VERSION "HNNBNNNYNNNNNNNNNNNNNNNNNNNNNNNNNNNNNNNNNN/4/%%%/4/'%**4NNN///"

NS_ :

BS_:

BU_: AFS AFS_LMod_L AFS_LMod_R BCM1 BVS FCM GLW_LMod_L GLW_LMod_R LCM_L LCM_R LED_DK3_LM_L LED_DK3_LM_R LED_LM_L LED_LM_R LLP_L LLP_R LWR_MXB_L LWR_MXB_R MXB MXB_LM_L MXB_LM_R ZFAS

BO_ 2600468649 NMH_FCM: 8 FCM
 SG_ NM_FCM_Car_Wakeup : 0|1@1+ (1,0) [0|1] "" Vector__XXX

BO_ 924 AFS_Feh_LM_L: 5 AFS_LMod_L
 SG_ FAL_SchMot : 0|1@1+ (1,0) [0|1] ""  AFS,BCM1,FCM
 SG_ FAL_RSchMot : 1|1@1+ (1,0) [0|1] ""  AFS,BCM1,FCM
 SG_ FAL_SM_KS_Gnd : 2|1@1+ (1,0) [0|1] ""  AFS,BCM1,FCM
 SG_ FAL_RSM_KS_Gnd : 3|1@1+ (1,0) [0|1] ""  AFS,BCM1,FCM
 SG_ FAL_SM_UeSpg : 4|1@1+ (1,0) [0|1] ""  AFS,BCM1,FCM
 SG_ FAL_RSM_UeSpg : 5|1@1+ (1,0) [0|1] ""  AFS,BCM1,FCM
 SG_ FAL_SM_USpg : 6|1@1+ (1,0) [0|1] ""  AFS,BCM1,FCM
 SG_ FAL_RSM_USpg : 7|1@1+ (1,0) [0|1] ""  AFS,BCM1,FCM
 SG_ FAL_SM_UeTemp : 8|1@1+ (1,0) [0|1] ""  AFS,BCM1,FCM
 SG_ FAL_RSM_UeTemp : 9|1@1+ (1,0) [0|1] ""  AFS,BCM1,FCM
 SG_ FAL_SM_TempPre : 10|1@1+ (1,0) [0|1] ""  AFS,BCM1,FCM
 SG_ FAL_RSM_TempPre : 11|1@1+ (1,0) [0|1] ""  AFS,BCM1,FCM
 SG_ FAL_EM_UeSpg : 12|1@1+ (1,0) [0|1] ""  AFS,BCM1,FCM
 SG_ FAL_REM_UeSpg : 13|1@1+ (1,0) [0|1] ""  AFS,BCM1,FCM
 SG_ FAL_EM_USpg : 14|1@1+ (1,0) [0|1] ""  AFS,BCM1,FCM
 SG_ FAL_REM_USpg : 15|1@1+ (1,0) [0|1] ""  AFS,BCM1,FCM
 SG_ FAL_EM_defekt : 16|1@1+ (1,0) [0|1] ""  AFS,BCM1,FCM
 SG_ FAL_REM_defekt : 17|1@1+ (1,0) [0|1] ""  AFS,BCM1,FCM
 SG_ FAL_sKL_Lampe : 18|1@1+ (1,0) [0|1] ""  AFS,BCM1,FCM
 SG_ FAL_RsKL_Lampe : 19|1@1+ (1,0) [0|1] ""  AFS,BCM1,FCM
 SG_ FAL_sKL_KS_Gnd : 20|1@1+ (1,0) [0|1] ""  AFS,BCM1,FCM
 SG_ FAL_RsKL_KS_Gnd : 21|1@1+ (1,0) [0|1] ""  AFS,BCM1,FCM
 SG_ FAL_GDL_Modul : 22|1@1+ (1,0) [0|1] ""  AFS,BCM1,FCM
 SG_ FAL_RGDL_Modul : 23|1@1+ (1,0) [0|1] ""  AFS,BCM1,FCM
 SG_ FAL_dKL_KS_Plus : 24|1@1+ (1,0) [0|1] ""  AFS,BCM1,FCM
 SG_ FAL_RdKL_KS_Plus : 25|1@1+ (1,0) [0|1] ""  AFS,BCM1,FCM
 SG_ FAL_dKL_KS_Gnd : 26|1@1+ (1,0) [0|1] ""  AFS,BCM1,FCM
 SG_ FAL_RdKL_KS_Gnd : 27|1@1+ (1,0) [0|1] ""  AFS,BCM1,FCM
 SG_ FAL_dKL_unplSign : 28|1@1+ (1,0) [0|1] ""  AFS,BCM1,FCM
 SG_ FAL_RdKL_unplSign : 29|1@1+ (1,0) [0|1] ""  AFS,BCM1,FCM
 SG_ FAL_5VdKL_KS_Gnd : 30|1@1+ (1,0) [0|1] ""  AFS,BCM1,FCM
 SG_ FAL_R5VdKL_KS_Gnd : 31|1@1+ (1,0) [0|1] ""  AFS,BCM1,FCM
 SG_ FAL_5VdKL_KS_UB : 32|1@1+ (1,0) [0|1] ""  AFS,BCM1,FCM
 SG_ FAL_R5VdKL_KS_UB : 33|1@1+ (1,0) [0|1] ""  AFS,BCM1,FCM

BO_ 926 AFS_Feh_LM_R: 5 AFS_LMod_R
 SG_ FAR_SchMot : 0|1@1+ (1,0) [0|1] ""  AFS,BCM1,FCM
 SG_ FAR_RSchMot : 1|1@1+ (1,0) [0|1] ""  AFS,BCM1,FCM
 SG_ FAR_SM_KS_Gnd : 2|1@1+ (1,0) [0|1] ""  AFS,BCM1,FCM
 SG_ FAR_RSM_KS_Gnd : 3|1@1+ (1,0) [0|1] ""  AFS,BCM1,FCM
 SG_ FAR_SM_UeSpg : 4|1@1+ (1,0) [0|1] ""  AFS,BCM1,FCM
 SG_ FAR_RSM_UeSpg : 5|1@1+ (1,0) [0|1] ""  AFS,BCM1,FCM
 SG_ FAR_SM_USpg : 6|1@1+ (1,0) [0|1] ""  AFS,BCM1,FCM
 SG_ FAR_RSM_USpg : 7|1@1+ (1,0) [0|1] ""  AFS,BCM1,FCM
 SG_ FAR_SM_UeTemp : 8|1@1+ (1,0) [0|1] ""  AFS,BCM1,FCM
 SG_ FAR_RSM_UeTemp : 9|1@1+ (1,0) [0|1] ""  AFS,BCM1,FCM
 SG_ FAR_SM_TempPre : 10|1@1+ (1,0) [0|1] ""  AFS,BCM1,FCM
 SG_ FAR_RSM_TempPre : 11|1@1+ (1,0) [0|1] ""  AFS,BCM1,FCM
 SG_ FAR_EM_UeSpg : 12|1@1+ (1,0) [0|1] ""  AFS,BCM1,FCM
 SG_ FAR_REM_UeSpg : 13|1@1+ (1,0) [0|1] ""  AFS,BCM1,FCM
 SG_ FAR_EM_USpg : 14|1@1+ (1,0) [0|1] ""  AFS,BCM1,FCM
 SG_ FAR_REM_USpg : 15|1@1+ (1,0) [0|1] ""  AFS,BCM1,FCM
 SG_ FAR_EM_defekt : 16|1@1+ (1,0) [0|1] ""  AFS,BCM1,FCM
 SG_ FAR_REM_defekt : 17|1@1+ (1,0) [0|1] ""  AFS,BCM1,FCM
 SG_ FAR_sKL_Lampe : 18|1@1+ (1,0) [0|1] ""  AFS,BCM1,FCM
 SG_ FAR_RsKL_Lampe : 19|1@1+ (1,0) [0|1] ""  AFS,BCM1,FCM
 SG_ FAR_sKL_KS_Gnd : 20|1@1+ (1,0) [0|1] ""  AFS,BCM1,FCM
 SG_ FAR_RsKL_KS_Gnd : 21|1@1+ (1,0) [0|1] ""  AFS,BCM1,FCM
 SG_ FAR_GDL_Modul : 22|1@1+ (1,0) [0|1] ""  AFS,BCM1,FCM
 SG_ FAR_RGDL_Modul : 23|1@1+ (1,0) [0|1] ""  AFS,BCM1,FCM
 SG_ FAR_dKL_KS_Plus : 24|1@1+ (1,0) [0|1] ""  AFS,BCM1,FCM
 SG_ FAR_RdKL_KS_Plus : 25|1@1+ (1,0) [0|1] ""  AFS,BCM1,FCM
 SG_ FAR_dKL_KS_Gnd : 26|1@1+ (1,0) [0|1] ""  AFS,BCM1,FCM
 SG_ FAR_RdKL_KS_Gnd : 27|1@1+ (1,0) [0|1] ""  AFS,BCM1,FCM
 SG_ FAR_dKL_unplSign : 28|1@1+ (1,0) [0|1] ""  AFS,BCM1,FCM
 SG_ FAR_RdKL_unplSign : 29|1@1+ (1,0) [0|1] ""  AFS,BCM1,FCM
 SG_ FAR_5VdKL_KS_Gnd : 30|1@1+ (1,0) [0|1] ""  AFS,BCM1,FCM
 SG_ FAR_R5VdKL_KS_Gnd : 31|1@1+ (1,0) [0|1] ""  AFS,BCM1,FCM
 SG_ FAR_5VdKL_KS_UB : 32|1@1+ (1,0) [0|1] ""  AFS,BCM1,FCM
 SG_ FAR_R5VdKL_KS_UB : 33|1@1+ (1,0) [0|1] ""  AFS,BCM1,FCM

BO_ 1172 AFS_Idt_LM_L: 8 AFS_LMod_L
 SG_ IAL_Mux M : 0|8@1+ (1,0) [0|4] ""  AFS,BCM1,FCM,MXB
 SG_ IAL_SW_Idt_Z01 m0 : 8|8@1+ (1,0) [0|255] ""  AFS,BCM1,FCM,MXB
 SG_ IAL_SW_Idt_Z08 m1 : 8|8@1+ (1,0) [0|255] ""  AFS,BCM1,FCM,MXB
 SG_ IAL_SW_Idx_Z04 m2 : 8|8@1+ (1,0) [0|255] ""  AFS,BCM1,FCM,MXB
 SG_ IAL_HW_Idt_Z07 m3 : 8|8@1+ (1,0) [0|255] ""  AFS,BCM1,FCM,MXB
 SG_ IAL_HW_Idx_Z03 m4 : 8|8@1+ (1,0) [0|255] ""  AFS,BCM1,FCM,MXB
 SG_ IAL_SW_Idt_Z02 m0 : 16|8@1+ (1,0) [0|255] ""  AFS,BCM1,FCM,MXB
 SG_ IAL_SW_Idt_Z09 m1 : 16|8@1+ (1,0) [0|255] ""  AFS,BCM1,FCM,MXB
 SG_ IAL_HW_Idt_Z01 m2 : 16|8@1+ (1,0) [0|255] ""  AFS,BCM1,FCM,MXB
 SG_ IAL_HW_Idt_Z08 m3 : 16|8@1+ (1,0) [0|255] ""  AFS,BCM1,FCM,MXB
 SG_ IAL_SW_Idt_Z03 m0 : 24|8@1+ (1,0) [0|255] ""  AFS,BCM1,FCM,MXB
 SG_ IAL_SW_Idt_Z10 m1 : 24|8@1+ (1,0) [0|255] ""  AFS,BCM1,FCM,MXB
 SG_ IAL_HW_Idt_Z02 m2 : 24|8@1+ (1,0) [0|255] ""  AFS,BCM1,FCM,MXB
 SG_ IAL_HW_Idt_Z09 m3 : 24|8@1+ (1,0) [0|255] ""  AFS,BCM1,FCM,MXB
 SG_ IAL_SW_Idt_Z04 m0 : 32|8@1+ (1,0) [0|255] ""  AFS,BCM1,FCM,MXB
 SG_ IAL_SW_Idt_Z11 m1 : 32|8@1+ (1,0) [0|255] ""  AFS,BCM1,FCM,MXB
 SG_ IAL_HW_Idt_Z03 m2 : 32|8@1+ (1,0) [0|255] ""  AFS,BCM1,FCM,MXB
 SG_ IAL_HW_Idt_Z10 m3 : 32|8@1+ (1,0) [0|255] ""  AFS,BCM1,FCM,MXB
 SG_ IAL_SW_Idt_Z05 m0 : 40|8@1+ (1,0) [0|255] ""  AFS,BCM1,FCM,MXB
 SG_ IAL_SW_Idx_Z01 m1 : 40|8@1+ (1,0) [0|255] ""  AFS,BCM1,FCM,MXB
 SG_ IAL_HW_Idt_Z04 m2 : 40|8@1+ (1,0) [0|255] ""  AFS,BCM1,FCM,MXB
 SG_ IAL_HW_Idt_Z11 m3 : 40|8@1+ (1,0) [0|255] ""  AFS,BCM1,FCM,MXB
 SG_ IAL_SW_Idt_Z06 m0 : 48|8@1+ (1,0) [0|255] ""  AFS,BCM1,FCM,MXB
 SG_ IAL_SW_Idx_Z02 m1 : 48|8@1+ (1,0) [0|255] ""  AFS,BCM1,FCM,MXB
 SG_ IAL_HW_Idt_Z05 m2 : 48|8@1+ (1,0) [0|255] ""  AFS,BCM1,FCM,MXB
 SG_ IAL_HW_Idx_Z01 m3 : 48|8@1+ (1,0) [0|255] ""  AFS,BCM1,FCM,MXB
 SG_ IAL_SW_Idt_Z07 m0 : 56|8@1+ (1,0) [0|255] ""  AFS,BCM1,FCM,MXB
 SG_ IAL_SW_Idx_Z03 m1 : 56|8@1+ (1,0) [0|255] ""  AFS,BCM1,FCM,MXB
 SG_ IAL_HW_Idt_Z06 m2 : 56|8@1+ (1,0) [0|255] ""  AFS,BCM1,FCM,MXB
 SG_ IAL_HW_Idx_Z02 m3 : 56|8@1+ (1,0) [0|255] ""  AFS,BCM1,FCM,MXB

BO_ 1174 AFS_Idt_LM_R: 8 AFS_LMod_R
 SG_ IAR_Mux M : 0|8@1+ (1,0) [0|4] ""  AFS,BCM1,FCM,MXB
 SG_ IAR_SW_Idt_Z01 m0 : 8|8@1+ (1,0) [0|255] ""  AFS,BCM1,FCM,MXB
 SG_ IAR_SW_Idt_Z08 m1 : 8|8@1+ (1,0) [0|255] ""  AFS,BCM1,FCM,MXB
 SG_ IAR_SW_Idx_Z04 m2 : 8|8@1+ (1,0) [0|255] ""  AFS,BCM1,FCM,MXB
 SG_ IAR_HW_Idt_Z07 m3 : 8|8@1+ (1,0) [0|255] ""  AFS,BCM1,FCM,MXB
 SG_ IAR_HW_Idx_Z03 m4 : 8|8@1+ (1,0) [0|255] ""  AFS,BCM1,FCM,MXB
 SG_ IAR_SW_Idt_Z02 m0 : 16|8@1+ (1,0) [0|255] ""  AFS,BCM1,FCM,MXB
 SG_ IAR_SW_Idt_Z09 m1 : 16|8@1+ (1,0) [0|255] ""  AFS,BCM1,FCM,MXB
 SG_ IAR_HW_Idt_Z01 m2 : 16|8@1+ (1,0) [0|255] ""  AFS,BCM1,FCM,MXB
 SG_ IAR_HW_Idt_Z08 m3 : 16|8@1+ (1,0) [0|255] ""  AFS,BCM1,FCM,MXB
 SG_ IAR_SW_Idt_Z03 m0 : 24|8@1+ (1,0) [0|255] ""  AFS,BCM1,FCM,MXB
 SG_ IAR_SW_Idt_Z10 m1 : 24|8@1+ (1,0) [0|255] ""  AFS,BCM1,FCM,MXB
 SG_ IAR_HW_Idt_Z02 m2 : 24|8@1+ (1,0) [0|255] ""  AFS,BCM1,FCM,MXB
 SG_ IAR_HW_Idt_Z09 m3 : 24|8@1+ (1,0) [0|255] ""  AFS,BCM1,FCM,MXB
 SG_ IAR_SW_Idt_Z04 m0 : 32|8@1+ (1,0) [0|255] ""  AFS,BCM1,FCM,MXB
 SG_ IAR_SW_Idt_Z11 m1 : 32|8@1+ (1,0) [0|255] ""  AFS,BCM1,FCM,MXB
 SG_ IAR_HW_Idt_Z03 m2 : 32|8@1+ (1,0) [0|255] ""  AFS,BCM1,FCM,MXB
 SG_ IAR_HW_Idt_Z10 m3 : 32|8@1+ (1,0) [0|255] ""  AFS,BCM1,FCM,MXB
 SG_ IAR_SW_Idt_Z05 m0 : 40|8@1+ (1,0) [0|255] ""  AFS,BCM1,FCM,MXB
 SG_ IAR_SW_Idx_Z01 m1 : 40|8@1+ (1,0) [0|255] ""  AFS,BCM1,FCM,MXB
 SG_ IAR_HW_Idt_Z04 m2 : 40|8@1+ (1,0) [0|255] ""  AFS,BCM1,FCM,MXB
 SG_ IAR_HW_Idt_Z11 m3 : 40|8@1+ (1,0) [0|255] ""  AFS,BCM1,FCM,MXB
 SG_ IAR_SW_Idt_Z06 m0 : 48|8@1+ (1,0) [0|255] ""  AFS,BCM1,FCM,MXB
 SG_ IAR_SW_Idx_Z02 m1 : 48|8@1+ (1,0) [0|255] ""  AFS,BCM1,FCM,MXB
 SG_ IAR_HW_Idt_Z05 m2 : 48|8@1+ (1,0) [0|255] ""  AFS,BCM1,FCM,MXB
 SG_ IAR_HW_Idx_Z01 m3 : 48|8@1+ (1,0) [0|255] ""  AFS,BCM1,FCM,MXB
 SG_ IAR_SW_Idt_Z07 m0 : 56|8@1+ (1,0) [0|255] ""  AFS,BCM1,FCM,MXB
 SG_ IAR_SW_Idx_Z03 m1 : 56|8@1+ (1,0) [0|255] ""  AFS,BCM1,FCM,MXB
 SG_ IAR_HW_Idt_Z06 m2 : 56|8@1+ (1,0) [0|255] ""  AFS,BCM1,FCM,MXB
 SG_ IAR_HW_Idx_Z02 m3 : 56|8@1+ (1,0) [0|255] ""  AFS,BCM1,FCM,MXB

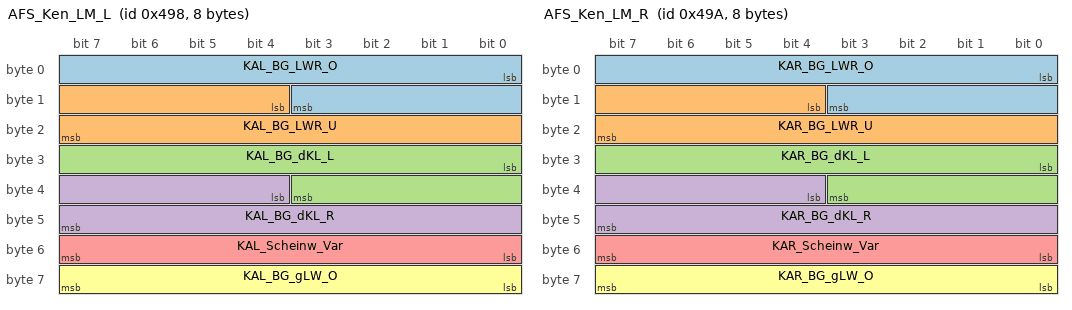
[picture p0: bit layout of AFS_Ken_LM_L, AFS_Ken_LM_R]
BO_ 1176 AFS_Ken_LM_L: 8 AFS_LMod_L
 SG_ KAL_BG_LWR_O : 0|12@1+ (0.5,-1023) [-1023|1022.5] "Unit_MilliMeter"  AFS,BCM1,FCM,MXB
 SG_ KAL_BG_LWR_U : 12|12@1+ (0.5,-1023) [-1023|1022.5] "Unit_MilliMeter"  AFS,BCM1,FCM,MXB
 SG_ KAL_BG_dKL_L : 24|12@1+ (0.015625,-31.96875) [-31.96875|31.953125] "Unit_DegreOfArc"  AFS,BCM1,FCM
 SG_ KAL_BG_dKL_R : 36|12@1+ (0.015625,-31.96875) [-31.96875|31.953125] "Unit_DegreOfArc"  AFS,BCM1,FCM
 SG_ KAL_Scheinw_Var : 48|8@1+ (1,0) [0|255] ""  AFS,BCM1,FCM
 SG_ KAL_BG_gLW_O : 56|8@1+ (0.1,75) [75|100] "Unit_PerCent"  AFS,BCM1,FCM

BO_ 1184 AFS_Ken_LM_L_02: 8 AFS_LMod_L
 SG_ AFS_L_Scheinw_Var_1 : 12|8@1+ (1,0) [0|255] ""  AFS,BCM1,FCM
 SG_ AFS_L_Scheinw_Var_2 : 20|8@1+ (1,0) [0|255] ""  AFS,BCM1,FCM

BO_ 1178 AFS_Ken_LM_R: 8 AFS_LMod_R
 SG_ KAR_BG_LWR_O : 0|12@1+ (0.5,-1023) [-1023|1022.5] "Unit_MilliMeter"  AFS,BCM1,FCM,MXB
 SG_ KAR_BG_LWR_U : 12|12@1+ (0.5,-1023) [-1023|1022.5] "Unit_MilliMeter"  AFS,BCM1,FCM,MXB
 SG_ KAR_BG_dKL_L : 24|12@1+ (0.015625,-31.96875) [-31.96875|31.953125] "Unit_DegreOfArc"  AFS,BCM1,FCM
 SG_ KAR_BG_dKL_R : 36|12@1+ (0.015625,-31.96875) [-31.96875|31.953125] "Unit_DegreOfArc"  AFS,BCM1,FCM
 SG_ KAR_Scheinw_Var : 48|8@1+ (1,0) [0|255] ""  AFS,BCM1,FCM
 SG_ KAR_BG_gLW_O : 56|8@1+ (0.1,75) [75|100] "Unit_PerCent"  AFS,BCM1,FCM

BO_ 1185 AFS_Ken_LM_R_02: 8 AFS_LMod_R
 SG_ AFS_R_Scheinw_Var_1 : 12|8@1+ (1,0) [0|255] ""  AFS,BCM1,FCM
 SG_ AFS_R_Scheinw_Var_2 : 20|8@1+ (1,0) [0|255] ""  AFS,BCM1,FCM

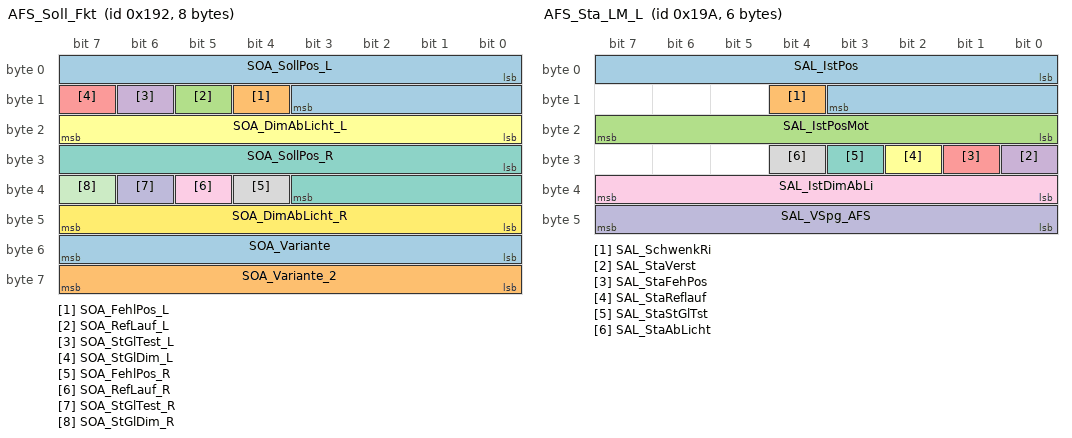
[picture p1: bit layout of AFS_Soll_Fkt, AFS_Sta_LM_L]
BO_ 402 AFS_Soll_Fkt: 8 AFS
 SG_ SOA_SollPos_L : 0|12@1+ (0.015625,-31.96875) [-31.96875|31.953125] "Unit_DegreOfArc"  AFS_LMod_L,BVS,GLW_LMod_L,LCM_L,LLP_L,ZFAS
 SG_ SOA_FehlPos_L : 12|1@1+ (1,0) [0|1] ""  AFS_LMod_L,BVS,GLW_LMod_L,LCM_L,LLP_L,ZFAS
 SG_ SOA_RefLauf_L : 13|1@1+ (1,0) [0|1] ""  AFS_LMod_L,BVS,GLW_LMod_L,LCM_L,LLP_L,ZFAS
 SG_ SOA_StGlTest_L : 14|1@1+ (1,0) [0|1] ""  AFS_LMod_L,BVS,GLW_LMod_L,LCM_L,LLP_L,ZFAS
 SG_ SOA_StGlDim_L : 15|1@1+ (1,0) [0|1] ""  AFS_LMod_L,BVS,GLW_LMod_L,LCM_L,LLP_L,ZFAS
 SG_ SOA_DimAbLicht_L : 16|8@1+ (0.4,0) [0|100] "Unit_PerCent"  AFS_LMod_L,BVS,GLW_LMod_L,LCM_L,LLP_L,ZFAS
 SG_ SOA_SollPos_R : 24|12@1+ (0.015625,-31.96875) [-31.96875|31.953125] "Unit_DegreOfArc"  AFS_LMod_R,BVS,GLW_LMod_R,LCM_R,LLP_R,ZFAS
 SG_ SOA_FehlPos_R : 36|1@1+ (1,0) [0|1] ""  AFS_LMod_R,BVS,GLW_LMod_R,LCM_R,LLP_R,ZFAS
 SG_ SOA_RefLauf_R : 37|1@1+ (1,0) [0|1] ""  AFS_LMod_R,BVS,GLW_LMod_R,LCM_R,LLP_R,ZFAS
 SG_ SOA_StGlTest_R : 38|1@1+ (1,0) [0|1] ""  AFS_LMod_R,BVS,GLW_LMod_R,LCM_R,LLP_R,ZFAS
 SG_ SOA_StGlDim_R : 39|1@1+ (1,0) [0|1] ""  AFS_LMod_R,BVS,GLW_LMod_R,LCM_R,LLP_R,ZFAS
 SG_ SOA_DimAbLicht_R : 40|8@1+ (0.4,0) [0|100] "Unit_PerCent"  AFS_LMod_R,BVS,GLW_LMod_R,LCM_R,LLP_R,ZFAS
 SG_ SOA_Variante : 48|8@1+ (1,0) [0|255] ""  AFS_LMod_L,AFS_LMod_R,BVS,GLW_LMod_L,GLW_LMod_R,LCM_L,LCM_R,LED_DK3_LM_L,LED_DK3_LM_R,LED_LM_L,LED_LM_R,LLP_L,LLP_R,LWR_MXB_L,LWR_MXB_R,MXB_LM_L,MXB_LM_R,ZFAS
 SG_ SOA_Variante_2 : 56|8@1+ (1,0) [0|255] ""  AFS_LMod_L,AFS_LMod_R,BVS,GLW_LMod_L,GLW_LMod_R,LCM_L,LCM_R,LED_DK3_LM_L,LED_DK3_LM_R,LED_LM_L,LED_LM_R,LLP_L,LLP_R,LWR_MXB_L,LWR_MXB_R,MXB_LM_L,MXB_LM_R,ZFAS

BO_ 410 AFS_Sta_LM_L: 6 AFS_LMod_L
 SG_ SAL_IstPos : 0|12@1+ (0.015625,-31.96875) [-31.96875|31.953125] "Unit_DegreOfArc"  AFS,BCM1,FCM
 SG_ SAL_SchwenkRi : 12|1@1+ (1,0) [0|1] ""  AFS,BCM1,FCM
 SG_ SAL_IstPosMot : 16|8@1+ (0.4,0) [0|100] "Unit_PerCent"  AFS,BCM1,FCM
 SG_ SAL_StaVerst : 24|1@1+ (1,0) [0|1] ""  AFS,BCM1,FCM
 SG_ SAL_StaFehPos : 25|1@1+ (1,0) [0|1] ""  AFS,BCM1,FCM
 SG_ SAL_StaReflauf : 26|1@1+ (1,0) [0|1] ""  AFS,BCM1,FCM
 SG_ SAL_StaStGlTst : 27|1@1+ (1,0) [0|1] ""  AFS,BCM1,FCM
 SG_ SAL_StaAbLicht : 28|1@1+ (1,0) [0|1] ""  AFS,BCM1,FCM
 SG_ SAL_IstDimAbLi : 32|8@1+ (0.4,0) [0|100] "Unit_PerCent"  AFS,BCM1,FCM
 SG_ SAL_VSpg_AFS : 40|8@1+ (0.08,0) [0|20.24] "Unit_Volt"  AFS,BCM1,FCM

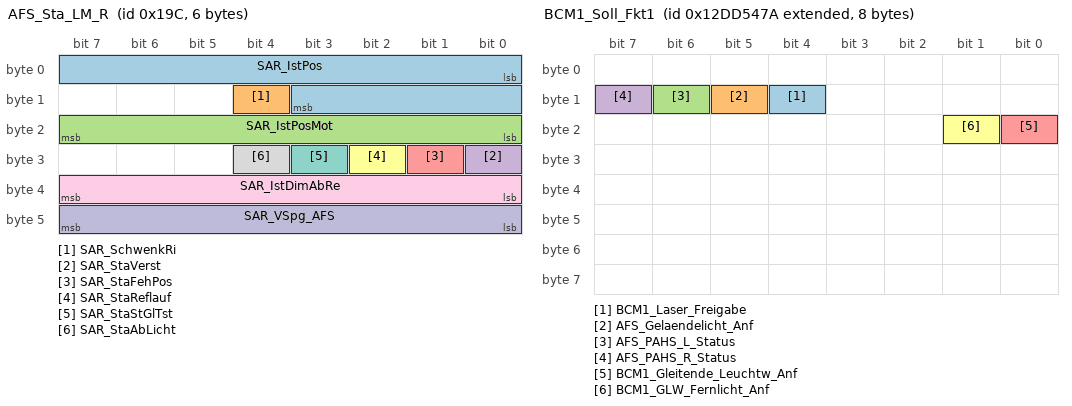
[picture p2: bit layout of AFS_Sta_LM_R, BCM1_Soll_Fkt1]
BO_ 412 AFS_Sta_LM_R: 6 AFS_LMod_R
 SG_ SAR_IstPos : 0|12@1+ (0.015625,-31.96875) [-31.96875|31.953125] "Unit_DegreOfArc"  AFS,BCM1,FCM
 SG_ SAR_SchwenkRi : 12|1@1+ (1,0) [0|1] ""  AFS,BCM1,FCM
 SG_ SAR_IstPosMot : 16|8@1+ (0.4,0) [0|100] "Unit_PerCent"  AFS,BCM1,FCM
 SG_ SAR_StaVerst : 24|1@1+ (1,0) [0|1] ""  AFS,BCM1,FCM
 SG_ SAR_StaFehPos : 25|1@1+ (1,0) [0|1] ""  AFS,BCM1,FCM
 SG_ SAR_StaReflauf : 26|1@1+ (1,0) [0|1] ""  AFS,BCM1,FCM
 SG_ SAR_StaStGlTst : 27|1@1+ (1,0) [0|1] ""  AFS,BCM1,FCM
 SG_ SAR_StaAbLicht : 28|1@1+ (1,0) [0|1] ""  AFS,BCM1,FCM
 SG_ SAR_IstDimAbRe : 32|8@1+ (0.4,0) [0|100] "Unit_PerCent"  AFS,BCM1,FCM
 SG_ SAR_VSpg_AFS : 40|8@1+ (0.08,0) [0|20.24] "Unit_Volt"  AFS,BCM1,FCM

BO_ 64 Airbag_01: 8 BCM1
 SG_ Airbag_01_CRC : 0|8@1+ (1,0) [0|255] ""  LED_DK3_LM_L,LED_DK3_LM_R,LLP_L,LLP_R
 SG_ Airbag_01_BZ : 8|4@1+ (1,0) [0|15] ""  LED_DK3_LM_L,LED_DK3_LM_R,LLP_L,LLP_R
 SG_ AB_RGS_Anst : 12|4@1+ (1,0) [0|15] "" Vector__XXX
 SG_ AB_Front_Crash : 16|1@1+ (1,0) [0|1] ""  LED_DK3_LM_L,LED_DK3_LM_R,LLP_L,LLP_R
 SG_ AB_Heck_Crash : 17|1@1+ (1,0) [0|1] "" Vector__XXX
 SG_ AB_SF_Crash : 18|1@1+ (1,0) [0|1] "" Vector__XXX
 SG_ AB_SB_Crash : 19|1@1+ (1,0) [0|1] "" Vector__XXX
 SG_ AB_Rollover_Crash : 20|1@1+ (1,0) [0|1] "" Vector__XXX
 SG_ AB_Crash_Int : 21|3@1+ (1,0) [0|7] ""  LED_DK3_LM_L,LED_DK3_LM_R,LLP_L,LLP_R
 SG_ AB_Lampe : 24|1@1+ (1,0) [0|1] "" Vector__XXX
 SG_ AB_Deaktiviert : 25|1@1+ (1,0) [0|1] "" Vector__XXX
 SG_ AB_VB_deaktiviert : 26|1@1+ (1,0) [0|1] "" Vector__XXX
 SG_ AB_Systemfehler : 27|1@1+ (1,0) [0|1] "" Vector__XXX
 SG_ AB_Diagnose : 28|1@1+ (1,0) [0|1] ""  LED_DK3_LM_L,LED_DK3_LM_R,LLP_L,LLP_R
 SG_ AB_Stellgliedtest : 29|1@1+ (1,0) [0|1] ""  LED_DK3_LM_L,LED_DK3_LM_R,LLP_L,LLP_R
 SG_ AB_Erh_Auf_VB : 30|2@1+ (1,0) [0|3] ""  LED_DK3_LM_L,LED_DK3_LM_R,LLP_L,LLP_R
 SG_ AB_Gurtwarn_VF : 32|1@1+ (1,0) [0|1] "" Vector__XXX
 SG_ AB_Gurtwarn_VB : 33|1@1+ (1,0) [0|1] "" Vector__XXX
 SG_ AB_Anzeige_Fussg : 34|2@1+ (1,0) [0|3] "" Vector__XXX
 SG_ AB_Texte_AKS : 36|2@1+ (1,0) [0|3] "" Vector__XXX
 SG_ AB_MKB_gueltig : 39|1@1+ (1,0) [0|1] "" Vector__XXX
 SG_ AB_MKB_Anforderung : 40|1@1+ (1,0) [0|1] "" Vector__XXX
 SG_ AB_Versorgungsspannung : 41|1@1+ (1,0) [0|1] "" Vector__XXX
 SG_ AB_Deaktivierung_HV : 42|3@1+ (1,0) [0|7] "" Vector__XXX
 SG_ AB_EDR_Trigger : 45|2@1+ (1,0) [0|3] "" Vector__XXX
 SG_ SC_Masterzeit_Offset : 53|2@1+ (5.08,0) [0|15.24] "Unit_Secon" Vector__XXX
 SG_ SC_LowSpeedCrashErkannt : 55|2@1+ (1,0) [0|3] "" Vector__XXX
 SG_ SC_Masterzeit : 57|7@1+ (0.04,0) [0|5.04] "Unit_Secon" Vector__XXX

BO_ 2463978618 BCM1_Soll_Fkt1: 8 BCM1
 SG_ BCM1_Laser_Freigabe : 12|1@1+ (1,0) [0|1] ""  ZFAS
 SG_ AFS_Gelaendelicht_Anf : 13|1@1+ (1,0) [0|1] ""  ZFAS
 SG_ AFS_PAHS_L_Status : 14|1@1+ (1,0) [0|1] ""  ZFAS
 SG_ AFS_PAHS_R_Status : 15|1@1+ (1,0) [0|1] ""  ZFAS
 SG_ BCM1_Gleitende_Leuchtw_Anf : 16|1@1+ (1,0) [0|1] ""  ZFAS
 SG_ BCM1_GLW_Fernlicht_Anf : 17|1@1+ (1,0) [0|1] ""  ZFAS

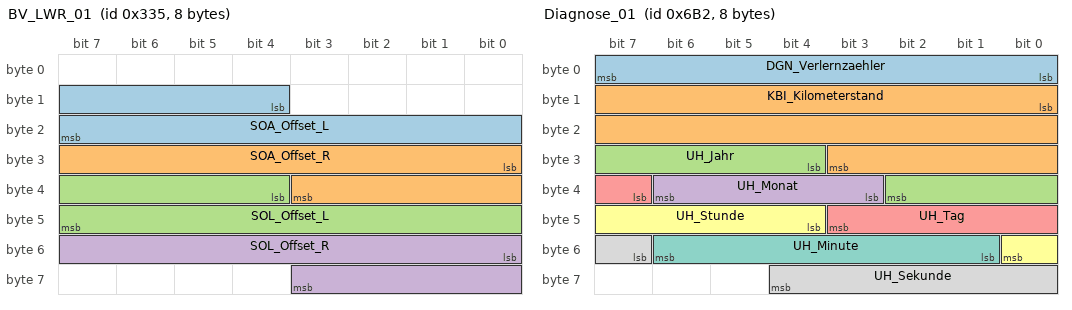
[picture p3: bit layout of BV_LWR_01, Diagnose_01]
BO_ 821 BV_LWR_01: 8 BVS
 SG_ SOA_Offset_L : 12|12@1+ (0.015626,-2046) [-2046|-1982.074034] "Unit_DegreOfArc"  BCM1
 SG_ SOA_Offset_R : 24|12@1+ (0.015626,-2046) [-2046|-1982.074034] "Unit_DegreOfArc"  BCM1
 SG_ SOL_Offset_L : 36|12@1+ (0.5,-1023) [-1023|1022.5] "Unit_MilliMeter"  BCM1
 SG_ SOL_Offset_R : 48|12@1+ (0.5,-1023) [-1023|1022.5] "Unit_MilliMeter"  BCM1

BO_ 2616988416 DEV_LCM_L_00: 8 LCM_L
 SG_ DEV_LCM_L_00_Data : 0|64@1+ (1,0) [0|1.84467440737096E+019] "" Vector__XXX

BO_ 2616988671 DEV_LCM_L_FF: 8 LCM_L
 SG_ DEV_LCM_L_FF_Data : 0|64@1+ (1,0) [0|1.84467440737096E+019] "" Vector__XXX

BO_ 2616990464 DEV_LCM_R_00: 8 LCM_R
 SG_ DEV_LCM_R_00_Data : 0|64@1+ (1,0) [0|1.84467440737096E+019] "" Vector__XXX

BO_ 2616990719 DEV_LCM_R_FF: 8 LCM_R
 SG_ DEV_LCM_R_FF_Data : 0|64@1+ (1,0) [0|1.84467440737096E+019] "" Vector__XXX

BO_ 2617029376 DEV_LED_DK3_L_00: 8 LED_DK3_LM_L
 SG_ DEV_LED_DK3_L_00_Data : 0|64@1+ (1,0) [0|1.84467440737096E+019] "" Vector__XXX

BO_ 2617029631 DEV_LED_DK3_L_FF: 8 LED_DK3_LM_L
 SG_ DEV_LED_DK3_L_FF_Data : 0|64@1+ (1,0) [0|1.84467440737096E+019] "" Vector__XXX

BO_ 2617031424 DEV_LED_DK3_R_00: 8 LED_DK3_LM_R
 SG_ DEV_LED_DK3_R_00_Data : 0|64@1+ (1,0) [0|1.84467440737096E+019] "" Vector__XXX

BO_ 2617031679 DEV_LED_DK3_R_FF: 8 LED_DK3_LM_R
 SG_ DEV_LED_DK3_R_FF_Data : 0|64@1+ (1,0) [0|1.84467440737096E+019] "" Vector__XXX

BO_ 2549880340 DIA_gLW_LM_L_Req: 8 AFS
 SG_ DIA_gLW_LM_L_Req_Data : 0|64@1+ (1,0) [0|1.84467440737096E+019] ""  GLW_LMod_L

BO_ 2550011412 DIA_gLW_LM_L_Resp: 8 GLW_LMod_L
 SG_ DIA_gLW_LM_L_Resp_Data : 0|64@1+ (1,0) [0|1.84467440737096E+019] ""  AFS,BCM1

BO_ 2549880341 DIA_gLW_LM_R_Req: 8 AFS
 SG_ DIA_gLW_LM_R_Req_Data : 0|64@1+ (1,0) [0|1.84467440737096E+019] ""  GLW_LMod_R

BO_ 2550011413 DIA_gLW_LM_R_Resp: 8 GLW_LMod_R
 SG_ DIA_gLW_LM_R_Resp_Data : 0|64@1+ (1,0) [0|1.84467440737096E+019] ""  AFS,BCM1

BO_ 2549880330 DIA_LED_LM_L_Req: 8 AFS
 SG_ DIA_LED_LM_L_Req_Data : 0|64@1+ (1,0) [0|1.84467440737096E+019] ""  LED_DK3_LM_L,LED_LM_L

BO_ 2550011402 DIA_LED_LM_L_Resp: 8 LED_DK3_LM_L
 SG_ DIA_LED_LM_L_Resp_Data : 0|64@1+ (1,0) [0|1.84467440737096E+019] ""  AFS,BCM1,FCM,MXB

BO_ 2549880331 DIA_LED_LM_R_Req: 8 AFS
 SG_ DIA_LED_LM_R_Req_Data : 0|64@1+ (1,0) [0|1.84467440737096E+019] ""  LED_DK3_LM_R,LED_LM_R

BO_ 2550011403 DIA_LED_LM_R_Resp: 8 LED_DK3_LM_R
 SG_ DIA_LED_LM_R_Resp_Data : 0|64@1+ (1,0) [0|1.84467440737096E+019] ""  AFS,BCM1,FCM,MXB

BO_ 2549880427 DIA_MXB_LM_L_Req: 8 AFS
 SG_ DIA_MXB_LM_L_Req_Data : 0|64@1+ (1,0) [0|1.84467440737096E+019] ""  MXB_LM_L

BO_ 2550011499 DIA_MXB_LM_L_Resp: 8 MXB_LM_L
 SG_ DIA_MXB_LM_L_Resp_Data : 0|64@1+ (1,0) [0|1.84467440737096E+019] ""  AFS,BCM1,FCM,MXB

BO_ 2549880428 DIA_MXB_LM_R_Req: 8 AFS
 SG_ DIA_MXB_LM_R_Req_Data : 0|64@1+ (1,0) [0|1.84467440737096E+019] ""  MXB_LM_R

BO_ 2550011500 DIA_MXB_LM_R_Resp: 8 MXB_LM_R
 SG_ DIA_MXB_LM_R_Resp_Data : 0|64@1+ (1,0) [0|1.84467440737096E+019] ""  AFS,BCM1,FCM,MXB

BO_ 1714 Diagnose_01: 8 AFS
 SG_ DGN_Verlernzaehler : 0|8@1+ (1,0) [0|254] ""  LCM_L,LCM_R,LED_DK3_LM_L,LED_DK3_LM_R,LLP_L,LLP_R
 SG_ KBI_Kilometerstand : 8|20@1+ (1,0) [0|1048573] "Unit_KiloMeter"  LCM_L,LCM_R,LED_DK3_LM_L,LED_DK3_LM_R,LLP_L,LLP_R
 SG_ UH_Jahr : 28|7@1+ (1,2000) [2000|2127] "Unit_Year"  LCM_L,LCM_R,LED_DK3_LM_L,LED_DK3_LM_R,LLP_L,LLP_R
 SG_ UH_Monat : 35|4@1+ (1,0) [1|12] "Unit_Month"  LCM_L,LCM_R,LED_DK3_LM_L,LED_DK3_LM_R,LLP_L,LLP_R
 SG_ UH_Tag : 39|5@1+ (1,0) [1|31] "Unit_Day"  LCM_L,LCM_R,LED_DK3_LM_L,LED_DK3_LM_R,LLP_L,LLP_R
 SG_ UH_Stunde : 44|5@1+ (1,0) [0|23] "Unit_Hours"  LCM_L,LCM_R,LED_DK3_LM_L,LED_DK3_LM_R,LLP_L,LLP_R
 SG_ UH_Minute : 49|6@1+ (1,0) [0|59] "Unit_Minut"  LCM_L,LCM_R,LED_DK3_LM_L,LED_DK3_LM_R,LLP_L,LLP_R
 SG_ UH_Sekunde : 55|6@1+ (1,0) [0|59] "Unit_Secon"  LCM_L,LCM_R,LED_DK3_LM_L,LED_DK3_LM_R,LLP_L,LLP_R

BO_ 253 ESP_21: 8 AFS
 SG_ ESP_21_CRC : 0|8@1+ (1,0) [0|255] ""  LED_DK3_LM_L,LED_DK3_LM_R,LLP_L,LLP_R
 SG_ ESP_21_BZ : 8|4@1+ (1,0) [0|15] ""  LED_DK3_LM_L,LED_DK3_LM_R,LLP_L,LLP_R
 SG_ BR_Eingriffsmoment : 12|10@1+ (1,-509) [-509|509] "" Vector__XXX
 SG_ ESP_PLA_Bremseingriff : 22|1@1+ (1,0) [0|1] "" Vector__XXX
 SG_ ESP_Diagnose : 23|1@1+ (1,0) [0|1] "" Vector__XXX
 SG_ ESC_v_Signal_Qualifier_High_Low : 24|3@1+ (1,0) [0|7] ""  LED_DK3_LM_L,LED_DK3_LM_R,LLP_L,LLP_R
 SG_ ESP_Vorsteuerung : 28|1@1+ (1,0) [0|1] "" Vector__XXX
 SG_ OBD_Schlechtweg : 30|1@1+ (1,0) [0|1] "" Vector__XXX
 SG_ OBD_QBit_Schlechtweg : 31|1@1+ (1,0) [0|1] "" Vector__XXX
 SG_ ESP_v_Signal : 32|16@1+ (0.01,0) [0|655.32] "Unit_KiloMeterPerHour"  LCM_L,LCM_R,LED_DK3_LM_L,LED_DK3_LM_R,LLP_L,LLP_R
 SG_ ASR_Tastung_passiv : 48|1@1+ (1,0) [0|1] "" Vector__XXX
 SG_ ESP_Tastung_passiv : 49|1@1+ (1,0) [0|1] "" Vector__XXX
 SG_ ESP_Systemstatus : 50|1@1+ (1,0) [0|1] "" Vector__XXX
 SG_ ASR_Schalteingriff : 51|2@1+ (1,0) [0|3] "" Vector__XXX
 SG_ ESP_Haltebestaetigung : 53|1@1+ (1,0) [0|1] "" Vector__XXX
 SG_ ESP_MKB_Abbruch_Geschw : 54|1@1+ (1,0) [0|1] "" Vector__XXX
 SG_ ESP_QBit_v_Signal : 55|1@1+ (1,0) [0|1] "" Vector__XXX
 SG_ ABS_Bremsung : 56|1@1+ (1,0) [0|1] "" Vector__XXX
 SG_ ASR_Anf : 57|1@1+ (1,0) [0|1] "" Vector__XXX
 SG_ MSR_Anf : 58|1@1+ (1,0) [0|1] "" Vector__XXX
 SG_ EBV_Eingriff : 59|1@1+ (1,0) [0|1] "" Vector__XXX
 SG_ EDS_Eingriff : 60|1@1+ (1,0) [0|1] "" Vector__XXX
 SG_ ESP_Eingriff : 61|1@1+ (1,0) [0|1] "" Vector__XXX
 SG_ ESP_ASP : 62|1@1+ (1,0) [0|1] "" Vector__XXX

BO_ 918 GLW_Feh_LM_L: 5 GLW_LMod_L
 SG_ FGL_Akt_KS_Plus : 0|1@1+ (1,0) [0|1] ""  AFS,BCM1,FCM
 SG_ FGL_RAkt_KS_Plus : 1|1@1+ (1,0) [0|1] ""  AFS,BCM1,FCM
 SG_ FGL_Akt_KS_Gnd : 2|1@1+ (1,0) [0|1] ""  AFS,BCM1,FCM
 SG_ FGL_RAkt_KS_Gnd : 3|1@1+ (1,0) [0|1] ""  AFS,BCM1,FCM
 SG_ FGL_Akt_OL : 4|1@1+ (1,0) [0|1] ""  AFS,BCM1,FCM
 SG_ FGL_RAkt_OL : 5|1@1+ (1,0) [0|1] ""  AFS,BCM1,FCM
 SG_ FGL_Akt_UeSpg : 6|1@1+ (1,0) [0|1] ""  AFS,BCM1,FCM
 SG_ FGL_RAkt_UeSpg : 7|1@1+ (1,0) [0|1] ""  AFS,BCM1,FCM
 SG_ FGL_Akt_USpg : 8|1@1+ (1,0) [0|1] ""  AFS,BCM1,FCM
 SG_ FGL_RAkt_USpg : 9|1@1+ (1,0) [0|1] ""  AFS,BCM1,FCM
 SG_ FGL_Akt_UeTemp : 10|1@1+ (1,0) [0|1] ""  AFS,BCM1,FCM
 SG_ FGL_RAkt_UeTemp : 11|1@1+ (1,0) [0|1] ""  AFS,BCM1,FCM
 SG_ FGL_Akt_TempPre : 12|1@1+ (1,0) [0|1] ""  AFS,BCM1,FCM
 SG_ FGL_RAkt_TempPre : 13|1@1+ (1,0) [0|1] ""  AFS,BCM1,FCM
 SG_ FGL_HS_KS_Plus : 18|1@1+ (1,0) [0|1] ""  AFS,BCM1,FCM
 SG_ FGL_RHS_KS_Plus : 19|1@1+ (1,0) [0|1] ""  AFS,BCM1,FCM
 SG_ FGL_HS_KS_Gnd : 20|1@1+ (1,0) [0|1] ""  AFS,BCM1,FCM
 SG_ FGL_RHS_KS_Gnd : 21|1@1+ (1,0) [0|1] ""  AFS,BCM1,FCM
 SG_ FGL_HS_unplSign : 22|1@1+ (1,0) [0|1] ""  AFS,BCM1,FCM
 SG_ FGL_RHS_unplSign : 23|1@1+ (1,0) [0|1] ""  AFS,BCM1,FCM
 SG_ FGL_LIN_Def : 24|1@1+ (1,0) [0|1] ""  AFS,BCM1,FCM
 SG_ FGL_LIN_Timeout : 25|1@1+ (1,0) [0|1] ""  AFS,BCM1,FCM
 SG_ FGL_RLIN_Def : 26|1@1+ (1,0) [0|1] ""  AFS,BCM1,FCM
 SG_ FGL_RLIN_Timeout : 27|1@1+ (1,0) [0|1] ""  AFS,BCM1,FCM

BO_TX_BU_ 924 : AFS_LMod_L,GLW_LMod_L,LWR_MXB_L;
BO_TX_BU_ 926 : AFS_LMod_R,GLW_LMod_R;
BO_TX_BU_ 1172 : AFS_LMod_L,GLW_LMod_L,LWR_MXB_L;
BO_TX_BU_ 1174 : AFS_LMod_R,GLW_LMod_R,LWR_MXB_R;
BO_TX_BU_ 1176 : AFS_LMod_L,GLW_LMod_L,LWR_MXB_L;
BO_TX_BU_ 1184 : AFS_LMod_L,GLW_LMod_L,LWR_MXB_L;
BO_TX_BU_ 1178 : AFS_LMod_R,GLW_LMod_R,LWR_MXB_R;
BO_TX_BU_ 1185 : AFS_LMod_R,GLW_LMod_R,LWR_MXB_R;
BO_TX_BU_ 402 : AFS,BCM1,FCM,MXB;
BO_TX_BU_ 410 : AFS_LMod_L,GLW_LMod_L,LCM_L,LLP_L,LWR_MXB_L;
BO_TX_BU_ 412 : AFS_LMod_R,GLW_LMod_R,LCM_R,LLP_R,LWR_MXB_R;
BO_TX_BU_ 821 : BVS,ZFAS;
BO_TX_BU_ 2617029376 : LED_DK3_LM_L,LLP_L;
BO_TX_BU_ 2617029631 : LED_DK3_LM_L,LLP_L;
BO_TX_BU_ 2617031424 : LED_DK3_LM_R,LLP_R;
BO_TX_BU_ 2617031679 : LED_DK3_LM_R,LLP_R;
BO_TX_BU_ 2549880340 : AFS,BCM1;
BO_TX_BU_ 2549880341 : AFS,BCM1;
BO_TX_BU_ 2549880330 : AFS,BCM1,FCM,MXB;
BO_TX_BU_ 2549880331 : AFS,BCM1,FCM,MXB;
BO_TX_BU_ 2549880427 : AFS,BCM1,FCM,MXB;
BO_TX_BU_ 2549880428 : AFS,BCM1,FCM,MXB;
BO_TX_BU_ 1714 : AFS,BCM1,FCM,MXB;
BO_TX_BU_ 253 : AFS,BCM1,FCM,MXB;

CM_ "AFSCAN_V1.11F Generated by BUSNET NG Produktiv 9.4.2";
CM_ BU_ AFS_LMod_L "Bei Änderungen immer Rücksprache mit Fachabteilung (bestehende Module in Serie)";
CM_ BU_ AFS_LMod_R "Bei Änderungen immer Rücksprache mit Fachabteilung (bestehende Module in Serie)";
CM_ BU_ BVS "Bildverarbeitungssteuergerät";
CM_ BU_ FCM "Function Control Module";
CM_ BU_ GLW_LMod_L "Bei Änderungen immer Rücksprache mit Fachabteilung (bestehende Module in Serie)";
CM_ BU_ GLW_LMod_R "Bei Änderungen immer Rücksprache mit Fachabteilung (bestehende Module in Serie)";
CM_ BU_ LED_DK3_LM_L "Abblendlicht";
CM_ BU_ LED_DK3_LM_R "Abblendlicht";
CM_ BU_ LED_LM_L "Abblendlicht";
CM_ BU_ LED_LM_R "Abblendlicht";
CM_ BU_ LLP_L "Abblendlicht";
CM_ BU_ LLP_R "Abblendlicht";
CM_ BU_ MXB "Matrix-Beam AB3 & TT3";
CM_ BU_ MXB_LM_L "Matrix-Beam-Fernlicht";
CM_ BU_ MXB_LM_R "Matrix-Beam-Fernlicht";
CM_ BU_ ZFAS "Zentrales Fahrerassistenz Steuergeraet";
CM_ SG_ 924 FAL_SchMot "Kurzschluss nach Plus
Offene Leitung
Kurzschluß gegeneinander";
CM_ SG_ 924 FAL_RSchMot "Das Readyness-Bit dient als Indikator dafür, das der Fehlerbaum sauber durchlaufen wurde. Erst beim Setzen des Readyness-Bits auf '0' wird das dazugehörige Fehlerbit gesetzt";
CM_ SG_ 924 FAL_SM_KS_Gnd "Kurzschluss nach Masse";
CM_ SG_ 924 FAL_RSM_KS_Gnd "Das Readyness-Bit dient als Indikator dafür, das der Fehlerbaum sauber durchlaufen wurde. Erst beim Setzen des Readyness-Bits auf '0' wird das dazugehörige Fehlerbit gesetzt";
CM_ SG_ 924 FAL_SM_UeSpg "Abschaltung Schrittmotor Überspannung";
CM_ SG_ 924 FAL_RSM_UeSpg "Das Readyness-Bit dient als Indikator dafür, das der Fehlerbaum sauber durchlaufen wurde. Erst beim Setzen des Readyness-Bits auf '0' wird das dazugehörige Fehlerbit gesetzt";
CM_ SG_ 924 FAL_SM_USpg "Abschaltung Schrittmotor Unterspannung";
CM_ SG_ 924 FAL_RSM_USpg "Das Readyness-Bit dient als Indikator dafür, das der Fehlerbaum sauber durchlaufen wurde. Erst beim Setzen des Readyness-Bits auf '0' wird das dazugehörige Fehlerbit gesetzt";
CM_ SG_ 924 FAL_SM_UeTemp "Abschaltung Schrittmotor Übertemperatur";
CM_ SG_ 924 FAL_RSM_UeTemp "Das Readyness-Bit dient als Indikator dafür, das der Fehlerbaum sauber durchlaufen wurde. Erst beim Setzen des Readyness-Bits auf '0' wird das dazugehörige Fehlerbit gesetzt";
CM_ SG_ 924 FAL_SM_TempPre "Schittmotoransteuergeschwindigkeit muss reduziert werden wegen erhöhter Schrittmotor Temperatur (dies ist kein Fehler-BIT!)";
CM_ SG_ 924 FAL_RSM_TempPre "Das Readyness-Bit dient als Indikator dafür, das der Fehlerbaum sauber durchlaufen wurde. Erst beim Setzen des Readyness-Bits auf '0' wird das dazugehörige Fehlerbit gesetzt";
CM_ SG_ 924 FAL_EM_UeSpg "KL. 15 Überspannung
(eingeschränkte Funktion, aber AFS-CAN läuft!)
siehe VW 801/01";
CM_ SG_ 924 FAL_REM_UeSpg "Das Readyness-Bit dient als Indikator dafür, das der Fehlerbaum sauber durchlaufen wurde. Erst beim Setzen des Readyness-Bits auf '0' wird das dazugehörige Fehlerbit gesetzt";
CM_ SG_ 924 FAL_EM_USpg "KL. 15 Unterspannung
(eingeschränkte Funktion, aber AFS-CAN läuft!)
siehe VW 801/01";
CM_ SG_ 924 FAL_REM_USpg "Das Readyness-Bit dient als Indikator dafür, das der Fehlerbaum sauber durchlaufen wurde. Erst beim Setzen des Readyness-Bits auf '0' wird das dazugehörige Fehlerbit gesetzt";
CM_ SG_ 924 FAL_EM_defekt "Steuergerät defekt
(keine Reparaturmöglichkeit)!";
CM_ SG_ 924 FAL_REM_defekt "Das Readyness-Bit dient als Indikator dafür, das der Fehlerbaum sauber durchlaufen wurde. Erst beim Setzen des Readyness-Bits auf '0' wird das dazugehörige Fehlerbit gesetzt";
CM_ SG_ 924 FAL_sKL_Lampe "Statusmeldung des Lampenausfalls für das statische Kurvenlicht
(offene Leitung)";
CM_ SG_ 924 FAL_RsKL_Lampe "Das Readyness-Bit dient als Indikator dafür, das der Fehlerbaum sauber durchlaufen wurde. Erst beim Setzen des Readyness-Bits auf '0' wird das dazugehörige Fehlerbit gesetzt";
CM_ SG_ 924 FAL_sKL_KS_Gnd "Statusmeldung für das statische Kurvenlicht
Kurzschluß nach Masse";
CM_ SG_ 924 FAL_RsKL_KS_Gnd "Das Readyness-Bit dient als Indikator dafür, das der Fehlerbaum sauber durchlaufen wurde. Erst beim Setzen des Readyness-Bits auf '0' wird das dazugehörige Fehlerbit gesetzt";
CM_ SG_ 924 FAL_GDL_Modul "Bei einem Fehler kann die Mittenposition des dyn. Kurvenlichtes nicht bestimmt werden!
Rückmeldung dyn. KL
Sensorwerte außerhalb des gültigen Bereichs
(Sensor/ Treiber/ Zuleitung/ Schrittmotoransteuerung prüfen!)";
CM_ SG_ 924 FAL_RGDL_Modul "Das Readyness-Bit dient als Indikator dafür, das der Fehlerbaum sauber durchlaufen wurde. Erst beim Setzen des Readyness-Bits auf '0' wird das dazugehörige Fehlerbit gesetzt";
CM_ SG_ 924 FAL_dKL_KS_Plus "Offene Leitung
Kurzschluß nach Plus
Scheinwerferspezifisch wird nur bei verbauter 360° Rückmeldung gesendet!";
CM_ SG_ 924 FAL_RdKL_KS_Plus "Das Readyness-Bit dient als Indikator dafür, das der Fehlerbaum sauber durchlaufen wurde. Erst beim Setzen des Readyness-Bits auf '0' wird das dazugehörige Fehlerbit gesetzt";
CM_ SG_ 924 FAL_dKL_KS_Gnd "Kurzschluß nach Masse
Scheinwerferspezifisch wird nur bei verbauter 360° Rückmeldung gesendet!";
CM_ SG_ 924 FAL_RdKL_KS_Gnd "Das Readyness-Bit dient als Indikator dafür, das der Fehlerbaum sauber durchlaufen wurde. Erst beim Setzen des Readyness-Bits auf '0' wird das dazugehörige Fehlerbit gesetzt";
CM_ SG_ 924 FAL_dKL_unplSign "Unplausibles Signal
Scheinwerferspezifisch wird nur bei verbauter 360° Rückmeldung gesendet!";
CM_ SG_ 924 FAL_RdKL_unplSign "Das Readyness-Bit dient als Indikator dafür, das der Fehlerbaum sauber durchlaufen wurde. Erst beim Setzen des Readyness-Bits auf '0' wird das dazugehörige Fehlerbit gesetzt";
CM_ SG_ 924 FAL_5VdKL_KS_Gnd "Kurzschluß nach Masse der Sensorüberwachung
Scheinwerferspezifisch wird nur bei verbauter 360° Rückmeldung gesendet!";
CM_ SG_ 924 FAL_R5VdKL_KS_Gnd "Das Readyness-Bit dient als Indikator dafür, das der Fehlerbaum sauber durchlaufen wurde. Erst beim Setzen des Readyness-Bits auf '0' wird das dazugehörige Fehlerbit gesetzt";
CM_ SG_ 924 FAL_5VdKL_KS_UB "Kurzschluß nach UB der Sensorüberwachung
Scheinwerferspezifisch wird nur bei verbauter 360° Rückmeldung gesendet!";
CM_ SG_ 924 FAL_R5VdKL_KS_UB "Das Readyness-Bit dient als Indikator dafür, das der Fehlerbaum sauber durchlaufen wurde. Erst beim Setzen des Readyness-Bits auf '0' wird das dazugehörige Fehlerbit gesetzt";
CM_ SG_ 926 FAR_SchMot "Kurzschluss nach Plus
Offene Leitung
Kurzschluß gegeneinander";
CM_ SG_ 926 FAR_RSchMot "Das Readyness-Bit dient als Indikator dafür, das der Fehlerbaum sauber durchlaufen wurde. Erst beim Setzen des Readyness-Bits auf '0' wird das dazugehörige Fehlerbit gesetzt";
CM_ SG_ 926 FAR_SM_KS_Gnd "Kurzschluss nach Masse";
CM_ SG_ 926 FAR_RSM_KS_Gnd "Das Readyness-Bit dient als Indikator dafür, das der Fehlerbaum sauber durchlaufen wurde. Erst beim Setzen des Readyness-Bits auf '0' wird das dazugehörige Fehlerbit gesetzt";
CM_ SG_ 926 FAR_SM_UeSpg "Abschaltung Schrittmotor Überspannung";
CM_ SG_ 926 FAR_RSM_UeSpg "Das Readyness-Bit dient als Indikator dafür, das der Fehlerbaum sauber durchlaufen wurde. Erst beim Setzen des Readyness-Bits auf '0' wird das dazugehörige Fehlerbit gesetzt";
CM_ SG_ 926 FAR_SM_USpg "Abschaltung Schrittmotor Unterspannung";
CM_ SG_ 926 FAR_RSM_USpg "Das Readyness-Bit dient als Indikator dafür, das der Fehlerbaum sauber durchlaufen wurde. Erst beim Setzen des Readyness-Bits auf '0' wird das dazugehörige Fehlerbit gesetzt";
CM_ SG_ 926 FAR_SM_UeTemp "Abschaltung Schrittmotor Übertemperatur";
CM_ SG_ 926 FAR_RSM_UeTemp "Das Readyness-Bit dient als Indikator dafür, das der Fehlerbaum sauber durchlaufen wurde. Erst beim Setzen des Readyness-Bits auf '0' wird das dazugehörige Fehlerbit gesetzt";
CM_ SG_ 926 FAR_SM_TempPre "Schittmotoransteuergeschwindigkeit muss reduziert werden wegen erhöhter Schrittmotor Temperatur (dies ist kein Fehler-BIT!)";
CM_ SG_ 926 FAR_RSM_TempPre "Das Readyness-Bit dient als Indikator dafür, das der Fehlerbaum sauber durchlaufen wurde. Erst beim Setzen des Readyness-Bits auf '0' wird das dazugehörige Fehlerbit gesetzt";
CM_ SG_ 926 FAR_EM_UeSpg "KL. 15 Überspannung
(eingeschränkte Funktion, aber AFS-CAN läuft!)
siehe VW 801/01";
CM_ SG_ 926 FAR_REM_UeSpg "Das Readyness-Bit dient als Indikator dafür, das der Fehlerbaum sauber durchlaufen wurde. Erst beim Setzen des Readyness-Bits auf '0' wird das dazugehörige Fehlerbit gesetzt";
CM_ SG_ 926 FAR_EM_USpg "KL. 15 Unterspannung
(eingeschränkte Funktion, aber AFS-CAN läuft!)
siehe VW 801/01";
CM_ SG_ 926 FAR_REM_USpg "Das Readyness-Bit dient als Indikator dafür, das der Fehlerbaum sauber durchlaufen wurde. Erst beim Setzen des Readyness-Bits auf '0' wird das dazugehörige Fehlerbit gesetzt";
CM_ SG_ 926 FAR_EM_defekt "Steuergerät defekt
(keine Reparaturmöglichkeit)!";
CM_ SG_ 926 FAR_REM_defekt "Das Readyness-Bit dient als Indikator dafür, das der Fehlerbaum sauber durchlaufen wurde. Erst beim Setzen des Readyness-Bits auf '0' wird das dazugehörige Fehlerbit gesetzt";
CM_ SG_ 926 FAR_sKL_Lampe "Statusmeldung des Lampenausfalls für das statische Kurvenlicht
(offene Leitung)";
CM_ SG_ 926 FAR_RsKL_Lampe "Das Readyness-Bit dient als Indikator dafür, das der Fehlerbaum sauber durchlaufen wurde. Erst beim Setzen des Readyness-Bits auf '0' wird das dazugehörige Fehlerbit gesetzt";
CM_ SG_ 926 FAR_sKL_KS_Gnd "Statusmeldung für das statische Kurvenlicht
Kurzschluß nach Masse";
CM_ SG_ 926 FAR_RsKL_KS_Gnd "Das Readyness-Bit dient als Indikator dafür, das der Fehlerbaum sauber durchlaufen wurde. Erst beim Setzen des Readyness-Bits auf '0' wird das dazugehörige Fehlerbit gesetzt";
CM_ SG_ 926 FAR_GDL_Modul "Bei einem Fehler kann die Mittenposition des dyn. Kurvenlichtes nicht bestimmt werden!
Rückmeldung dyn. KL
Sensorwerte außerhalb des gültigen Bereichs
(Sensor/ Treiber/ Zuleitung/ Schrittmotoransteuerung prüfen!)";
CM_ SG_ 926 FAR_RGDL_Modul "Das Readyness-Bit dient als Indikator dafür, das der Fehlerbaum sauber durchlaufen wurde. Erst beim Setzen des Readyness-Bits auf '0' wird das dazugehörige Fehlerbit gesetzt";
CM_ SG_ 926 FAR_dKL_KS_Plus "Offene Leitung
Kurzschluß nach Plus
Scheinwerferspezifisch wird nur bei verbauter 360° Rückmeldung gesendet!";
CM_ SG_ 926 FAR_RdKL_KS_Plus "Das Readyness-Bit dient als Indikator dafür, das der Fehlerbaum sauber durchlaufen wurde. Erst beim Setzen des Readyness-Bits auf '0' wird das dazugehörige Fehlerbit gesetzt";
CM_ SG_ 926 FAR_dKL_KS_Gnd "Kurzschluß nach Masse
Scheinwerferspezifisch wird nur bei verbauter 360° Rückmeldung gesendet!";
CM_ SG_ 926 FAR_RdKL_KS_Gnd "Das Readyness-Bit dient als Indikator dafür, das der Fehlerbaum sauber durchlaufen wurde. Erst beim Setzen des Readyness-Bits auf '0' wird das dazugehörige Fehlerbit gesetzt";
CM_ SG_ 926 FAR_dKL_unplSign "Unplausibles Signal
Scheinwerferspezifisch wird nur bei verbauter 360° Rückmeldung gesendet!";
CM_ SG_ 926 FAR_RdKL_unplSign "Das Readyness-Bit dient als Indikator dafür, das der Fehlerbaum sauber durchlaufen wurde. Erst beim Setzen des Readyness-Bits auf '0' wird das dazugehörige Fehlerbit gesetzt";
CM_ SG_ 926 FAR_5VdKL_KS_Gnd "Kurzschluß nach Masse der Sensorüberwachung
Scheinwerferspezifisch wird nur bei verbauter 360° Rückmeldung gesendet!";
CM_ SG_ 926 FAR_R5VdKL_KS_Gnd "Das Readyness-Bit dient als Indikator dafür, das der Fehlerbaum sauber durchlaufen wurde. Erst beim Setzen des Readyness-Bits auf '0' wird das dazugehörige Fehlerbit gesetzt";
CM_ SG_ 926 FAR_5VdKL_KS_UB "Kurzschluß nach UB der Sensorüberwachung
Scheinwerferspezifisch wird nur bei verbauter 360° Rückmeldung gesendet!";
CM_ SG_ 926 FAR_R5VdKL_KS_UB "Das Readyness-Bit dient als Indikator dafür, das der Fehlerbaum sauber durchlaufen wurde. Erst beim Setzen des Readyness-Bits auf '0' wird das dazugehörige Fehlerbit gesetzt";
CM_ SG_ 1172 IAL_Mux "Durch Setzen der Multiplexer-IDENT Bits werden die einzelnen Bytes der Botschaft abgefragt";
CM_ SG_ 1172 IAL_SW_Idt_Z01 "Software Ident Zeichen 1";
CM_ SG_ 1172 IAL_SW_Idt_Z08 "Software Ident Zeichen 8";
CM_ SG_ 1172 IAL_SW_Idx_Z04 "Software Idex Zeichen 4";
CM_ SG_ 1172 IAL_HW_Idt_Z07 "Hardware Ident Zeichen 7";
CM_ SG_ 1172 IAL_HW_Idx_Z03 "Hardware Index Zeichen 3";
CM_ SG_ 1172 IAL_SW_Idt_Z02 "Software Ident Zeichen 2";
CM_ SG_ 1172 IAL_SW_Idt_Z09 "Software Ident Zeichen 9";
CM_ SG_ 1172 IAL_HW_Idt_Z01 "Hardware Ident Zeichen 1";
CM_ SG_ 1172 IAL_HW_Idt_Z08 "Hardware Ident Zeichen 8";
CM_ SG_ 1172 IAL_SW_Idt_Z03 "Software Ident Zeichen 3";
CM_ SG_ 1172 IAL_SW_Idt_Z10 "Software Ident Zeichen 10";
CM_ SG_ 1172 IAL_HW_Idt_Z02 "Hardware Ident Zeichen 2";
CM_ SG_ 1172 IAL_HW_Idt_Z09 "Hardware Ident Zeichen 9";
CM_ SG_ 1172 IAL_SW_Idt_Z04 "Software Ident Zeichen 4";
CM_ SG_ 1172 IAL_SW_Idt_Z11 "Software Ident Zeichen 11";
CM_ SG_ 1172 IAL_HW_Idt_Z03 "Hardware Ident Zeichen 3";
CM_ SG_ 1172 IAL_HW_Idt_Z10 "Hardware Ident Zeichen 10";
CM_ SG_ 1172 IAL_SW_Idt_Z05 "Software Ident Zeichen 5";
CM_ SG_ 1172 IAL_SW_Idx_Z01 "Software Idex Zeichen 1";
CM_ SG_ 1172 IAL_HW_Idt_Z04 "Hardware Ident Zeichen 4";
CM_ SG_ 1172 IAL_HW_Idt_Z11 "Hardware Ident Zeichen 11";
CM_ SG_ 1172 IAL_SW_Idt_Z06 "Software Ident Zeichen 6";
CM_ SG_ 1172 IAL_SW_Idx_Z02 "Software Idex Zeichen 2";
CM_ SG_ 1172 IAL_HW_Idt_Z05 "Hardware Ident Zeichen 5";
CM_ SG_ 1172 IAL_HW_Idx_Z01 "Hardware Index Zeichen 1";
CM_ SG_ 1172 IAL_SW_Idt_Z07 "Software Ident Zeichen 7";
CM_ SG_ 1172 IAL_SW_Idx_Z03 "Software Idex Zeichen 3";
CM_ SG_ 1172 IAL_HW_Idt_Z06 "Hardware Ident Zeichen 6";
CM_ SG_ 1172 IAL_HW_Idx_Z02 "Hardware Index Zeichen 2";
CM_ SG_ 1174 IAR_Mux "Durch Setzen der Multiplexer-IDENT Bits werden die einzelnen Bytes der Botschaft abgefragt";
CM_ SG_ 1174 IAR_SW_Idt_Z01 "Software Ident Zeichen 1";
CM_ SG_ 1174 IAR_SW_Idt_Z08 "Software Ident Zeichen 8";
CM_ SG_ 1174 IAR_SW_Idx_Z04 "Software Idex Zeichen 4";
CM_ SG_ 1174 IAR_HW_Idt_Z07 "Hardware Ident Zeichen 7";
CM_ SG_ 1174 IAR_HW_Idx_Z03 "Hardware Index Zeichen 3";
CM_ SG_ 1174 IAR_SW_Idt_Z02 "Software Ident Zeichen 2";
CM_ SG_ 1174 IAR_SW_Idt_Z09 "Software Ident Zeichen 9";
CM_ SG_ 1174 IAR_HW_Idt_Z01 "Hardware Ident Zeichen 1";
CM_ SG_ 1174 IAR_HW_Idt_Z08 "Hardware Ident Zeichen 8";
CM_ SG_ 1174 IAR_SW_Idt_Z03 "Software Ident Zeichen 3";
CM_ SG_ 1174 IAR_SW_Idt_Z10 "Software Ident Zeichen 10";
CM_ SG_ 1174 IAR_HW_Idt_Z02 "Hardware Ident Zeichen 2";
CM_ SG_ 1174 IAR_HW_Idt_Z09 "Hardware Ident Zeichen 9";
CM_ SG_ 1174 IAR_SW_Idt_Z04 "Software Ident Zeichen 4";
CM_ SG_ 1174 IAR_SW_Idt_Z11 "Software Ident Zeichen 11";
CM_ SG_ 1174 IAR_HW_Idt_Z03 "Hardware Ident Zeichen 3";
CM_ SG_ 1174 IAR_HW_Idt_Z10 "Hardware Ident Zeichen 10";
CM_ SG_ 1174 IAR_SW_Idt_Z05 "Software Ident Zeichen 5";
CM_ SG_ 1174 IAR_SW_Idx_Z01 "Software Idex Zeichen 1";
CM_ SG_ 1174 IAR_HW_Idt_Z04 "Hardware Ident Zeichen 4";
CM_ SG_ 1174 IAR_HW_Idt_Z11 "Hardware Ident Zeichen 11";
CM_ SG_ 1174 IAR_SW_Idt_Z06 "Software Ident Zeichen 6";
CM_ SG_ 1174 IAR_SW_Idx_Z02 "Software Idex Zeichen 2";
CM_ SG_ 1174 IAR_HW_Idt_Z05 "Hardware Ident Zeichen 5";
CM_ SG_ 1174 IAR_HW_Idx_Z01 "Hardware Index Zeichen 1";
CM_ SG_ 1174 IAR_SW_Idt_Z07 "Software Ident Zeichen 7";
CM_ SG_ 1174 IAR_SW_Idx_Z03 "Software Idex Zeichen 3";
CM_ SG_ 1174 IAR_HW_Idt_Z06 "Hardware Ident Zeichen 6";
CM_ SG_ 1174 IAR_HW_Idx_Z02 "Hardware Index Zeichen 2";
CM_ SG_ 1176 KAL_BG_LWR_O "Wertebereich wie Sollposition!
Diese Grenze ist die maximal im Scheinwerfer erlaubte Grenzposition für Funktion, Stellgliedtest und Referenzlauf";
CM_ SG_ 1176 KAL_BG_LWR_U "Wertebereich wie Sollposition!
Diese Grenze ist die maximal im Scheinwerfer erlaubte Grenzposition für Funktion, Stellgliedtest und Referenzlauf";
CM_ SG_ 1176 KAL_BG_dKL_L "Wertebereich wie Sollposition!
Diese Grenze ist die maximal im Scheinwerfer erlaubte Grenzposition für Funktion, Stellgliedtest und Referenzlauf";
CM_ SG_ 1176 KAL_BG_dKL_R "Wertebereich wie Sollposition!
Diese Grenze ist die maximal im Scheinwerfer erlaubte Grenzposition für Funktion, Stellgliedtest und Referenzlauf";
CM_ SG_ 1176 KAL_Scheinw_Var "Byte 7 MSB: Scheinwerferlieferant (entspricht der Teilenummer des jeweiligen AFS-Elektronik-Moduls)
1111: uncodiert ->(Diese Bitreihenfolge ist für die Slaves zum Senden verboten!)
0001: Lieferant A
0010: Lieferant B
usw.

Byte 7 LSB: Fahrzeugspezif";
CM_ SG_ 1176 KAL_BG_gLW_O "Diese Grenze ist die maximal im Scheinwerfer erlaubte Grenzposition für Funktion.

'Blockgrenze nicht bedient' wird gesetzt, wenn der Aktuator den Wertebereich nicht bedienen kann.";
CM_ SG_ 1184 AFS_L_Scheinw_Var_1 "AFS_L_Scheinw_Var_1 und AFS_L_Scheinw_Var_2 bilden zusammen eine laufende Nummer zur Spezifierung der scheinwerfervarianten- abhängigen Codierung.

Die Scheinwerfervariante beinhaltet die firmenspezifische Funktionalität im Master!
Der Codierforgang wi";
CM_ SG_ 1184 AFS_L_Scheinw_Var_2 "AFS_L_Scheinw_Var_1 und AFS_L_Scheinw_Var_2 bilden zusammen eine laufende Nummer zur Spezifierung der scheinwerfervarianten- abhängigen Codierung.

Die Scheinwerfervariante beinhaltet die firmenspezifische Funktionalität im Master!
Der Codierforgang wi";
CM_ SG_ 1178 KAR_BG_LWR_O "Wertebereich wie Sollposition!
Diese Grenze ist die maximal im Scheinwerfer erlaubte Grenzposition für Funktion, Stellgliedtest und Referenzlauf";
CM_ SG_ 1178 KAR_BG_LWR_U "Wertebereich wie Sollposition!
Diese Grenze ist die maximal im Scheinwerfer erlaubte Grenzposition für Funktion, Stellgliedtest und Referenzlauf";
CM_ SG_ 1178 KAR_BG_dKL_L "Wertebereich wie Sollposition!
Diese Grenze ist die maximal im Scheinwerfer erlaubte Grenzposition für Funktion, Stellgliedtest und Referenzlauf";
CM_ SG_ 1178 KAR_BG_dKL_R "Wertebereich wie Sollposition!
Diese Grenze ist die maximal im Scheinwerfer erlaubte Grenzposition für Funktion, Stellgliedtest und Referenzlauf";
CM_ SG_ 1178 KAR_Scheinw_Var "Byte 7 MSB: Scheinwerferlieferant (entspricht der Teilenummer des jeweiligen AFS-Elektronik-Moduls)
1111: uncodiert ->(Diese Bitreihenfolge ist für die Slaves zum Senden verboten!)
0001: Lieferant A
0010: Lieferant B
usw.

Byte 7 LSB: Fahrzeugspezif";
CM_ SG_ 1178 KAR_BG_gLW_O "Diese Grenze ist die maximal im Scheinwerfer erlaubte Grenzposition für Funktion.

'Blockgrenze nicht bedient' wird gesetzt, wenn der Aktuator den Wertebereich nicht bedienen kann.";
CM_ SG_ 1185 AFS_R_Scheinw_Var_1 "AFS_R_Scheinw_Var_1 und AFS_R_Scheinw_Var_2 bilden zusammen eine laufende Nummer zur Spezifierung der scheinwerfervarianten- abhängigen Codierung.

Die Scheinwerfervariante beinhaltet die firmenspezifische Funktionalität im Master!
Der Codierforgang wi";
CM_ SG_ 1185 AFS_R_Scheinw_Var_2 "AFS_R_Scheinw_Var_1 und AFS_R_Scheinw_Var_2 bilden zusammen eine laufende Nummer zur Spezifierung der scheinwerfervarianten- abhängigen Codierung.

Die Scheinwerfervariante beinhaltet die firmenspezifische Funktionalität im Master!
Der Codierforgang wi";
CM_ SG_ 402 SOA_SollPos_L "Sollwert (Schwenkwinkel) des Schrittmotors des dynamischen Kurvenlichtes im linken Scheinwerfer
(Offset zur Nulllage im linken Scheinwerfer)
Nulllage ist gleich dem Initwert und Fehlerfallposition!
Positives Vorzeichen entspricht Linksschwenken (mathem";
CM_ SG_ 402 SOA_FehlPos_L "dynamisches Kurvenlicht Fehlerfallposition des linken Scheinwerfers";
CM_ SG_ 402 SOA_RefLauf_L "Referenzlauf des linken Schrittmotors
[erfolgt defaultmäßig beim Motorstart]
(Exakte Position siehe: 'Sollposition Kurvenlicht Schrittmotor Position')";
CM_ SG_ 402 SOA_StGlTest_L "(Exakte Position siehe: 'Sollposition Kurvenlicht Schrittmotor Position')";
CM_ SG_ 402 SOA_StGlDim_L "Wert siehe 'Dimmung Abbiegelicht links'";
CM_ SG_ 402 SOA_DimAbLicht_L "0 - 100 % bezogen auf die Versorgungsspannung des linken Moduls";
CM_ SG_ 402 SOA_SollPos_R "Sollwert (Schwenkwinkel) des Schrittmotors des dynamischen Kurvenlichtes im rechten Scheinwerfer
(Offset zur Nulllage im linken Scheinwerfer)
Nulllage ist gleich dem Initwert und Fehlerfallposition!
Positives Vorzeichen entspricht Linksschwenken (mathe";
CM_ SG_ 402 SOA_FehlPos_R "dynamisches Kurvenlicht Fehlerfallposition des rechten Scheinwerfers";
CM_ SG_ 402 SOA_RefLauf_R "Referenzlauf des rechten Schrittmotors
[erfolgt defaultmäßig beim Motorstart]
(Exakte Position siehe: 'Sollposition Kurvenlicht Schrittmotor Position')";
CM_ SG_ 402 SOA_StGlTest_R "(Exakte Position siehe: 'Sollposition Kurvenlicht Schrittmotor Position')";
CM_ SG_ 402 SOA_StGlDim_R "Wert siehe 'Dimmung Abbiegelicht rechts'";
CM_ SG_ 402 SOA_DimAbLicht_R "0 - 100 % bezogen auf die Versorgungsspannung des rechten Moduls";
CM_ SG_ 402 SOA_Variante "Dieses Byte erscheint auch im Tester unter der ESG-Ident der Slaves.

Byte 7 MSB: Scheinwerferlieferant (entspricht der Teilenummer des jeweiligen AFS-Leistungsmoduls)

1111: uncodiert ->(Diese Bitreihenfolge ist für die Slaves zum Senden verboten!)
";
CM_ SG_ 402 SOA_Variante_2 "Dieses Byte erscheint auch im Tester unter der ESG-Ident der Slaves.

Für Fahrzeuge ab S3 (SOP KW48/12) in gemeinsamer Verwendung mit SOA_Variante.

SOA_Variante_2 und SOA_Variante bilden zusammen eine laufende Nummer zur Spezifierung der scheinwerfer";
CM_ SG_ 410 SAL_IstPos "Istwert des Schrittmotors des dynamischen Kurvenlichtes im linken Scheinwerfer
(Offset zur Nulllage im linken Scheinwerfer)
Init = konkreter Wert unbekannt!
positives Vorzeichen entspricht Linksschwenken (mathematisch positive Zählrichtung)";
CM_ SG_ 410 SAL_SchwenkRi "Vor dem Referenzlauf (der beim Klemme 15 Start stattfindet) gibt dieses Bit an in welche Richtung 'Refrenziert' werden muss!
*Solange 'Istposition Kurvenlicht links' auf Init oder '0' oder Fehler steht ist auch Schwenkrichtung unbekannt!";
CM_ SG_ 410 SAL_IstPosMot "Position des Aktuators in Prozent des maximalen Stellweges
vor dem Initialisierungslauf (z.Zt. Motorstart) wird der Initwert ausgegeben
0% ist die Position (auf Block) des Schrittmotors
100% maximaler Verstellweg des Schrittmotors (nicht die Grenze des";
CM_ SG_ 410 SAL_StaReflauf "(Nach erfolgtem Referenzlauf wird Zustand '1' eingenommen.)";
CM_ SG_ 410 SAL_StaAbLicht "Wert siehe 'Istwert Dimmung Abbiegelicht links'";
CM_ SG_ 410 SAL_IstDimAbLi "0 - 100 % bezogen auf die Versorgungsspannung des linken Moduls";
CM_ SG_ 410 SAL_VSpg_AFS "Versorgungspannung des linken Moduls";
CM_ SG_ 412 SAR_IstPos "Istwert des Schrittmotors des dynamischen Kurvenlichtes im rechten Scheinwerfer
(Offset zur Nulllage im rechten Scheinwerfer)
Init = konkreter Wert Wert unbekannt!
positives Vorzeichen entspricht Linksschwenken (mathematisch positive Zählrichtung)";
CM_ SG_ 412 SAR_SchwenkRi "Vor dem Referenzlauf (der beim Klemme 15 Start stattfindet) gibt dieses Bit an in welche Richtung 'Refrenziert' werden muss!
*Solange 'Istposition Kurvenlicht rechts' auf Init oder '0' oder Fehler steht ist auch Schwenkrichtung unbekannt!";
CM_ SG_ 412 SAR_IstPosMot "Position des Aktuators in Prozent des maximalen Stellweges;
vor dem Initialisierungslauf (z.Zt. Motorstart) wird der Initwert ausgegeben
0% ist die Position (auf Block) des Schrittmotors
100% maximaler Verstellweg des Schrittmotors (nicht die Grenze de";
CM_ SG_ 412 SAR_StaReflauf "(Nach erfolgtem Referenzlauf wird Zustand '1' eingenommen.)";
CM_ SG_ 412 SAR_StaAbLicht "Wert siehe 'Istwert Dimmung Abbiegelicht rechts'";
CM_ SG_ 412 SAR_IstDimAbRe "0 - 100 % bezogen auf die Versorgungsspannung des rechten Moduls";
CM_ SG_ 412 SAR_VSpg_AFS "Versorgungspannung des rechten Moduls";
CM_ SG_ 64 Airbag_01_CRC "Für MLB:
'Berechnung siehe Lastenheft 'Kommunikationsabsicherung für FlexRay und CAN''

Ab MQB und MLBevo:
'Berechnung siehe Lastenheft 'End-to-End Kommunikationsabsicherung''

Endwerte siehe Begleitdokument 'S-PDU Kennungsfolgen'";
CM_ SG_ 64 AB_RGS_Anst "PreCrash-Ansteuerung reversibler Gurtstraffer (Aktivierung und Kraftniveau)

10xx = deaktiviert";
CM_ SG_ 64 AB_Front_Crash "Bit wird bei Überschreitung der Gurtstraffer-, US- und RdW-Schwelle gesetzt";
CM_ SG_ 64 AB_Heck_Crash "Wird für alle neu anlaufenden Projekte umgesetzt: AB8.4, Audi8/VW8";
CM_ SG_ 64 AB_SF_Crash "Z.Zt. nur in Verbindung mit Crash-Intensität >= 100b (Kraftstoffpumpenabschaltung) verwendet.";
CM_ SG_ 64 AB_SB_Crash "Z.Zt. nur in Verbindung mit Crash-Intensität >= 100b (Kraftstoffpumpenabschaltung) verwendet.
";
CM_ SG_ 64 AB_Rollover_Crash "Wird im B6/B7 Cabrio und New Beetle Cabrio bedient. ";
CM_ SG_ 64 AB_Crash_Int "Crash_Intensität_1 = fahrzeugabhängige Reaktionen im Crash
Crash_Intensität_2 = fahrzeugabhängige Reaktionen im Crash
Crash_Intensität_3 = fahrzeugabhängige Reaktionen im Crash

Die jeweiligen fahrzeugabhängigen Reaktionen im Crash sind in einem separ";
CM_ SG_ 64 AB_Lampe "Sicherheitswarnlampe im Kombi wird vom Airbag-SG angesteuert; Zustand der Lampe wird auf dem CAN-Bus ausgegeben (auch Blinkinformation).";
CM_ SG_ 64 AB_Deaktiviert "Airbag oder Gurtstraffer wurden per Anpassung deaktiviert: Aktualisierung erst nach Selbsttest";
CM_ SG_ 64 AB_VB_deaktiviert "Als Option vorgehalten, Beifahrerairbag wurden per Schlüsselschalter oder Insassenerkennung deaktiviert";
CM_ SG_ 64 AB_Systemfehler "Systemfehler Ggf. wird Warnlampe dauernd eingeschaltet.";
CM_ SG_ 64 AB_Diagnose "Airbag in Diagnose";
CM_ SG_ 64 AB_Stellgliedtest "Information, ob Airbag im Stellgliedtest ist, um eine Notrufauflösung beim Stellgliedtest zu verhindern";
CM_ SG_ 64 AB_Erh_Auf_VB "Der Fahrer soll bei einem Statuswechsel des Beifahrerairbags (ausgelöst durch die Beifahrerinsassenerkennung oder den Schlüsselschloßschalter) aufmerksam gemacht werden durch eine Anzeige im Kombi. Nur Audi: gültig für: AB2 (4-Türer AU352), B7, C6, D3";
CM_ SG_ 64 AB_Gurtwarn_VF "Fahrer hat Gurt nicht gesteckt, Anzeige im Kombi";
CM_ SG_ 64 AB_Gurtwarn_VB "Beifahrer hat Gurt nicht gesteckt, Anzeige im Kombi";
CM_ SG_ 64 AB_Anzeige_Fussg "Anzeige für ausgelöste Fussgängerschutz-Aktuatorik";
CM_ SG_ 64 AB_Texte_AKS "Textanzeige für pyrotechnische Auslösung der aktiven Kopfstütze (AKS)";
CM_ SG_ 64 AB_MKB_gueltig "Multi-Kollisions-Bremsung im Airbag freigeschaltet";
CM_ SG_ 64 AB_MKB_Anforderung "Anforderung Multi-Kollisions-Bremsung";
CM_ SG_ 64 AB_Versorgungsspannung "Übertragung der Plausibilitätsinformation Kl.15-Last vs. Kl.15-CAN.
Bedienung im Fall Kl.15-Last 'EIN' und Kl.15-CAN 'AUS' mit Ausgabe Warnung/Akustik im Kombi.";
CM_ SG_ 64 AB_Deaktivierung_HV "Deaktivierung des HV-Systems und der HV-Teilnehmer im Crash (u.a. Hybrid- und Elektrofahrzeuge)";
CM_ SG_ 64 AB_EDR_Trigger "Triggerbedingung zur dezentralen Aufzeichnung unfallrelevanter Daten im Event Data Recorder";
CM_ SG_ 64 SC_Masterzeit_Offset "Erweiterung des Signals SC_Masterzeit um zwei höherwertige Bits, so dass ein Zeitbereich von ~20s (statt 5s) abgedeckt werden kann. Der aus SC_Masterzeit_Offset und SC_Masterzeit zu bildende Zeitstempel wird für die Synchronisation von Ereignissen der Fun";
CM_ SG_ 64 SC_LowSpeedCrashErkannt "Crash erkannt bei niedriger Geschwindigkeit";
CM_ SG_ 64 SC_Masterzeit "Masterzeit für alle Objektlisten";
CM_ SG_ 2463978618 BCM1_Laser_Freigabe "Freigabe der Laser-Funktion";
CM_ SG_ 2463978618 AFS_Gelaendelicht_Anf "Anforderung des Gelaendelichts";
CM_ SG_ 2463978618 AFS_PAHS_L_Status "PAHS Rückmeldung zum Status der Verstellung";
CM_ SG_ 2463978618 AFS_PAHS_R_Status "PAHS Rückmeldung zum Status der Verstellung";
CM_ SG_ 2463978618 BCM1_Gleitende_Leuchtw_Anf "Funktion 'Gleitende Leuchtweite' im AFS-SG  freischalten";
CM_ SG_ 2463978618 BCM1_GLW_Fernlicht_Anf "Harte Fernlichtanforderung von BCM1 an die Funktion 'gleitende Leuchtweite' im AFS-SG";
CM_ BO_ 821 "Botschaft zwischen Bildverarbeitungsystem und BCM zur Regulierung der Leuchtweiten";
CM_ SG_ 821 SOA_Offset_L "Solloffset in [°] für den Schwenkwinkel des Abblendlichtbündels (vorzeichenbehaftet)
Bsp.: 2° bedeuten, der Sollschwenkwinkel wird um 2° vergrößert.
";
CM_ SG_ 821 SOA_Offset_R "Solloffset in [°] für den Schwenkwinkel des Abblendlichtbündels (vorzeichenbehaftet)
Bsp.: 2° bedeuten, der Sollschwenkwinkel wird um 2° vergrößert.
";
CM_ SG_ 821 SOL_Offset_L "Solloffset in [mm] des linken Abblendlichtbündels in 10 m Entfernung bezogen auf die Grundeinstellung des Abblendlichtes (-1,0% Neigung am leeren Fahrzeug)
z.B. 0 mm heißt -1,0% Neigung des Abblendlichtbündels (Änderung des Wertebereichs)
negatives Vorz";
CM_ SG_ 821 SOL_Offset_R "Solloffset in [mm] des rechten Abblendlichtbündels in 10 m Entfernung bezogen auf die Grundeinstellung des Abblendlichtes (-1,0% Neigung am leeren Fahrzeug)
z.B. 0 mm heißt -1,0% Neigung des Abblendlichtbündels (Änderung des Wertebereichs)
negatives Vor";
CM_ BO_ 2549880340 "Diagnosezugriff & Flashen Leistungsmodul gleitende Leuchtweite";
CM_ SG_ 2549880340 DIA_gLW_LM_L_Req_Data "Diagnosezugriff & Flashen Leistungsmodule für gleitende Leuchtweite ";
CM_ SG_ 2550011412 DIA_gLW_LM_L_Resp_Data "Diagnosezugriff & Flashen Leistungsmodule für gleitende Leuchtweite ";
CM_ BO_ 2549880341 "Diagnosezugriff Leistungsmodul gleitende Leuchtweite";
CM_ SG_ 2549880341 DIA_gLW_LM_R_Req_Data "Diagnosezugriff & Flashen Leistungsmodule für gleitende Leuchtweite ";
CM_ SG_ 2550011413 DIA_gLW_LM_R_Resp_Data "Diagnosezugriff & Flashen Leistungsmodule für gleitende Leuchtweite ";
CM_ BO_ 2549880330 "Diagnosezugriff Leistungsmodul LED";
CM_ SG_ 2549880330 DIA_LED_LM_L_Req_Data "Diagnosezugriff & Flashen LED Leistungsmodule";
CM_ SG_ 2550011402 DIA_LED_LM_L_Resp_Data "Diagnosezugriff & Flashen LED Leistungsmodule";
CM_ BO_ 2549880331 "Diagnosezugriff Leistungsmodul LED";
CM_ SG_ 2549880331 DIA_LED_LM_R_Req_Data "Diagnosezugriff & Flashen LED Leistungsmodule";
CM_ SG_ 2550011403 DIA_LED_LM_R_Resp_Data "Diagnosezugriff & Flashen LED Leistungsmodule";
CM_ BO_ 2549880427 "Diagnosezugriff Leistungsmodul Matrix Beam";
CM_ SG_ 2549880427 DIA_MXB_LM_L_Req_Data "Diagnosezugriff & Flashen Matrixbeam Leistungsmodule";
CM_ SG_ 2550011499 DIA_MXB_LM_L_Resp_Data "Diagnosezugriff & Flashen Matrixbeam Leistungsmodule";
CM_ BO_ 2549880428 "Diagnosezugriff Leistungsmodul Matrix Beam";
CM_ SG_ 2549880428 DIA_MXB_LM_R_Req_Data "Diagnosezugriff & Flashen Matrixbeam Leistungsmodule";
CM_ SG_ 2550011500 DIA_MXB_LM_R_Resp_Data "Diagnosezugriff & Flashen Matrixbeam Leistungsmodule";
CM_ SG_ 1714 DGN_Verlernzaehler "wrap around 254 --> 0";
CM_ SG_ 1714 KBI_Kilometerstand "Fehler wird ausgegeben, falls Kilometerstand nicht restaurierbar
";
CM_ SG_ 1714 UH_Monat "0x0D, 0xF =  Werte ungültig
0x0E = reserviert (nur VW)";
CM_ SG_ 1714 UH_Tag "0x0: reserviert bei VW";
CM_ SG_ 1714 UH_Stunde "0x18 - 0x1F = Werte ungültig";
CM_ SG_ 1714 UH_Minute "0x3C- 0x3f = Werte ungültig";
CM_ SG_ 1714 UH_Sekunde "0x3C- 0x3f = Werte ungültig";
CM_ BO_ 253 "Neue Momente im MQB
Struktur ab MQB mit CRC8 entstanden aus ESP_01";
CM_ SG_ 253 ESP_21_CRC "Für MLB:
'Berechnung siehe Lastenheft 'Kommunikationsabsicherung für FlexRay und CAN''

Ab MQB und MLBevo:
'Berechnung siehe Lastenheft 'End-to-End Kommunikationsabsicherung''

Endwerte siehe Begleitdokument 'S-PDU Kennungsfolgen'";
CM_ SG_ 253 BR_Eingriffsmoment "Einheitenloser Wert! Faktor in MO_Faktor_Momente_02 in Motor_Code_01 beachten!
Schnelle reduzierende (ASR) oder erhöhende (MSR) Momentanforderung an den Motor.";
CM_ SG_ 253 ESP_PLA_Bremseingriff "Signalisierung des aktiven Bremseingriffes des ESP aufgrund einer Bremsanforderung vom PLA.";
CM_ SG_ 253 ESP_Diagnose "MLB: Nach Diagnoseende wird ein SW-Reset ausgelöst welcher einen Kommunikatiosausfall für max. 150ms verursacht. Dies ist bei SG mit verschärfter Timeoutüberwachung (nicht nach Konzern-LH) zu beachten.

MQB: Weiterführende Informationen im Lastenheft sp";
CM_ SG_ 253 ESC_v_Signal_Qualifier_High_Low "Das Qualifizerungssignal ESC_v_Signal_Qualifier_High_Low gibt eine Information über die Güte der vom Bremsregelsystem ausgegebenen Geschwindigkeitsinformation 'mittlere Geschwindigkeit', wobei Vertrauensbereiche für das ausgegebene Geschwindigkeitssignal ";
CM_ SG_ 253 ESP_Vorsteuerung "zur Unterscheidung zwischen ESP-Vorsteuermaßnahmen und ESP-Regeleingriffen";
CM_ SG_ 253 OBD_Schlechtweg "Für Ausblendung der Zündaussetzererkennung im Motorsteuergerät (Otto). Bit wird gesetzt, wenn Rad-Drehbeschleunigung im ESP > Grenzwert ist. Vorteil gegenüber Radgeschwindigkeiten, dass ESP alle 2 ms dynamisch die Rad-Drehbeschleunigung errechnet und dem ";
CM_ SG_ 253 ESP_v_Signal "Geschwindigkeitssignal vom ABS/ASR oder ESP. Mittelwert der angetriebenen Räder.
Bei MSR oder ABS Eingriffen wird die ABS-Referenzgeschwindigkeit für >= 200ms eingespiegelt (Zeit wird mit Aktiv-Flanke der Funktionsbits getriggert)

MQB: Bei Frontantrie";
CM_ SG_ 253 ASR_Tastung_passiv "ASR deaktiviert oder Schwellen geändert (projektabhängig)
Weiterführende Informationen im Lastenheft spezifiziert und in der entsprechenden Fachabteilung zu erfragen.
";
CM_ SG_ 253 ESP_Tastung_passiv "ESP deaktiviert oder Schwellen geändert (projektabhängig)
Weiterführende Informationen im Lastenheft spezifiziert und in der entsprechenden Fachabteilung zu erfragen.";
CM_ SG_ 253 ESP_Systemstatus "Fehler steht für Stillegung ESP mit Fehlereintrag.

MLB: Flag wird bei Unterspannung im Stand bis einmalig 6km/h (AU48x) oder 10 km/h (AU641, AU57x) überschritten nicht gesetzt (Ausblendung Startvorgang)
Im AU64x, AU57x gilt ESP D4 Funktionsanforderung";
CM_ SG_ 253 ASR_Schalteingriff "Wunsch an das Getriebe während einer ASR Regelung

MLB: Es wird nur 0x0 und 0x1 genutzt

";
CM_ SG_ 253 ESP_Haltebestaetigung "Rückmeldung vom ESP-SG, dass das Fahrzeug aufgrund einer externen Bremsanforderung (z. B. ACC, PLA, ANB, o. ä.) abgebremst wurde und im Stillstand gehalten wird.";
CM_ SG_ 253 ESP_MKB_Abbruch_Geschw "Im Falle einer Multikollisionsbremsung teilt das ESP den Abbruch der MKB aufgrund der unteren Geschwindigkeitsschwelle mit.";
CM_ SG_ 253 ESP_QBit_v_Signal "Geschwindigkeit wird vom ABS/ASR oder ESP aus Ersatzwerten errechnet, wenn Bit gesetzt ist. Güte des Signals ist verändert.";
CM_ SG_ 253 ABS_Bremsung "Antiblockiersystem, Bit zeigt auch Druckabbau an (z.B. ESP hat zuviel Druck aufgebaut oder ungebremste Regelung auf Bahnübergang)
Weiterführende Informationen im Lastenheft spezifiziert und in der entsprechenden Fachabteilung zu erfragen.";
CM_ SG_ 253 ASR_Anf "MLB: Die Momentenanforderung 'ASR_MSR_Moment_schnell' und 'ASR_Moment_langsam' sind auszuführen
MQB: Die Momentenanforderung 'BR_Eingriffsmoment' ist auszuführen";
CM_ SG_ 253 MSR_Anf "MLB: Die Momentenanforderung 'ASR_MSR_Moment_schnell' ist auszuführen.
MQB: Die Momentenanforderung 'BR_Eingriffsmoment' ist auszuführen";
CM_ SG_ 253 EBV_Eingriff "Elektronische Bremskraftverteilung, aktueller Eingriff (Druckhalten, Druckabbau)

Im MLB: kein ABS / ESP-Eingriff ???";
CM_ SG_ 253 EDS_Eingriff "Elektronische Differentialsperre";
CM_ SG_ 253 ESP_Eingriff "Eingriff des Fahrdynamikreglers";
CM_ SG_ 253 ESP_ASP "MLB: Anhaenger-Stabilisierungs-Programm
MQB: Gespannstabilisierung";
CM_ SG_ 918 FGL_Akt_KS_Plus "Kurzschluss nach Plus gLW-Aktuator linker Scheinwerfer";
CM_ SG_ 918 FGL_RAkt_KS_Plus "Das Readyness-Bit dient als Indikator dafür, das der Fehlerbaum sauber durchlaufen wurde. Erst beim Setzen des Readyness-Bits auf '0' wird das dazugehörige Fehlerbit gesetzt";
CM_ SG_ 918 FGL_Akt_KS_Gnd "Kurzschluss nach Masse gLW-Aktuator linker Scheinwerfer";
CM_ SG_ 918 FGL_RAkt_KS_Gnd "Das Readyness-Bit dient als Indikator dafür, das der Fehlerbaum sauber durchlaufen wurde. Erst beim Setzen des Readyness-Bits auf '0' wird das dazugehörige Fehlerbit gesetzt";
CM_ SG_ 918 FGL_Akt_OL "Offene Leitung (Unterbrechung) gLW-Aktuator linker Scheinwerfer";
CM_ SG_ 918 FGL_RAkt_OL "Das Readyness-Bit dient als Indikator dafür, das der Fehlerbaum sauber durchlaufen wurde. Erst beim Setzen des Readyness-Bits auf '0' wird das dazugehörige Fehlerbit gesetzt";
CM_ SG_ 918 FGL_Akt_UeSpg "Abschaltung gLW-Aktuator linker Scheinwerfer aufgrund Überspannung";
CM_ SG_ 918 FGL_RAkt_UeSpg "Das Readyness-Bit dient als Indikator dafür, das der Fehlerbaum sauber durchlaufen wurde. Erst beim Setzen des Readyness-Bits auf '0' wird das dazugehörige Fehlerbit gesetzt";
CM_ SG_ 918 FGL_Akt_USpg "Abschaltung gLW-Aktuator linker Scheinwerfer aufgrund Unterspannung";
CM_ SG_ 918 FGL_RAkt_USpg "Das Readyness-Bit dient als Indikator dafür, das der Fehlerbaum sauber durchlaufen wurde. Erst beim Setzen des Readyness-Bits auf '0' wird das dazugehörige Fehlerbit gesetzt";
CM_ SG_ 918 FGL_Akt_UeTemp "Abschaltung gLW-Aktuator linker Scheinwerfer aufgrund Übertemperatur";
CM_ SG_ 918 FGL_RAkt_UeTemp "Das Readyness-Bit dient als Indikator dafür, das der Fehlerbaum sauber durchlaufen wurde. Erst beim Setzen des Readyness-Bits auf '0' wird das dazugehörige Fehlerbit gesetzt";
CM_ SG_ 918 FGL_Akt_TempPre "Ansteuergeschwindigkeit muss reduziert werden wegen erhöhter gLW-Aktuator Temperatur  
(dies ist kein Fehler-BIT!)";
CM_ SG_ 918 FGL_RAkt_TempPre "Das Readyness-Bit dient als Indikator dafür, das der Fehlerbaum sauber durchlaufen wurde. Erst beim Setzen des Readyness-Bits auf '0' wird das dazugehörige Fehlerbit gesetzt";
CM_ SG_ 918 FGL_HS_KS_Plus "Kurzschluss nach Plus gLW Sensor linker Scheinwerfer

Scheinwerferspezifisch wird nur bei verbauter 360° Rückmeldung gesendet!";
CM_ SG_ 918 FGL_RHS_KS_Plus "Das Readyness-Bit dient als Indikator dafür, das der Fehlerbaum sauber durchlaufen wurde. Erst beim Setzen des Readyness-Bits auf '0' wird das dazugehörige Fehlerbit gesetzt";
CM_ SG_ 918 FGL_HS_KS_Gnd "Kurzschluss nach Masse gLW Sensor linker Scheinwerfer";
CM_ SG_ 918 FGL_RHS_KS_Gnd "Das Readyness-Bit dient als Indikator dafür, das der Fehlerbaum sauber durchlaufen wurde. Erst beim Setzen des Readyness-Bits auf '0' wird das dazugehörige Fehlerbit gesetzt";
CM_ SG_ 918 FGL_HS_unplSign "Bei einem Fehler kann die 0%-Position des 
GLW-Aktuators nicht bestimmt werden!
Rückmeldung GLW Sensorwerte außerhalb des gültigen Bereichs
(Sensor/ Treiber/ Zuleitung/ Schrittmotoransteuerung prüfen!)";
CM_ SG_ 918 FGL_RHS_unplSign "Das Readyness-Bit dient als Indikator dafür, das der Fehlerbaum sauber durchlaufen wurde. Erst beim Setzen des Readyness-Bits auf '0' wird das dazugehörige Fehlerbit gesetzt";
CM_ SG_ 918 FGL_LIN_Def "Physikalischer Defekt der LIN-Leitung";
CM_ SG_ 918 FGL_LIN_Timeout "Keine Kommunikation zum Teilnehmer";
CM_ SG_ 918 FGL_RLIN_Def "Das Readyness-Bit dient als Indikator dafür, das der Fehlerbaum sauber durchlaufen wurde. Erst beim Setzen des Readyness-Bits auf '0' wird das dazugehörige Fehlerbit gesetzt";
CM_ SG_ 918 FGL_RLIN_Timeout "Das Readyness-Bit dient als Indikator dafür, das der Fehlerbaum sauber durchlaufen wurde. Erst beim Setzen des Readyness-Bits auf '0' wird das dazugehörige Fehlerbit gesetzt";
BA_DEF_  "DBName" STRING ;
BA_DEF_  "GenNWMApBusSleep" STRING ;
BA_DEF_  "GenNWMApCanNormal" STRING ;
BA_DEF_  "GenNWMApCanOff" STRING ;
BA_DEF_  "GenNWMApCanOn" STRING ;
BA_DEF_  "GenNWMApCanSleep" STRING ;
BA_DEF_  "GenNWMApCanWakeUp" STRING ;
BA_DEF_  "GenNWMGotoMode_Awake" STRING ;
BA_DEF_  "GenNWMGotoMode_BusSleep" STRING ;
BA_DEF_  "GenNWMSleepTime" INT 0 1000000;
BA_DEF_  "GenNWMTalkNM" STRING ;
BA_DEF_  "Manufacturer" STRING ;
BA_DEF_  "NmType" STRING ;
BA_DEF_  "VAGTP20_SetupMessageCount" INT 0 255;
BA_DEF_  "VAGTP20_SetupStartAddress" HEX 0 2047;
BA_DEF_  "VersionDay" INT 1 31;
BA_DEF_  "VersionMonth" INT 1 12;
BA_DEF_  "VersionWeek" INT 1 52;
BA_DEF_  "VersionYear" INT 0 99;
BA_DEF_  "VersionNumber" INT 0 65535;
BA_DEF_  "Baudrate" INT 0 1000000;
BA_DEF_  "SamplePointMin" INT 1 100;
BA_DEF_  "SamplePointMax" INT 1 100;
BA_DEF_  "SyncJumpWidthMin" INT 1 4;
BA_DEF_  "SyncJumpWidthMax" INT 1 4;
BA_DEF_ BU_  "GenNodAutoGenDsp" ENUM  "No","Yes";
BA_DEF_ BU_  "GenNodAutoGenSnd" ENUM  "No","Yes";
BA_DEF_ BU_  "GenNodSleepTime" INT 0 1000000;
BA_DEF_ BU_  "ILUsed" ENUM  "No","Yes";
BA_DEF_ BU_  "ECUVariantDefault" ENUM  "No","Yes";
BA_DEF_ BU_  "ECUVariantGroup" STRING ;
BA_DEF_ BU_  "NodeLayerModules" STRING ;
BA_DEF_ BU_  "NmhNode" ENUM  "No","Yes";
BA_DEF_ BU_  "NmNode" ENUM  "No","Yes";
BA_DEF_ BO_  "DiagRequest" ENUM  "No","Yes";
BA_DEF_ BO_  "DiagResponse" ENUM  "No","Yes";
BA_DEF_ BO_  "DiagState" ENUM  "No","Yes";
BA_DEF_ BO_  "GenMsgChkConstant" HEX 0 4095;
BA_DEF_ BO_  "GenMsgCycleTime" INT 0 65535;
BA_DEF_ BO_  "GenMsgCycleTimeFast" INT 0 65535;
BA_DEF_ BO_  "GenMsgDelayTime" INT 0 100000;
BA_DEF_ BO_  "GenMsgILSupport" ENUM  "No","Yes";
BA_DEF_ BO_  "GenMsgNrOfRepetition" INT 0 100;
BA_DEF_ BO_  "GenMsgPDUConstants" STRING ;
BA_DEF_ BO_  "GenMsgSendType" ENUM  "Cyclic","not_used","not_used","not_used","not_used","not_used","not_used","IfActive","NoMsgSendType";
BA_DEF_ BO_  "GenMsgStartDelayTime" INT 0 100000;
BA_DEF_ BO_  "NmMessage" ENUM  "No","Yes";
BA_DEF_ BO_  "NmhMessage" ENUM  "No","Yes";
BA_DEF_ BO_  "MsgType" ENUM  "Application","NM ","NMH","TP2.0","ISO-TP ","BAP","EID","KS";
BA_DEF_ BO_  "VAGTP20_API" HEX 0 255;
BA_DEF_ BO_  "VAGTP20_DynConnection" ENUM  "No","Yes";
BA_DEF_ BO_  "VAGTP20_DynSetup" ENUM  "No","Yes";
BA_DEF_ BO_  "VAGTP20_StatConnection" ENUM  "No","Yes";
BA_DEF_ SG_  "GenSigActiveRepetitions" INT -2147483648 2147483647;
BA_DEF_ SG_  "GenSigSendType" ENUM  "Cyclic","OnWrite","OnWriteWithRepetition","OnChange","OnChangeWithRepetition","IfActive","IfActiveWithRepetition","NoSigSendType","OnChangeAndIfActive","OnChangeAndIfActiveWithRepetition";
BA_DEF_ SG_  "GenSigStartValue" INT -2147483648 2147483647;
BA_DEF_ SG_  "NWM-WakeupAllowed" ENUM  "No","Yes";
BA_DEF_ SG_  "GenSigFuncType" ENUM  "NoFunction","MsgCounter","CRC-8","XOR","XOR-2","DatedBit","SW-Kl15","CHK","Constant","Protocol","CRC-8-SAE_J1850";
BA_DEF_ SG_  "GenSigSwitchedByIgnition" ENUM  "No","Yes";
BA_DEF_ SG_  "Fehlerwert" HEX 0 2147483647;
BA_DEF_ SG_  "GenSigMissingSourceValue" HEX 0 2147483647;
BA_DEF_REL_ BU_SG_REL_  "GenSigTimeoutTime" INT 0 65535;
BA_DEF_DEF_  "DBName" "";
BA_DEF_DEF_  "GenNWMApBusSleep" "";
BA_DEF_DEF_  "GenNWMApCanNormal" "";
BA_DEF_DEF_  "GenNWMApCanOff" "";
BA_DEF_DEF_  "GenNWMApCanOn" "";
BA_DEF_DEF_  "GenNWMApCanSleep" "";
BA_DEF_DEF_  "GenNWMApCanWakeUp" "";
BA_DEF_DEF_  "GenNWMGotoMode_Awake" "";
BA_DEF_DEF_  "GenNWMGotoMode_BusSleep" "";
BA_DEF_DEF_  "GenNWMSleepTime" 0;
BA_DEF_DEF_  "GenNWMTalkNM" "";
BA_DEF_DEF_  "Manufacturer" "";
BA_DEF_DEF_  "NmType" "None";
BA_DEF_DEF_  "VAGTP20_SetupMessageCount" 0;
BA_DEF_DEF_  "VAGTP20_SetupStartAddress" 0;
BA_DEF_DEF_  "VersionDay" 28;
BA_DEF_DEF_  "VersionMonth" 5;
BA_DEF_DEF_  "VersionWeek" 22;
BA_DEF_DEF_  "VersionYear" 15;
BA_DEF_DEF_  "VersionNumber" 0;
BA_DEF_DEF_  "Baudrate" 0;
BA_DEF_DEF_  "SamplePointMin" 1;
BA_DEF_DEF_  "SamplePointMax" 1;
BA_DEF_DEF_  "SyncJumpWidthMin" 1;
BA_DEF_DEF_  "SyncJumpWidthMax" 1;
BA_DEF_DEF_  "GenNodAutoGenDsp" "Yes";
BA_DEF_DEF_  "GenNodAutoGenSnd" "Yes";
BA_DEF_DEF_  "GenNodSleepTime" 0;
BA_DEF_DEF_  "ILUsed" "Yes";
BA_DEF_DEF_  "ECUVariantDefault" "Yes";
BA_DEF_DEF_  "ECUVariantGroup" "";
BA_DEF_DEF_  "NodeLayerModules" "";
BA_DEF_DEF_  "NmhNode" "Yes";
BA_DEF_DEF_  "NmNode" "No";
BA_DEF_DEF_  "DiagRequest" "No";
BA_DEF_DEF_  "DiagResponse" "No";
BA_DEF_DEF_  "DiagState" "No";
BA_DEF_DEF_  "GenMsgChkConstant" 0;
BA_DEF_DEF_  "GenMsgCycleTime" 0;
BA_DEF_DEF_  "GenMsgCycleTimeFast" 0;
BA_DEF_DEF_  "GenMsgDelayTime" 0;
BA_DEF_DEF_  "GenMsgILSupport" "No";
BA_DEF_DEF_  "GenMsgNrOfRepetition" 0;
BA_DEF_DEF_  "GenMsgPDUConstants" "";
BA_DEF_DEF_  "GenMsgSendType" "NoMsgSendType";
BA_DEF_DEF_  "GenMsgStartDelayTime" 0;
BA_DEF_DEF_  "NmMessage" "No";
BA_DEF_DEF_  "NmhMessage" "No";
BA_DEF_DEF_  "MsgType" "Application";
BA_DEF_DEF_  "VAGTP20_API" 0;
BA_DEF_DEF_  "VAGTP20_DynConnection" "No";
BA_DEF_DEF_  "VAGTP20_DynSetup" "No";
BA_DEF_DEF_  "VAGTP20_StatConnection" "No";
BA_DEF_DEF_  "GenSigActiveRepetitions" 0;
BA_DEF_DEF_  "GenSigSendType" "NoSigSendType";
BA_DEF_DEF_  "GenSigStartValue" 0;
BA_DEF_DEF_  "NWM-WakeupAllowed" "No";
BA_DEF_DEF_  "GenSigFuncType" "NoFunction";
BA_DEF_DEF_  "GenSigSwitchedByIgnition" "Yes";
BA_DEF_DEF_  "Fehlerwert" 0;
BA_DEF_DEF_  "GenSigMissingSourceValue" 0;
BA_DEF_DEF_REL_ "GenSigTimeoutTime" 0;
BA_ "GenNWMSleepTime" 4000;
BA_ "Manufacturer" "VAG";
BA_ "VAGTP20_SetupMessageCount" 128;
BA_ "VAGTP20_SetupStartAddress" 512;
BA_ "VersionNumber" 11;
BA_ "Baudrate" 500000;
BA_ "SamplePointMin" 80;
BA_ "SamplePointMax" 84;
BA_ "SyncJumpWidthMin" 2;
BA_ "SyncJumpWidthMax" 4;
BA_ "DBName" "AFSCAN";
BA_ "GenNodSleepTime" BU_ AFS 4000;
BA_ "NmhNode" BU_ AFS 0;
BA_ "GenNodSleepTime" BU_ AFS_LMod_L 4000;
BA_ "NmhNode" BU_ AFS_LMod_L 0;
BA_ "GenNodSleepTime" BU_ AFS_LMod_R 4000;
BA_ "NmhNode" BU_ AFS_LMod_R 0;
BA_ "GenNodSleepTime" BU_ BCM1 4000;
BA_ "NmhNode" BU_ BCM1 0;
BA_ "GenNodSleepTime" BU_ BVS 4000;
BA_ "NmhNode" BU_ BVS 0;
BA_ "GenNodSleepTime" BU_ FCM 4000;
BA_ "NmhNode" BU_ FCM 0;
BA_ "GenNodSleepTime" BU_ GLW_LMod_L 4000;
BA_ "NmhNode" BU_ GLW_LMod_L 0;
BA_ "GenNodSleepTime" BU_ GLW_LMod_R 4000;
BA_ "NmhNode" BU_ GLW_LMod_R 0;
BA_ "GenNodSleepTime" BU_ LCM_L 4000;
BA_ "NmhNode" BU_ LCM_L 0;
BA_ "GenNodSleepTime" BU_ LCM_R 4000;
BA_ "NmhNode" BU_ LCM_R 0;
BA_ "GenNodSleepTime" BU_ LED_DK3_LM_L 4000;
BA_ "NmhNode" BU_ LED_DK3_LM_L 0;
BA_ "GenNodSleepTime" BU_ LED_DK3_LM_R 4000;
BA_ "NmhNode" BU_ LED_DK3_LM_R 0;
BA_ "GenNodSleepTime" BU_ LED_LM_L 4000;
BA_ "NmhNode" BU_ LED_LM_L 0;
BA_ "GenNodSleepTime" BU_ LED_LM_R 4000;
BA_ "NmhNode" BU_ LED_LM_R 0;
BA_ "GenNodSleepTime" BU_ LLP_L 4000;
BA_ "NmhNode" BU_ LLP_L 0;
BA_ "GenNodSleepTime" BU_ LLP_R 4000;
BA_ "NmhNode" BU_ LLP_R 0;
BA_ "GenNodSleepTime" BU_ LWR_MXB_L 4000;
BA_ "NmhNode" BU_ LWR_MXB_L 0;
BA_ "GenNodSleepTime" BU_ LWR_MXB_R 4000;
BA_ "NmhNode" BU_ LWR_MXB_R 0;
BA_ "GenNodSleepTime" BU_ MXB 4000;
BA_ "ECUVariantGroup" BU_ MXB "LWRAFS";
BA_ "NmhNode" BU_ MXB 0;
BA_ "GenNodSleepTime" BU_ MXB_LM_L 4000;
BA_ "NmhNode" BU_ MXB_LM_L 0;
BA_ "GenNodSleepTime" BU_ MXB_LM_R 4000;
BA_ "NmhNode" BU_ MXB_LM_R 0;
BA_ "GenNodSleepTime" BU_ ZFAS 4000;
BA_ "NmhNode" BU_ ZFAS 0;
BA_ "GenMsgCycleTime" BO_ 924 100;
BA_ "GenMsgILSupport" BO_ 924 1;
BA_ "GenMsgSendType" BO_ 924 0;
BA_ "GenMsgCycleTime" BO_ 926 100;
BA_ "GenMsgILSupport" BO_ 926 1;
BA_ "GenMsgSendType" BO_ 926 0;
BA_ "GenMsgCycleTime" BO_ 1172 100;
BA_ "GenMsgILSupport" BO_ 1172 1;
BA_ "GenMsgSendType" BO_ 1172 0;
BA_ "GenMsgCycleTime" BO_ 1174 100;
BA_ "GenMsgILSupport" BO_ 1174 1;
BA_ "GenMsgSendType" BO_ 1174 0;
BA_ "GenMsgCycleTime" BO_ 1176 100;
BA_ "GenMsgILSupport" BO_ 1176 1;
BA_ "GenMsgSendType" BO_ 1176 0;
BA_ "GenMsgCycleTime" BO_ 1184 100;
BA_ "GenMsgILSupport" BO_ 1184 1;
BA_ "GenMsgSendType" BO_ 1184 0;
BA_ "GenMsgCycleTime" BO_ 1178 100;
BA_ "GenMsgILSupport" BO_ 1178 1;
BA_ "GenMsgSendType" BO_ 1178 0;
BA_ "GenMsgCycleTime" BO_ 1185 100;
BA_ "GenMsgILSupport" BO_ 1185 1;
BA_ "GenMsgSendType" BO_ 1185 0;
BA_ "GenMsgCycleTime" BO_ 402 10;
BA_ "GenMsgILSupport" BO_ 402 1;
BA_ "GenMsgSendType" BO_ 402 0;
BA_ "GenMsgCycleTime" BO_ 410 10;
BA_ "GenMsgILSupport" BO_ 410 1;
BA_ "GenMsgSendType" BO_ 410 0;
BA_ "GenMsgCycleTime" BO_ 412 10;
BA_ "GenMsgILSupport" BO_ 412 1;
BA_ "GenMsgSendType" BO_ 412 0;
BA_ "GenMsgChkConstant" BO_ 64 64;
BA_ "GenMsgCycleTime" BO_ 64 40;
BA_ "GenMsgCycleTimeFast" BO_ 64 10;
BA_ "GenMsgDelayTime" BO_ 64 10;
BA_ "GenMsgILSupport" BO_ 64 1;
BA_ "GenMsgNrOfRepetition" BO_ 64 5;
BA_ "GenMsgPDUConstants" BO_ 64 "0x40,0x40,0x40,0x40,0x40,0x40,0x40,0x40,0x40,0x40,0x40,0x40,0x40,0x40,0x40,0x40";
BA_ "GenMsgSendType" BO_ 64 0;
BA_ "GenMsgCycleTime" BO_ 2463978618 200;
BA_ "GenMsgDelayTime" BO_ 2463978618 20;
BA_ "GenMsgILSupport" BO_ 2463978618 1;
BA_ "GenMsgSendType" BO_ 2463978618 0;
BA_ "GenMsgCycleTime" BO_ 821 40;
BA_ "GenMsgILSupport" BO_ 821 1;
BA_ "GenMsgSendType" BO_ 821 0;
BA_ "GenMsgStartDelayTime" BO_ 821 15;
BA_ "MsgType" BO_ 2616988416 6;
BA_ "MsgType" BO_ 2616988671 6;
BA_ "MsgType" BO_ 2616990464 6;
BA_ "MsgType" BO_ 2616990719 6;
BA_ "MsgType" BO_ 2617029376 6;
BA_ "MsgType" BO_ 2617029631 6;
BA_ "MsgType" BO_ 2617031424 6;
BA_ "MsgType" BO_ 2617031679 6;
BA_ "MsgType" BO_ 2549880340 4;
BA_ "MsgType" BO_ 2550011412 4;
BA_ "MsgType" BO_ 2549880341 4;
BA_ "MsgType" BO_ 2550011413 4;
BA_ "MsgType" BO_ 2549880330 4;
BA_ "MsgType" BO_ 2550011402 4;
BA_ "MsgType" BO_ 2549880331 4;
BA_ "MsgType" BO_ 2550011403 4;
BA_ "MsgType" BO_ 2549880427 4;
BA_ "MsgType" BO_ 2550011499 4;
BA_ "MsgType" BO_ 2549880428 4;
BA_ "MsgType" BO_ 2550011500 4;
BA_ "GenMsgCycleTime" BO_ 1714 1000;
BA_ "GenMsgILSupport" BO_ 1714 1;
BA_ "GenMsgSendType" BO_ 1714 0;
BA_ "GenMsgCycleTime" BO_ 253 20;
BA_ "GenMsgILSupport" BO_ 253 1;
BA_ "GenMsgSendType" BO_ 253 0;
BA_ "GenMsgCycleTime" BO_ 918 100;
BA_ "GenMsgILSupport" BO_ 918 1;
BA_ "GenMsgSendType" BO_ 918 0;
BA_ "GenSigSendType" SG_ 924 FAL_SchMot 0;
BA_ "Fehlerwert" SG_ 924 FAL_SchMot 1;
BA_ "GenSigSendType" SG_ 924 FAL_RSchMot 0;
BA_ "GenSigStartValue" SG_ 924 FAL_RSchMot 1;
BA_ "GenSigSendType" SG_ 924 FAL_SM_KS_Gnd 0;
BA_ "Fehlerwert" SG_ 924 FAL_SM_KS_Gnd 1;
BA_ "GenSigSendType" SG_ 924 FAL_RSM_KS_Gnd 0;
BA_ "GenSigStartValue" SG_ 924 FAL_RSM_KS_Gnd 1;
BA_ "GenSigSendType" SG_ 924 FAL_SM_UeSpg 0;
BA_ "Fehlerwert" SG_ 924 FAL_SM_UeSpg 1;
BA_ "GenSigSendType" SG_ 924 FAL_RSM_UeSpg 0;
BA_ "GenSigStartValue" SG_ 924 FAL_RSM_UeSpg 1;
BA_ "GenSigSendType" SG_ 924 FAL_SM_USpg 0;
BA_ "Fehlerwert" SG_ 924 FAL_SM_USpg 1;
BA_ "GenSigSendType" SG_ 924 FAL_RSM_USpg 0;
BA_ "GenSigStartValue" SG_ 924 FAL_RSM_USpg 1;
BA_ "GenSigSendType" SG_ 924 FAL_SM_UeTemp 0;
BA_ "Fehlerwert" SG_ 924 FAL_SM_UeTemp 1;
BA_ "GenSigSendType" SG_ 924 FAL_RSM_UeTemp 0;
BA_ "GenSigStartValue" SG_ 924 FAL_RSM_UeTemp 1;
BA_ "GenSigSendType" SG_ 924 FAL_SM_TempPre 0;
BA_ "GenSigSendType" SG_ 924 FAL_RSM_TempPre 0;
BA_ "GenSigStartValue" SG_ 924 FAL_RSM_TempPre 1;
BA_ "GenSigSendType" SG_ 924 FAL_EM_UeSpg 0;
BA_ "Fehlerwert" SG_ 924 FAL_EM_UeSpg 1;
BA_ "GenSigSendType" SG_ 924 FAL_REM_UeSpg 0;
BA_ "GenSigStartValue" SG_ 924 FAL_REM_UeSpg 1;
BA_ "GenSigSendType" SG_ 924 FAL_EM_USpg 0;
BA_ "Fehlerwert" SG_ 924 FAL_EM_USpg 1;
BA_ "GenSigSendType" SG_ 924 FAL_REM_USpg 0;
BA_ "GenSigStartValue" SG_ 924 FAL_REM_USpg 1;
BA_ "GenSigSendType" SG_ 924 FAL_EM_defekt 0;
BA_ "Fehlerwert" SG_ 924 FAL_EM_defekt 1;
BA_ "GenSigSendType" SG_ 924 FAL_REM_defekt 0;
BA_ "GenSigStartValue" SG_ 924 FAL_REM_defekt 1;
BA_ "GenSigSendType" SG_ 924 FAL_sKL_Lampe 0;
BA_ "Fehlerwert" SG_ 924 FAL_sKL_Lampe 1;
BA_ "GenSigSendType" SG_ 924 FAL_RsKL_Lampe 0;
BA_ "GenSigStartValue" SG_ 924 FAL_RsKL_Lampe 1;
BA_ "GenSigSendType" SG_ 924 FAL_sKL_KS_Gnd 0;
BA_ "Fehlerwert" SG_ 924 FAL_sKL_KS_Gnd 1;
BA_ "GenSigSendType" SG_ 924 FAL_RsKL_KS_Gnd 0;
BA_ "GenSigStartValue" SG_ 924 FAL_RsKL_KS_Gnd 1;
BA_ "GenSigSendType" SG_ 924 FAL_GDL_Modul 0;
BA_ "Fehlerwert" SG_ 924 FAL_GDL_Modul 1;
BA_ "GenSigSendType" SG_ 924 FAL_RGDL_Modul 0;
BA_ "GenSigStartValue" SG_ 924 FAL_RGDL_Modul 1;
BA_ "GenSigSendType" SG_ 924 FAL_dKL_KS_Plus 0;
BA_ "Fehlerwert" SG_ 924 FAL_dKL_KS_Plus 1;
BA_ "GenSigSendType" SG_ 924 FAL_RdKL_KS_Plus 0;
BA_ "GenSigStartValue" SG_ 924 FAL_RdKL_KS_Plus 1;
BA_ "GenSigSendType" SG_ 924 FAL_dKL_KS_Gnd 0;
BA_ "Fehlerwert" SG_ 924 FAL_dKL_KS_Gnd 1;
BA_ "GenSigSendType" SG_ 924 FAL_RdKL_KS_Gnd 0;
BA_ "GenSigStartValue" SG_ 924 FAL_RdKL_KS_Gnd 1;
BA_ "GenSigSendType" SG_ 924 FAL_dKL_unplSign 0;
BA_ "Fehlerwert" SG_ 924 FAL_dKL_unplSign 1;
BA_ "GenSigSendType" SG_ 924 FAL_RdKL_unplSign 0;
BA_ "GenSigStartValue" SG_ 924 FAL_RdKL_unplSign 1;
BA_ "GenSigSendType" SG_ 924 FAL_5VdKL_KS_Gnd 0;
BA_ "Fehlerwert" SG_ 924 FAL_5VdKL_KS_Gnd 1;
BA_ "GenSigSendType" SG_ 924 FAL_R5VdKL_KS_Gnd 0;
BA_ "GenSigStartValue" SG_ 924 FAL_R5VdKL_KS_Gnd 1;
BA_ "GenSigSendType" SG_ 924 FAL_5VdKL_KS_UB 0;
BA_ "Fehlerwert" SG_ 924 FAL_5VdKL_KS_UB 1;
BA_ "GenSigSendType" SG_ 924 FAL_R5VdKL_KS_UB 0;
BA_ "GenSigStartValue" SG_ 924 FAL_R5VdKL_KS_UB 1;
BA_ "GenSigSendType" SG_ 926 FAR_SchMot 0;
BA_ "Fehlerwert" SG_ 926 FAR_SchMot 1;
BA_ "GenSigSendType" SG_ 926 FAR_RSchMot 0;
BA_ "GenSigStartValue" SG_ 926 FAR_RSchMot 1;
BA_ "GenSigSendType" SG_ 926 FAR_SM_KS_Gnd 0;
BA_ "Fehlerwert" SG_ 926 FAR_SM_KS_Gnd 1;
BA_ "GenSigSendType" SG_ 926 FAR_RSM_KS_Gnd 0;
BA_ "GenSigStartValue" SG_ 926 FAR_RSM_KS_Gnd 1;
BA_ "GenSigSendType" SG_ 926 FAR_SM_UeSpg 0;
BA_ "Fehlerwert" SG_ 926 FAR_SM_UeSpg 1;
BA_ "GenSigSendType" SG_ 926 FAR_RSM_UeSpg 0;
BA_ "GenSigStartValue" SG_ 926 FAR_RSM_UeSpg 1;
BA_ "GenSigSendType" SG_ 926 FAR_SM_USpg 0;
BA_ "Fehlerwert" SG_ 926 FAR_SM_USpg 1;
BA_ "GenSigSendType" SG_ 926 FAR_RSM_USpg 0;
BA_ "GenSigStartValue" SG_ 926 FAR_RSM_USpg 1;
BA_ "GenSigSendType" SG_ 926 FAR_SM_UeTemp 0;
BA_ "Fehlerwert" SG_ 926 FAR_SM_UeTemp 1;
BA_ "GenSigSendType" SG_ 926 FAR_RSM_UeTemp 0;
BA_ "GenSigStartValue" SG_ 926 FAR_RSM_UeTemp 1;
BA_ "GenSigSendType" SG_ 926 FAR_SM_TempPre 0;
BA_ "GenSigSendType" SG_ 926 FAR_RSM_TempPre 0;
BA_ "GenSigStartValue" SG_ 926 FAR_RSM_TempPre 1;
BA_ "GenSigSendType" SG_ 926 FAR_EM_UeSpg 0;
BA_ "Fehlerwert" SG_ 926 FAR_EM_UeSpg 1;
BA_ "GenSigSendType" SG_ 926 FAR_REM_UeSpg 0;
BA_ "GenSigStartValue" SG_ 926 FAR_REM_UeSpg 1;
BA_ "GenSigSendType" SG_ 926 FAR_EM_USpg 0;
BA_ "Fehlerwert" SG_ 926 FAR_EM_USpg 1;
BA_ "GenSigSendType" SG_ 926 FAR_REM_USpg 0;
BA_ "GenSigStartValue" SG_ 926 FAR_REM_USpg 1;
BA_ "GenSigSendType" SG_ 926 FAR_EM_defekt 0;
BA_ "Fehlerwert" SG_ 926 FAR_EM_defekt 1;
BA_ "GenSigSendType" SG_ 926 FAR_REM_defekt 0;
BA_ "GenSigStartValue" SG_ 926 FAR_REM_defekt 1;
BA_ "GenSigSendType" SG_ 926 FAR_sKL_Lampe 0;
BA_ "Fehlerwert" SG_ 926 FAR_sKL_Lampe 1;
BA_ "GenSigSendType" SG_ 926 FAR_RsKL_Lampe 0;
BA_ "GenSigStartValue" SG_ 926 FAR_RsKL_Lampe 1;
BA_ "GenSigSendType" SG_ 926 FAR_sKL_KS_Gnd 0;
BA_ "Fehlerwert" SG_ 926 FAR_sKL_KS_Gnd 1;
BA_ "GenSigSendType" SG_ 926 FAR_RsKL_KS_Gnd 0;
BA_ "GenSigStartValue" SG_ 926 FAR_RsKL_KS_Gnd 1;
BA_ "GenSigSendType" SG_ 926 FAR_GDL_Modul 0;
BA_ "Fehlerwert" SG_ 926 FAR_GDL_Modul 1;
BA_ "GenSigSendType" SG_ 926 FAR_RGDL_Modul 0;
BA_ "GenSigStartValue" SG_ 926 FAR_RGDL_Modul 1;
BA_ "GenSigSendType" SG_ 926 FAR_dKL_KS_Plus 0;
BA_ "Fehlerwert" SG_ 926 FAR_dKL_KS_Plus 1;
BA_ "GenSigSendType" SG_ 926 FAR_RdKL_KS_Plus 0;
BA_ "GenSigStartValue" SG_ 926 FAR_RdKL_KS_Plus 1;
BA_ "GenSigSendType" SG_ 926 FAR_dKL_KS_Gnd 0;
BA_ "Fehlerwert" SG_ 926 FAR_dKL_KS_Gnd 1;
BA_ "GenSigSendType" SG_ 926 FAR_RdKL_KS_Gnd 0;
BA_ "GenSigStartValue" SG_ 926 FAR_RdKL_KS_Gnd 1;
BA_ "GenSigSendType" SG_ 926 FAR_dKL_unplSign 0;
BA_ "Fehlerwert" SG_ 926 FAR_dKL_unplSign 1;
BA_ "GenSigSendType" SG_ 926 FAR_RdKL_unplSign 0;
BA_ "GenSigStartValue" SG_ 926 FAR_RdKL_unplSign 1;
BA_ "GenSigSendType" SG_ 926 FAR_5VdKL_KS_Gnd 0;
BA_ "Fehlerwert" SG_ 926 FAR_5VdKL_KS_Gnd 1;
BA_ "GenSigSendType" SG_ 926 FAR_R5VdKL_KS_Gnd 0;
BA_ "GenSigStartValue" SG_ 926 FAR_R5VdKL_KS_Gnd 1;
BA_ "GenSigSendType" SG_ 926 FAR_5VdKL_KS_UB 0;
BA_ "Fehlerwert" SG_ 926 FAR_5VdKL_KS_UB 1;
BA_ "GenSigSendType" SG_ 926 FAR_R5VdKL_KS_UB 0;
BA_ "GenSigStartValue" SG_ 926 FAR_R5VdKL_KS_UB 1;
BA_ "GenSigSendType" SG_ 1172 IAL_Mux 0;
BA_ "GenSigSendType" SG_ 1174 IAR_Mux 0;
BA_ "GenSigSendType" SG_ 1176 KAL_BG_LWR_O 0;
BA_ "GenSigStartValue" SG_ 1176 KAL_BG_LWR_O 4094;
BA_ "Fehlerwert" SG_ 1176 KAL_BG_LWR_O 4095;
BA_ "GenSigSendType" SG_ 1176 KAL_BG_LWR_U 0;
BA_ "GenSigStartValue" SG_ 1176 KAL_BG_LWR_U 4094;
BA_ "Fehlerwert" SG_ 1176 KAL_BG_LWR_U 4095;
BA_ "GenSigSendType" SG_ 1176 KAL_BG_dKL_L 0;
BA_ "GenSigStartValue" SG_ 1176 KAL_BG_dKL_L 4094;
BA_ "Fehlerwert" SG_ 1176 KAL_BG_dKL_L 4095;
BA_ "GenSigSendType" SG_ 1176 KAL_BG_dKL_R 0;
BA_ "GenSigStartValue" SG_ 1176 KAL_BG_dKL_R 4094;
BA_ "Fehlerwert" SG_ 1176 KAL_BG_dKL_R 4095;
BA_ "GenSigSendType" SG_ 1176 KAL_Scheinw_Var 0;
BA_ "GenSigSendType" SG_ 1176 KAL_BG_gLW_O 0;
BA_ "GenSigStartValue" SG_ 1176 KAL_BG_gLW_O 254;
BA_ "Fehlerwert" SG_ 1176 KAL_BG_gLW_O 255;
BA_ "GenSigSendType" SG_ 1184 AFS_L_Scheinw_Var_1 0;
BA_ "GenSigSendType" SG_ 1184 AFS_L_Scheinw_Var_2 0;
BA_ "GenSigSendType" SG_ 1178 KAR_BG_LWR_O 0;
BA_ "GenSigStartValue" SG_ 1178 KAR_BG_LWR_O 4094;
BA_ "Fehlerwert" SG_ 1178 KAR_BG_LWR_O 4095;
BA_ "GenSigSendType" SG_ 1178 KAR_BG_LWR_U 0;
BA_ "GenSigStartValue" SG_ 1178 KAR_BG_LWR_U 4094;
BA_ "Fehlerwert" SG_ 1178 KAR_BG_LWR_U 4095;
BA_ "GenSigSendType" SG_ 1178 KAR_BG_dKL_L 0;
BA_ "GenSigStartValue" SG_ 1178 KAR_BG_dKL_L 4094;
BA_ "Fehlerwert" SG_ 1178 KAR_BG_dKL_L 4095;
BA_ "GenSigSendType" SG_ 1178 KAR_BG_dKL_R 0;
BA_ "GenSigStartValue" SG_ 1178 KAR_BG_dKL_R 4094;
BA_ "Fehlerwert" SG_ 1178 KAR_BG_dKL_R 4095;
BA_ "GenSigSendType" SG_ 1178 KAR_Scheinw_Var 0;
BA_ "GenSigSendType" SG_ 1178 KAR_BG_gLW_O 0;
BA_ "GenSigStartValue" SG_ 1178 KAR_BG_gLW_O 254;
BA_ "Fehlerwert" SG_ 1178 KAR_BG_gLW_O 255;
BA_ "GenSigSendType" SG_ 1185 AFS_R_Scheinw_Var_1 0;
BA_ "GenSigSendType" SG_ 1185 AFS_R_Scheinw_Var_2 0;
BA_ "GenSigSendType" SG_ 402 SOA_SollPos_L 0;
BA_ "GenSigStartValue" SG_ 402 SOA_SollPos_L 4094;
BA_ "Fehlerwert" SG_ 402 SOA_SollPos_L 4095;
BA_ "GenSigSendType" SG_ 402 SOA_FehlPos_L 0;
BA_ "GenSigSendType" SG_ 402 SOA_RefLauf_L 0;
BA_ "GenSigSendType" SG_ 402 SOA_StGlTest_L 0;
BA_ "GenSigSendType" SG_ 402 SOA_StGlDim_L 0;
BA_ "GenSigSendType" SG_ 402 SOA_DimAbLicht_L 0;
BA_ "Fehlerwert" SG_ 402 SOA_DimAbLicht_L 255;
BA_ "GenSigSendType" SG_ 402 SOA_SollPos_R 0;
BA_ "GenSigStartValue" SG_ 402 SOA_SollPos_R 4094;
BA_ "Fehlerwert" SG_ 402 SOA_SollPos_R 4095;
BA_ "GenSigSendType" SG_ 402 SOA_FehlPos_R 0;
BA_ "GenSigSendType" SG_ 402 SOA_RefLauf_R 0;
BA_ "GenSigSendType" SG_ 402 SOA_StGlTest_R 0;
BA_ "GenSigSendType" SG_ 402 SOA_StGlDim_R 0;
BA_ "GenSigSendType" SG_ 402 SOA_DimAbLicht_R 0;
BA_ "Fehlerwert" SG_ 402 SOA_DimAbLicht_R 255;
BA_ "GenSigSendType" SG_ 402 SOA_Variante 0;
BA_ "GenSigSendType" SG_ 402 SOA_Variante_2 0;
BA_ "GenSigSendType" SG_ 410 SAL_IstPos 0;
BA_ "GenSigStartValue" SG_ 410 SAL_IstPos 4094;
BA_ "Fehlerwert" SG_ 410 SAL_IstPos 4095;
BA_ "GenSigSendType" SG_ 410 SAL_SchwenkRi 0;
BA_ "GenSigSendType" SG_ 410 SAL_IstPosMot 0;
BA_ "GenSigStartValue" SG_ 410 SAL_IstPosMot 254;
BA_ "Fehlerwert" SG_ 410 SAL_IstPosMot 255;
BA_ "GenSigSendType" SG_ 410 SAL_StaVerst 0;
BA_ "GenSigSendType" SG_ 410 SAL_StaFehPos 0;
BA_ "GenSigSendType" SG_ 410 SAL_StaReflauf 0;
BA_ "GenSigSendType" SG_ 410 SAL_StaStGlTst 0;
BA_ "GenSigSendType" SG_ 410 SAL_StaAbLicht 0;
BA_ "GenSigSendType" SG_ 410 SAL_IstDimAbLi 0;
BA_ "GenSigStartValue" SG_ 410 SAL_IstDimAbLi 254;
BA_ "Fehlerwert" SG_ 410 SAL_IstDimAbLi 255;
BA_ "GenSigSendType" SG_ 410 SAL_VSpg_AFS 0;
BA_ "GenSigStartValue" SG_ 410 SAL_VSpg_AFS 254;
BA_ "Fehlerwert" SG_ 410 SAL_VSpg_AFS 255;
BA_ "GenSigSendType" SG_ 412 SAR_IstPos 0;
BA_ "GenSigStartValue" SG_ 412 SAR_IstPos 4094;
BA_ "Fehlerwert" SG_ 412 SAR_IstPos 4095;
BA_ "GenSigSendType" SG_ 412 SAR_SchwenkRi 0;
BA_ "GenSigSendType" SG_ 412 SAR_IstPosMot 0;
BA_ "GenSigStartValue" SG_ 412 SAR_IstPosMot 254;
BA_ "Fehlerwert" SG_ 412 SAR_IstPosMot 255;
BA_ "GenSigSendType" SG_ 412 SAR_StaVerst 0;
BA_ "GenSigSendType" SG_ 412 SAR_StaFehPos 0;
BA_ "GenSigSendType" SG_ 412 SAR_StaReflauf 0;
BA_ "GenSigSendType" SG_ 412 SAR_StaStGlTst 0;
BA_ "GenSigSendType" SG_ 412 SAR_StaAbLicht 0;
BA_ "GenSigSendType" SG_ 412 SAR_IstDimAbRe 0;
BA_ "GenSigStartValue" SG_ 412 SAR_IstDimAbRe 254;
BA_ "Fehlerwert" SG_ 412 SAR_IstDimAbRe 255;
BA_ "GenSigSendType" SG_ 412 SAR_VSpg_AFS 0;
BA_ "GenSigStartValue" SG_ 412 SAR_VSpg_AFS 254;
BA_ "Fehlerwert" SG_ 412 SAR_VSpg_AFS 255;
BA_ "GenSigSendType" SG_ 64 Airbag_01_CRC 0;
BA_ "GenSigFuncType" SG_ 64 Airbag_01_CRC 2;
BA_ "GenSigSwitchedByIgnition" SG_ 64 Airbag_01_CRC 0;
BA_ "GenSigSendType" SG_ 64 Airbag_01_BZ 0;
BA_ "GenSigFuncType" SG_ 64 Airbag_01_BZ 1;
BA_ "GenSigSwitchedByIgnition" SG_ 64 Airbag_01_BZ 0;
BA_ "GenSigSendType" SG_ 64 AB_RGS_Anst 0;
BA_ "GenSigStartValue" SG_ 64 AB_RGS_Anst 8;
BA_ "GenSigSwitchedByIgnition" SG_ 64 AB_RGS_Anst 0;
BA_ "GenSigActiveRepetitions" SG_ 64 AB_Front_Crash 5;
BA_ "GenSigSendType" SG_ 64 AB_Front_Crash 4;
BA_ "GenSigSwitchedByIgnition" SG_ 64 AB_Front_Crash 0;
BA_ "GenSigActiveRepetitions" SG_ 64 AB_Heck_Crash 5;
BA_ "GenSigSendType" SG_ 64 AB_Heck_Crash 4;
BA_ "GenSigSwitchedByIgnition" SG_ 64 AB_Heck_Crash 0;
BA_ "GenSigActiveRepetitions" SG_ 64 AB_SF_Crash 5;
BA_ "GenSigSendType" SG_ 64 AB_SF_Crash 4;
BA_ "GenSigSwitchedByIgnition" SG_ 64 AB_SF_Crash 0;
BA_ "GenSigActiveRepetitions" SG_ 64 AB_SB_Crash 5;
BA_ "GenSigSendType" SG_ 64 AB_SB_Crash 4;
BA_ "GenSigSwitchedByIgnition" SG_ 64 AB_SB_Crash 0;
BA_ "GenSigActiveRepetitions" SG_ 64 AB_Rollover_Crash 5;
BA_ "GenSigSendType" SG_ 64 AB_Rollover_Crash 4;
BA_ "GenSigSwitchedByIgnition" SG_ 64 AB_Rollover_Crash 0;
BA_ "GenSigActiveRepetitions" SG_ 64 AB_Crash_Int 5;
BA_ "GenSigSendType" SG_ 64 AB_Crash_Int 4;
BA_ "GenSigSwitchedByIgnition" SG_ 64 AB_Crash_Int 0;
BA_ "GenSigSendType" SG_ 64 AB_Lampe 0;
BA_ "GenSigStartValue" SG_ 64 AB_Lampe 1;
BA_ "GenSigSwitchedByIgnition" SG_ 64 AB_Lampe 0;
BA_ "GenSigSendType" SG_ 64 AB_Deaktiviert 0;
BA_ "GenSigSwitchedByIgnition" SG_ 64 AB_Deaktiviert 0;
BA_ "GenSigSendType" SG_ 64 AB_VB_deaktiviert 0;
BA_ "GenSigStartValue" SG_ 64 AB_VB_deaktiviert 1;
BA_ "GenSigSwitchedByIgnition" SG_ 64 AB_VB_deaktiviert 0;
BA_ "GenSigSendType" SG_ 64 AB_Systemfehler 0;
BA_ "GenSigSwitchedByIgnition" SG_ 64 AB_Systemfehler 0;
BA_ "GenSigSendType" SG_ 64 AB_Diagnose 0;
BA_ "GenSigSwitchedByIgnition" SG_ 64 AB_Diagnose 0;
BA_ "GenSigSendType" SG_ 64 AB_Stellgliedtest 0;
BA_ "GenSigSwitchedByIgnition" SG_ 64 AB_Stellgliedtest 0;
BA_ "GenSigSendType" SG_ 64 AB_Erh_Auf_VB 0;
BA_ "GenSigSwitchedByIgnition" SG_ 64 AB_Erh_Auf_VB 0;
BA_ "GenSigSendType" SG_ 64 AB_Gurtwarn_VF 0;
BA_ "GenSigSwitchedByIgnition" SG_ 64 AB_Gurtwarn_VF 0;
BA_ "GenSigSendType" SG_ 64 AB_Gurtwarn_VB 0;
BA_ "GenSigSwitchedByIgnition" SG_ 64 AB_Gurtwarn_VB 0;
BA_ "GenSigSendType" SG_ 64 AB_Anzeige_Fussg 0;
BA_ "GenSigSwitchedByIgnition" SG_ 64 AB_Anzeige_Fussg 0;
BA_ "GenSigSendType" SG_ 64 AB_Texte_AKS 0;
BA_ "GenSigSwitchedByIgnition" SG_ 64 AB_Texte_AKS 0;
BA_ "GenSigSendType" SG_ 64 AB_MKB_gueltig 0;
BA_ "GenSigFuncType" SG_ 64 AB_MKB_gueltig 8;
BA_ "GenSigSwitchedByIgnition" SG_ 64 AB_MKB_gueltig 0;
BA_ "GenSigActiveRepetitions" SG_ 64 AB_MKB_Anforderung 5;
BA_ "GenSigSendType" SG_ 64 AB_MKB_Anforderung 4;
BA_ "GenSigSwitchedByIgnition" SG_ 64 AB_MKB_Anforderung 0;
BA_ "GenSigSendType" SG_ 64 AB_Versorgungsspannung 0;
BA_ "GenSigSwitchedByIgnition" SG_ 64 AB_Versorgungsspannung 0;
BA_ "GenSigActiveRepetitions" SG_ 64 AB_Deaktivierung_HV 5;
BA_ "GenSigSendType" SG_ 64 AB_Deaktivierung_HV 4;
BA_ "GenSigSwitchedByIgnition" SG_ 64 AB_Deaktivierung_HV 0;
BA_ "Fehlerwert" SG_ 64 AB_Deaktivierung_HV 7;
BA_ "GenSigSendType" SG_ 64 AB_EDR_Trigger 3;
BA_ "GenSigSwitchedByIgnition" SG_ 64 AB_EDR_Trigger 0;
BA_ "GenSigSendType" SG_ 64 SC_Masterzeit_Offset 0;
BA_ "GenSigSendType" SG_ 64 SC_LowSpeedCrashErkannt 0;
BA_ "GenSigSwitchedByIgnition" SG_ 64 SC_LowSpeedCrashErkannt 0;
BA_ "GenSigSendType" SG_ 64 SC_Masterzeit 0;
BA_ "GenSigStartValue" SG_ 64 SC_Masterzeit 127;
BA_ "GenSigSendType" SG_ 2463978618 BCM1_Laser_Freigabe 3;
BA_ "GenSigSwitchedByIgnition" SG_ 2463978618 BCM1_Laser_Freigabe 0;
BA_ "GenSigSendType" SG_ 2463978618 AFS_Gelaendelicht_Anf 3;
BA_ "GenSigSwitchedByIgnition" SG_ 2463978618 AFS_Gelaendelicht_Anf 0;
BA_ "GenSigSendType" SG_ 2463978618 AFS_PAHS_L_Status 3;
BA_ "GenSigSwitchedByIgnition" SG_ 2463978618 AFS_PAHS_L_Status 0;
BA_ "GenSigSendType" SG_ 2463978618 AFS_PAHS_R_Status 3;
BA_ "GenSigSwitchedByIgnition" SG_ 2463978618 AFS_PAHS_R_Status 0;
BA_ "GenSigSendType" SG_ 2463978618 BCM1_Gleitende_Leuchtw_Anf 3;
BA_ "GenSigSwitchedByIgnition" SG_ 2463978618 BCM1_Gleitende_Leuchtw_Anf 0;
BA_ "GenSigSendType" SG_ 2463978618 BCM1_GLW_Fernlicht_Anf 3;
BA_ "GenSigSwitchedByIgnition" SG_ 2463978618 BCM1_GLW_Fernlicht_Anf 0;
BA_ "GenSigSendType" SG_ 821 SOA_Offset_L 0;
BA_ "GenSigStartValue" SG_ 821 SOA_Offset_L 4094;
BA_ "Fehlerwert" SG_ 821 SOA_Offset_L 4095;
BA_ "GenSigSendType" SG_ 821 SOA_Offset_R 0;
BA_ "GenSigStartValue" SG_ 821 SOA_Offset_R 4094;
BA_ "Fehlerwert" SG_ 821 SOA_Offset_R 4095;
BA_ "GenSigSendType" SG_ 821 SOL_Offset_L 0;
BA_ "GenSigStartValue" SG_ 821 SOL_Offset_L 4094;
BA_ "Fehlerwert" SG_ 821 SOL_Offset_L 4095;
BA_ "GenSigSendType" SG_ 821 SOL_Offset_R 0;
BA_ "GenSigStartValue" SG_ 821 SOL_Offset_R 4094;
BA_ "Fehlerwert" SG_ 821 SOL_Offset_R 4095;
BA_ "GenSigSendType" SG_ 2549880340 DIA_gLW_LM_L_Req_Data 3;
BA_ "GenSigFuncType" SG_ 2549880340 DIA_gLW_LM_L_Req_Data 9;
BA_ "GenSigSendType" SG_ 2550011412 DIA_gLW_LM_L_Resp_Data 3;
BA_ "GenSigFuncType" SG_ 2550011412 DIA_gLW_LM_L_Resp_Data 9;
BA_ "GenSigSendType" SG_ 2549880341 DIA_gLW_LM_R_Req_Data 3;
BA_ "GenSigFuncType" SG_ 2549880341 DIA_gLW_LM_R_Req_Data 9;
BA_ "GenSigSendType" SG_ 2550011413 DIA_gLW_LM_R_Resp_Data 3;
BA_ "GenSigFuncType" SG_ 2550011413 DIA_gLW_LM_R_Resp_Data 9;
BA_ "GenSigSendType" SG_ 2549880330 DIA_LED_LM_L_Req_Data 3;
BA_ "GenSigFuncType" SG_ 2549880330 DIA_LED_LM_L_Req_Data 9;
BA_ "GenSigSendType" SG_ 2550011402 DIA_LED_LM_L_Resp_Data 3;
BA_ "GenSigFuncType" SG_ 2550011402 DIA_LED_LM_L_Resp_Data 9;
BA_ "GenSigSendType" SG_ 2549880331 DIA_LED_LM_R_Req_Data 3;
BA_ "GenSigFuncType" SG_ 2549880331 DIA_LED_LM_R_Req_Data 9;
BA_ "GenSigSendType" SG_ 2550011403 DIA_LED_LM_R_Resp_Data 3;
BA_ "GenSigFuncType" SG_ 2550011403 DIA_LED_LM_R_Resp_Data 9;
BA_ "GenSigSendType" SG_ 2549880427 DIA_MXB_LM_L_Req_Data 3;
BA_ "GenSigFuncType" SG_ 2549880427 DIA_MXB_LM_L_Req_Data 9;
BA_ "GenSigSendType" SG_ 2550011499 DIA_MXB_LM_L_Resp_Data 3;
BA_ "GenSigFuncType" SG_ 2550011499 DIA_MXB_LM_L_Resp_Data 9;
BA_ "GenSigSendType" SG_ 2549880428 DIA_MXB_LM_R_Req_Data 3;
BA_ "GenSigFuncType" SG_ 2549880428 DIA_MXB_LM_R_Req_Data 9;
BA_ "GenSigSendType" SG_ 2550011500 DIA_MXB_LM_R_Resp_Data 3;
BA_ "GenSigFuncType" SG_ 2550011500 DIA_MXB_LM_R_Resp_Data 9;
BA_ "GenSigSendType" SG_ 1714 DGN_Verlernzaehler 0;
BA_ "GenSigSendType" SG_ 1714 KBI_Kilometerstand 0;
BA_ "GenSigStartValue" SG_ 1714 KBI_Kilometerstand 1048574;
BA_ "Fehlerwert" SG_ 1714 KBI_Kilometerstand 1048575;
BA_ "GenSigSendType" SG_ 1714 UH_Jahr 0;
BA_ "GenSigSendType" SG_ 1714 UH_Monat 0;
BA_ "Fehlerwert" SG_ 1714 UH_Monat 15;
BA_ "GenSigSendType" SG_ 1714 UH_Tag 0;
BA_ "GenSigSendType" SG_ 1714 UH_Stunde 0;
BA_ "GenSigSendType" SG_ 1714 UH_Minute 0;
BA_ "GenSigSendType" SG_ 1714 UH_Sekunde 0;
BA_ "GenSigSendType" SG_ 253 ESP_21_CRC 0;
BA_ "GenSigFuncType" SG_ 253 ESP_21_CRC 2;
BA_ "GenSigSendType" SG_ 253 ESP_21_BZ 0;
BA_ "GenSigFuncType" SG_ 253 ESP_21_BZ 1;
BA_ "GenSigSendType" SG_ 253 BR_Eingriffsmoment 0;
BA_ "GenSigStartValue" SG_ 253 BR_Eingriffsmoment 1022;
BA_ "Fehlerwert" SG_ 253 BR_Eingriffsmoment 1023;
BA_ "GenSigSendType" SG_ 253 ESP_PLA_Bremseingriff 0;
BA_ "GenSigSendType" SG_ 253 ESP_Diagnose 0;
BA_ "GenSigSendType" SG_ 253 ESC_v_Signal_Qualifier_High_Low 0;
BA_ "GenSigStartValue" SG_ 253 ESC_v_Signal_Qualifier_High_Low 6;
BA_ "Fehlerwert" SG_ 253 ESC_v_Signal_Qualifier_High_Low 7;
BA_ "GenSigSendType" SG_ 253 ESP_Vorsteuerung 0;
BA_ "GenSigSendType" SG_ 253 OBD_Schlechtweg 0;
BA_ "GenSigSendType" SG_ 253 OBD_QBit_Schlechtweg 0;
BA_ "GenSigStartValue" SG_ 253 OBD_QBit_Schlechtweg 1;
BA_ "GenSigSendType" SG_ 253 ESP_v_Signal 0;
BA_ "GenSigStartValue" SG_ 253 ESP_v_Signal 65534;
BA_ "Fehlerwert" SG_ 253 ESP_v_Signal 65535;
BA_ "GenSigMissingSourceValue" SG_ 253 ESP_v_Signal 65534;
BA_ "GenSigSendType" SG_ 253 ASR_Tastung_passiv 0;
BA_ "GenSigSendType" SG_ 253 ESP_Tastung_passiv 0;
BA_ "GenSigSendType" SG_ 253 ESP_Systemstatus 0;
BA_ "GenSigSendType" SG_ 253 ASR_Schalteingriff 0;
BA_ "GenSigSendType" SG_ 253 ESP_Haltebestaetigung 0;
BA_ "GenSigSendType" SG_ 253 ESP_MKB_Abbruch_Geschw 0;
BA_ "GenSigSendType" SG_ 253 ESP_QBit_v_Signal 0;
BA_ "GenSigStartValue" SG_ 253 ESP_QBit_v_Signal 1;
BA_ "GenSigSendType" SG_ 253 ABS_Bremsung 0;
BA_ "GenSigSendType" SG_ 253 ASR_Anf 0;
BA_ "GenSigSendType" SG_ 253 MSR_Anf 0;
BA_ "GenSigSendType" SG_ 253 EBV_Eingriff 0;
BA_ "GenSigSendType" SG_ 253 EDS_Eingriff 0;
BA_ "GenSigSendType" SG_ 253 ESP_Eingriff 0;
BA_ "GenSigSendType" SG_ 253 ESP_ASP 0;
BA_ "GenSigSendType" SG_ 918 FGL_Akt_KS_Plus 0;
BA_ "Fehlerwert" SG_ 918 FGL_Akt_KS_Plus 1;
BA_ "GenSigSendType" SG_ 918 FGL_RAkt_KS_Plus 0;
BA_ "GenSigStartValue" SG_ 918 FGL_RAkt_KS_Plus 1;
BA_ "GenSigSendType" SG_ 918 FGL_Akt_KS_Gnd 0;
BA_ "Fehlerwert" SG_ 918 FGL_Akt_KS_Gnd 1;
BA_ "GenSigSendType" SG_ 918 FGL_RAkt_KS_Gnd 0;
BA_ "GenSigStartValue" SG_ 918 FGL_RAkt_KS_Gnd 1;
BA_ "GenSigSendType" SG_ 918 FGL_Akt_OL 0;
BA_ "Fehlerwert" SG_ 918 FGL_Akt_OL 1;
BA_ "GenSigSendType" SG_ 918 FGL_RAkt_OL 0;
BA_ "GenSigStartValue" SG_ 918 FGL_RAkt_OL 1;
BA_ "GenSigSendType" SG_ 918 FGL_Akt_UeSpg 0;
BA_ "Fehlerwert" SG_ 918 FGL_Akt_UeSpg 1;
BA_ "GenSigSendType" SG_ 918 FGL_RAkt_UeSpg 0;
BA_ "GenSigStartValue" SG_ 918 FGL_RAkt_UeSpg 1;
BA_ "GenSigSendType" SG_ 918 FGL_Akt_USpg 0;
BA_ "Fehlerwert" SG_ 918 FGL_Akt_USpg 1;
BA_ "GenSigSendType" SG_ 918 FGL_RAkt_USpg 0;
BA_ "GenSigStartValue" SG_ 918 FGL_RAkt_USpg 1;
BA_ "GenSigSendType" SG_ 918 FGL_Akt_UeTemp 0;
BA_ "Fehlerwert" SG_ 918 FGL_Akt_UeTemp 1;
BA_ "GenSigSendType" SG_ 918 FGL_RAkt_UeTemp 0;
BA_ "GenSigStartValue" SG_ 918 FGL_RAkt_UeTemp 1;
BA_ "GenSigSendType" SG_ 918 FGL_Akt_TempPre 0;
BA_ "GenSigSendType" SG_ 918 FGL_RAkt_TempPre 0;
BA_ "GenSigStartValue" SG_ 918 FGL_RAkt_TempPre 1;
BA_ "GenSigSendType" SG_ 918 FGL_HS_KS_Plus 0;
BA_ "Fehlerwert" SG_ 918 FGL_HS_KS_Plus 1;
BA_ "GenSigSendType" SG_ 918 FGL_RHS_KS_Plus 0;
BA_ "GenSigStartValue" SG_ 918 FGL_RHS_KS_Plus 1;
BA_ "GenSigSendType" SG_ 918 FGL_HS_KS_Gnd 0;
BA_ "Fehlerwert" SG_ 918 FGL_HS_KS_Gnd 1;
BA_ "GenSigSendType" SG_ 918 FGL_RHS_KS_Gnd 0;
BA_ "GenSigStartValue" SG_ 918 FGL_RHS_KS_Gnd 1;
BA_ "GenSigSendType" SG_ 918 FGL_HS_unplSign 0;
BA_ "Fehlerwert" SG_ 918 FGL_HS_unplSign 1;
BA_ "GenSigSendType" SG_ 918 FGL_RHS_unplSign 0;
BA_ "GenSigStartValue" SG_ 918 FGL_RHS_unplSign 1;
BA_ "GenSigSendType" SG_ 918 FGL_LIN_Def 0;
BA_ "Fehlerwert" SG_ 918 FGL_LIN_Def 1;
BA_ "GenSigSendType" SG_ 918 FGL_LIN_Timeout 0;
BA_ "Fehlerwert" SG_ 918 FGL_LIN_Timeout 1;
BA_ "GenSigSendType" SG_ 918 FGL_RLIN_Def 0;
BA_ "GenSigSendType" SG_ 918 FGL_RLIN_Timeout 0;
BA_REL_ "GenSigTimeoutTime" BU_SG_REL_ AFS SG_ 924 FAL_SchMot 1000;
BA_REL_ "GenSigTimeoutTime" BU_SG_REL_ BCM1 SG_ 924 FAL_SchMot 1000;
BA_REL_ "GenSigTimeoutTime" BU_SG_REL_ FCM SG_ 924 FAL_SchMot 1000;
BA_REL_ "GenSigTimeoutTime" BU_SG_REL_ AFS SG_ 924 FAL_RSchMot 1000;
BA_REL_ "GenSigTimeoutTime" BU_SG_REL_ BCM1 SG_ 924 FAL_RSchMot 1000;
BA_REL_ "GenSigTimeoutTime" BU_SG_REL_ FCM SG_ 924 FAL_RSchMot 1000;
BA_REL_ "GenSigTimeoutTime" BU_SG_REL_ AFS SG_ 924 FAL_SM_KS_Gnd 1000;
BA_REL_ "GenSigTimeoutTime" BU_SG_REL_ BCM1 SG_ 924 FAL_SM_KS_Gnd 1000;
BA_REL_ "GenSigTimeoutTime" BU_SG_REL_ FCM SG_ 924 FAL_SM_KS_Gnd 1000;
BA_REL_ "GenSigTimeoutTime" BU_SG_REL_ AFS SG_ 924 FAL_RSM_KS_Gnd 1000;
BA_REL_ "GenSigTimeoutTime" BU_SG_REL_ BCM1 SG_ 924 FAL_RSM_KS_Gnd 1000;
BA_REL_ "GenSigTimeoutTime" BU_SG_REL_ FCM SG_ 924 FAL_RSM_KS_Gnd 1000;
BA_REL_ "GenSigTimeoutTime" BU_SG_REL_ AFS SG_ 924 FAL_SM_UeSpg 1000;
BA_REL_ "GenSigTimeoutTime" BU_SG_REL_ BCM1 SG_ 924 FAL_SM_UeSpg 1000;
BA_REL_ "GenSigTimeoutTime" BU_SG_REL_ FCM SG_ 924 FAL_SM_UeSpg 1000;
BA_REL_ "GenSigTimeoutTime" BU_SG_REL_ AFS SG_ 924 FAL_RSM_UeSpg 1000;
BA_REL_ "GenSigTimeoutTime" BU_SG_REL_ BCM1 SG_ 924 FAL_RSM_UeSpg 1000;
BA_REL_ "GenSigTimeoutTime" BU_SG_REL_ FCM SG_ 924 FAL_RSM_UeSpg 1000;
BA_REL_ "GenSigTimeoutTime" BU_SG_REL_ AFS SG_ 924 FAL_SM_USpg 1000;
BA_REL_ "GenSigTimeoutTime" BU_SG_REL_ BCM1 SG_ 924 FAL_SM_USpg 1000;
BA_REL_ "GenSigTimeoutTime" BU_SG_REL_ FCM SG_ 924 FAL_SM_USpg 1000;
BA_REL_ "GenSigTimeoutTime" BU_SG_REL_ AFS SG_ 924 FAL_RSM_USpg 1000;
BA_REL_ "GenSigTimeoutTime" BU_SG_REL_ BCM1 SG_ 924 FAL_RSM_USpg 1000;
BA_REL_ "GenSigTimeoutTime" BU_SG_REL_ FCM SG_ 924 FAL_RSM_USpg 1000;
BA_REL_ "GenSigTimeoutTime" BU_SG_REL_ AFS SG_ 924 FAL_SM_UeTemp 1000;
BA_REL_ "GenSigTimeoutTime" BU_SG_REL_ BCM1 SG_ 924 FAL_SM_UeTemp 1000;
BA_REL_ "GenSigTimeoutTime" BU_SG_REL_ FCM SG_ 924 FAL_SM_UeTemp 1000;
BA_REL_ "GenSigTimeoutTime" BU_SG_REL_ AFS SG_ 924 FAL_RSM_UeTemp 1000;
BA_REL_ "GenSigTimeoutTime" BU_SG_REL_ BCM1 SG_ 924 FAL_RSM_UeTemp 1000;
BA_REL_ "GenSigTimeoutTime" BU_SG_REL_ FCM SG_ 924 FAL_RSM_UeTemp 1000;
BA_REL_ "GenSigTimeoutTime" BU_SG_REL_ AFS SG_ 924 FAL_SM_TempPre 1000;
BA_REL_ "GenSigTimeoutTime" BU_SG_REL_ BCM1 SG_ 924 FAL_SM_TempPre 1000;
BA_REL_ "GenSigTimeoutTime" BU_SG_REL_ FCM SG_ 924 FAL_SM_TempPre 1000;
BA_REL_ "GenSigTimeoutTime" BU_SG_REL_ AFS SG_ 924 FAL_RSM_TempPre 1000;
BA_REL_ "GenSigTimeoutTime" BU_SG_REL_ BCM1 SG_ 924 FAL_RSM_TempPre 1000;
BA_REL_ "GenSigTimeoutTime" BU_SG_REL_ FCM SG_ 924 FAL_RSM_TempPre 1000;
BA_REL_ "GenSigTimeoutTime" BU_SG_REL_ AFS SG_ 924 FAL_EM_UeSpg 1000;
BA_REL_ "GenSigTimeoutTime" BU_SG_REL_ BCM1 SG_ 924 FAL_EM_UeSpg 1000;
BA_REL_ "GenSigTimeoutTime" BU_SG_REL_ FCM SG_ 924 FAL_EM_UeSpg 1000;
BA_REL_ "GenSigTimeoutTime" BU_SG_REL_ AFS SG_ 924 FAL_REM_UeSpg 1000;
BA_REL_ "GenSigTimeoutTime" BU_SG_REL_ BCM1 SG_ 924 FAL_REM_UeSpg 1000;
BA_REL_ "GenSigTimeoutTime" BU_SG_REL_ FCM SG_ 924 FAL_REM_UeSpg 1000;
BA_REL_ "GenSigTimeoutTime" BU_SG_REL_ AFS SG_ 924 FAL_EM_USpg 1000;
BA_REL_ "GenSigTimeoutTime" BU_SG_REL_ BCM1 SG_ 924 FAL_EM_USpg 1000;
BA_REL_ "GenSigTimeoutTime" BU_SG_REL_ FCM SG_ 924 FAL_EM_USpg 1000;
BA_REL_ "GenSigTimeoutTime" BU_SG_REL_ AFS SG_ 924 FAL_REM_USpg 1000;
BA_REL_ "GenSigTimeoutTime" BU_SG_REL_ BCM1 SG_ 924 FAL_REM_USpg 1000;
BA_REL_ "GenSigTimeoutTime" BU_SG_REL_ FCM SG_ 924 FAL_REM_USpg 1000;
BA_REL_ "GenSigTimeoutTime" BU_SG_REL_ AFS SG_ 924 FAL_EM_defekt 1000;
BA_REL_ "GenSigTimeoutTime" BU_SG_REL_ BCM1 SG_ 924 FAL_EM_defekt 1000;
BA_REL_ "GenSigTimeoutTime" BU_SG_REL_ FCM SG_ 924 FAL_EM_defekt 1000;
BA_REL_ "GenSigTimeoutTime" BU_SG_REL_ AFS SG_ 924 FAL_REM_defekt 1000;
BA_REL_ "GenSigTimeoutTime" BU_SG_REL_ BCM1 SG_ 924 FAL_REM_defekt 1000;
BA_REL_ "GenSigTimeoutTime" BU_SG_REL_ FCM SG_ 924 FAL_REM_defekt 1000;
BA_REL_ "GenSigTimeoutTime" BU_SG_REL_ AFS SG_ 924 FAL_sKL_Lampe 1000;
BA_REL_ "GenSigTimeoutTime" BU_SG_REL_ BCM1 SG_ 924 FAL_sKL_Lampe 1000;
BA_REL_ "GenSigTimeoutTime" BU_SG_REL_ FCM SG_ 924 FAL_sKL_Lampe 1000;
BA_REL_ "GenSigTimeoutTime" BU_SG_REL_ AFS SG_ 924 FAL_RsKL_Lampe 1000;
BA_REL_ "GenSigTimeoutTime" BU_SG_REL_ BCM1 SG_ 924 FAL_RsKL_Lampe 1000;
BA_REL_ "GenSigTimeoutTime" BU_SG_REL_ FCM SG_ 924 FAL_RsKL_Lampe 1000;
BA_REL_ "GenSigTimeoutTime" BU_SG_REL_ AFS SG_ 924 FAL_sKL_KS_Gnd 1000;
BA_REL_ "GenSigTimeoutTime" BU_SG_REL_ BCM1 SG_ 924 FAL_sKL_KS_Gnd 1000;
BA_REL_ "GenSigTimeoutTime" BU_SG_REL_ FCM SG_ 924 FAL_sKL_KS_Gnd 1000;
BA_REL_ "GenSigTimeoutTime" BU_SG_REL_ AFS SG_ 924 FAL_RsKL_KS_Gnd 1000;
BA_REL_ "GenSigTimeoutTime" BU_SG_REL_ BCM1 SG_ 924 FAL_RsKL_KS_Gnd 1000;
BA_REL_ "GenSigTimeoutTime" BU_SG_REL_ FCM SG_ 924 FAL_RsKL_KS_Gnd 1000;
BA_REL_ "GenSigTimeoutTime" BU_SG_REL_ AFS SG_ 924 FAL_GDL_Modul 1000;
BA_REL_ "GenSigTimeoutTime" BU_SG_REL_ BCM1 SG_ 924 FAL_GDL_Modul 1000;
BA_REL_ "GenSigTimeoutTime" BU_SG_REL_ FCM SG_ 924 FAL_GDL_Modul 1000;
BA_REL_ "GenSigTimeoutTime" BU_SG_REL_ AFS SG_ 924 FAL_RGDL_Modul 1000;
BA_REL_ "GenSigTimeoutTime" BU_SG_REL_ BCM1 SG_ 924 FAL_RGDL_Modul 1000;
BA_REL_ "GenSigTimeoutTime" BU_SG_REL_ FCM SG_ 924 FAL_RGDL_Modul 1000;
BA_REL_ "GenSigTimeoutTime" BU_SG_REL_ AFS SG_ 924 FAL_dKL_KS_Plus 1000;
BA_REL_ "GenSigTimeoutTime" BU_SG_REL_ BCM1 SG_ 924 FAL_dKL_KS_Plus 1000;
BA_REL_ "GenSigTimeoutTime" BU_SG_REL_ FCM SG_ 924 FAL_dKL_KS_Plus 1000;
BA_REL_ "GenSigTimeoutTime" BU_SG_REL_ AFS SG_ 924 FAL_RdKL_KS_Plus 1000;
BA_REL_ "GenSigTimeoutTime" BU_SG_REL_ BCM1 SG_ 924 FAL_RdKL_KS_Plus 1000;
BA_REL_ "GenSigTimeoutTime" BU_SG_REL_ FCM SG_ 924 FAL_RdKL_KS_Plus 1000;
BA_REL_ "GenSigTimeoutTime" BU_SG_REL_ AFS SG_ 924 FAL_dKL_KS_Gnd 1000;
BA_REL_ "GenSigTimeoutTime" BU_SG_REL_ BCM1 SG_ 924 FAL_dKL_KS_Gnd 1000;
BA_REL_ "GenSigTimeoutTime" BU_SG_REL_ FCM SG_ 924 FAL_dKL_KS_Gnd 1000;
BA_REL_ "GenSigTimeoutTime" BU_SG_REL_ AFS SG_ 924 FAL_RdKL_KS_Gnd 1000;
BA_REL_ "GenSigTimeoutTime" BU_SG_REL_ BCM1 SG_ 924 FAL_RdKL_KS_Gnd 1000;
BA_REL_ "GenSigTimeoutTime" BU_SG_REL_ FCM SG_ 924 FAL_RdKL_KS_Gnd 1000;
BA_REL_ "GenSigTimeoutTime" BU_SG_REL_ AFS SG_ 924 FAL_dKL_unplSign 1000;
BA_REL_ "GenSigTimeoutTime" BU_SG_REL_ BCM1 SG_ 924 FAL_dKL_unplSign 1000;
BA_REL_ "GenSigTimeoutTime" BU_SG_REL_ FCM SG_ 924 FAL_dKL_unplSign 1000;
BA_REL_ "GenSigTimeoutTime" BU_SG_REL_ AFS SG_ 924 FAL_RdKL_unplSign 1000;
BA_REL_ "GenSigTimeoutTime" BU_SG_REL_ BCM1 SG_ 924 FAL_RdKL_unplSign 1000;
BA_REL_ "GenSigTimeoutTime" BU_SG_REL_ FCM SG_ 924 FAL_RdKL_unplSign 1000;
BA_REL_ "GenSigTimeoutTime" BU_SG_REL_ AFS SG_ 924 FAL_5VdKL_KS_Gnd 1000;
BA_REL_ "GenSigTimeoutTime" BU_SG_REL_ BCM1 SG_ 924 FAL_5VdKL_KS_Gnd 1000;
BA_REL_ "GenSigTimeoutTime" BU_SG_REL_ FCM SG_ 924 FAL_5VdKL_KS_Gnd 1000;
BA_REL_ "GenSigTimeoutTime" BU_SG_REL_ AFS SG_ 924 FAL_R5VdKL_KS_Gnd 1000;
BA_REL_ "GenSigTimeoutTime" BU_SG_REL_ BCM1 SG_ 924 FAL_R5VdKL_KS_Gnd 1000;
BA_REL_ "GenSigTimeoutTime" BU_SG_REL_ FCM SG_ 924 FAL_R5VdKL_KS_Gnd 1000;
BA_REL_ "GenSigTimeoutTime" BU_SG_REL_ AFS SG_ 924 FAL_5VdKL_KS_UB 1000;
BA_REL_ "GenSigTimeoutTime" BU_SG_REL_ BCM1 SG_ 924 FAL_5VdKL_KS_UB 1000;
BA_REL_ "GenSigTimeoutTime" BU_SG_REL_ FCM SG_ 924 FAL_5VdKL_KS_UB 1000;
BA_REL_ "GenSigTimeoutTime" BU_SG_REL_ AFS SG_ 924 FAL_R5VdKL_KS_UB 1000;
BA_REL_ "GenSigTimeoutTime" BU_SG_REL_ BCM1 SG_ 924 FAL_R5VdKL_KS_UB 1000;
BA_REL_ "GenSigTimeoutTime" BU_SG_REL_ FCM SG_ 924 FAL_R5VdKL_KS_UB 1000;
BA_REL_ "GenSigTimeoutTime" BU_SG_REL_ AFS SG_ 926 FAR_SchMot 1000;
BA_REL_ "GenSigTimeoutTime" BU_SG_REL_ BCM1 SG_ 926 FAR_SchMot 1000;
BA_REL_ "GenSigTimeoutTime" BU_SG_REL_ FCM SG_ 926 FAR_SchMot 1000;
BA_REL_ "GenSigTimeoutTime" BU_SG_REL_ AFS SG_ 926 FAR_RSchMot 1000;
BA_REL_ "GenSigTimeoutTime" BU_SG_REL_ BCM1 SG_ 926 FAR_RSchMot 1000;
BA_REL_ "GenSigTimeoutTime" BU_SG_REL_ FCM SG_ 926 FAR_RSchMot 1000;
BA_REL_ "GenSigTimeoutTime" BU_SG_REL_ AFS SG_ 926 FAR_SM_KS_Gnd 1000;
BA_REL_ "GenSigTimeoutTime" BU_SG_REL_ BCM1 SG_ 926 FAR_SM_KS_Gnd 1000;
BA_REL_ "GenSigTimeoutTime" BU_SG_REL_ FCM SG_ 926 FAR_SM_KS_Gnd 1000;
BA_REL_ "GenSigTimeoutTime" BU_SG_REL_ AFS SG_ 926 FAR_RSM_KS_Gnd 1000;
BA_REL_ "GenSigTimeoutTime" BU_SG_REL_ BCM1 SG_ 926 FAR_RSM_KS_Gnd 1000;
BA_REL_ "GenSigTimeoutTime" BU_SG_REL_ FCM SG_ 926 FAR_RSM_KS_Gnd 1000;
BA_REL_ "GenSigTimeoutTime" BU_SG_REL_ AFS SG_ 926 FAR_SM_UeSpg 1000;
BA_REL_ "GenSigTimeoutTime" BU_SG_REL_ BCM1 SG_ 926 FAR_SM_UeSpg 1000;
BA_REL_ "GenSigTimeoutTime" BU_SG_REL_ FCM SG_ 926 FAR_SM_UeSpg 1000;
BA_REL_ "GenSigTimeoutTime" BU_SG_REL_ AFS SG_ 926 FAR_RSM_UeSpg 1000;
BA_REL_ "GenSigTimeoutTime" BU_SG_REL_ BCM1 SG_ 926 FAR_RSM_UeSpg 1000;
BA_REL_ "GenSigTimeoutTime" BU_SG_REL_ FCM SG_ 926 FAR_RSM_UeSpg 1000;
BA_REL_ "GenSigTimeoutTime" BU_SG_REL_ AFS SG_ 926 FAR_SM_USpg 1000;
BA_REL_ "GenSigTimeoutTime" BU_SG_REL_ BCM1 SG_ 926 FAR_SM_USpg 1000;
BA_REL_ "GenSigTimeoutTime" BU_SG_REL_ FCM SG_ 926 FAR_SM_USpg 1000;
BA_REL_ "GenSigTimeoutTime" BU_SG_REL_ AFS SG_ 926 FAR_RSM_USpg 1000;
BA_REL_ "GenSigTimeoutTime" BU_SG_REL_ BCM1 SG_ 926 FAR_RSM_USpg 1000;
BA_REL_ "GenSigTimeoutTime" BU_SG_REL_ FCM SG_ 926 FAR_RSM_USpg 1000;
BA_REL_ "GenSigTimeoutTime" BU_SG_REL_ AFS SG_ 926 FAR_SM_UeTemp 1000;
BA_REL_ "GenSigTimeoutTime" BU_SG_REL_ BCM1 SG_ 926 FAR_SM_UeTemp 1000;
BA_REL_ "GenSigTimeoutTime" BU_SG_REL_ FCM SG_ 926 FAR_SM_UeTemp 1000;
BA_REL_ "GenSigTimeoutTime" BU_SG_REL_ AFS SG_ 926 FAR_RSM_UeTemp 1000;
BA_REL_ "GenSigTimeoutTime" BU_SG_REL_ BCM1 SG_ 926 FAR_RSM_UeTemp 1000;
BA_REL_ "GenSigTimeoutTime" BU_SG_REL_ FCM SG_ 926 FAR_RSM_UeTemp 1000;
BA_REL_ "GenSigTimeoutTime" BU_SG_REL_ AFS SG_ 926 FAR_SM_TempPre 1000;
BA_REL_ "GenSigTimeoutTime" BU_SG_REL_ BCM1 SG_ 926 FAR_SM_TempPre 1000;
BA_REL_ "GenSigTimeoutTime" BU_SG_REL_ FCM SG_ 926 FAR_SM_TempPre 1000;
BA_REL_ "GenSigTimeoutTime" BU_SG_REL_ AFS SG_ 926 FAR_RSM_TempPre 1000;
BA_REL_ "GenSigTimeoutTime" BU_SG_REL_ BCM1 SG_ 926 FAR_RSM_TempPre 1000;
BA_REL_ "GenSigTimeoutTime" BU_SG_REL_ FCM SG_ 926 FAR_RSM_TempPre 1000;
BA_REL_ "GenSigTimeoutTime" BU_SG_REL_ AFS SG_ 926 FAR_EM_UeSpg 1000;
BA_REL_ "GenSigTimeoutTime" BU_SG_REL_ BCM1 SG_ 926 FAR_EM_UeSpg 1000;
BA_REL_ "GenSigTimeoutTime" BU_SG_REL_ FCM SG_ 926 FAR_EM_UeSpg 1000;
BA_REL_ "GenSigTimeoutTime" BU_SG_REL_ AFS SG_ 926 FAR_REM_UeSpg 1000;
BA_REL_ "GenSigTimeoutTime" BU_SG_REL_ BCM1 SG_ 926 FAR_REM_UeSpg 1000;
BA_REL_ "GenSigTimeoutTime" BU_SG_REL_ FCM SG_ 926 FAR_REM_UeSpg 1000;
BA_REL_ "GenSigTimeoutTime" BU_SG_REL_ AFS SG_ 926 FAR_EM_USpg 1000;
BA_REL_ "GenSigTimeoutTime" BU_SG_REL_ BCM1 SG_ 926 FAR_EM_USpg 1000;
BA_REL_ "GenSigTimeoutTime" BU_SG_REL_ FCM SG_ 926 FAR_EM_USpg 1000;
BA_REL_ "GenSigTimeoutTime" BU_SG_REL_ AFS SG_ 926 FAR_REM_USpg 1000;
BA_REL_ "GenSigTimeoutTime" BU_SG_REL_ BCM1 SG_ 926 FAR_REM_USpg 1000;
BA_REL_ "GenSigTimeoutTime" BU_SG_REL_ FCM SG_ 926 FAR_REM_USpg 1000;
BA_REL_ "GenSigTimeoutTime" BU_SG_REL_ AFS SG_ 926 FAR_EM_defekt 1000;
BA_REL_ "GenSigTimeoutTime" BU_SG_REL_ BCM1 SG_ 926 FAR_EM_defekt 1000;
BA_REL_ "GenSigTimeoutTime" BU_SG_REL_ FCM SG_ 926 FAR_EM_defekt 1000;
BA_REL_ "GenSigTimeoutTime" BU_SG_REL_ AFS SG_ 926 FAR_REM_defekt 1000;
BA_REL_ "GenSigTimeoutTime" BU_SG_REL_ BCM1 SG_ 926 FAR_REM_defekt 1000;
BA_REL_ "GenSigTimeoutTime" BU_SG_REL_ FCM SG_ 926 FAR_REM_defekt 1000;
BA_REL_ "GenSigTimeoutTime" BU_SG_REL_ AFS SG_ 926 FAR_sKL_Lampe 1000;
BA_REL_ "GenSigTimeoutTime" BU_SG_REL_ BCM1 SG_ 926 FAR_sKL_Lampe 1000;
BA_REL_ "GenSigTimeoutTime" BU_SG_REL_ FCM SG_ 926 FAR_sKL_Lampe 1000;
BA_REL_ "GenSigTimeoutTime" BU_SG_REL_ AFS SG_ 926 FAR_RsKL_Lampe 1000;
BA_REL_ "GenSigTimeoutTime" BU_SG_REL_ BCM1 SG_ 926 FAR_RsKL_Lampe 1000;
BA_REL_ "GenSigTimeoutTime" BU_SG_REL_ FCM SG_ 926 FAR_RsKL_Lampe 1000;
BA_REL_ "GenSigTimeoutTime" BU_SG_REL_ AFS SG_ 926 FAR_sKL_KS_Gnd 1000;
BA_REL_ "GenSigTimeoutTime" BU_SG_REL_ BCM1 SG_ 926 FAR_sKL_KS_Gnd 1000;
BA_REL_ "GenSigTimeoutTime" BU_SG_REL_ FCM SG_ 926 FAR_sKL_KS_Gnd 1000;
BA_REL_ "GenSigTimeoutTime" BU_SG_REL_ AFS SG_ 926 FAR_RsKL_KS_Gnd 1000;
BA_REL_ "GenSigTimeoutTime" BU_SG_REL_ BCM1 SG_ 926 FAR_RsKL_KS_Gnd 1000;
BA_REL_ "GenSigTimeoutTime" BU_SG_REL_ FCM SG_ 926 FAR_RsKL_KS_Gnd 1000;
BA_REL_ "GenSigTimeoutTime" BU_SG_REL_ AFS SG_ 926 FAR_GDL_Modul 1000;
BA_REL_ "GenSigTimeoutTime" BU_SG_REL_ BCM1 SG_ 926 FAR_GDL_Modul 1000;
BA_REL_ "GenSigTimeoutTime" BU_SG_REL_ FCM SG_ 926 FAR_GDL_Modul 1000;
BA_REL_ "GenSigTimeoutTime" BU_SG_REL_ AFS SG_ 926 FAR_RGDL_Modul 1000;
BA_REL_ "GenSigTimeoutTime" BU_SG_REL_ BCM1 SG_ 926 FAR_RGDL_Modul 1000;
BA_REL_ "GenSigTimeoutTime" BU_SG_REL_ FCM SG_ 926 FAR_RGDL_Modul 1000;
BA_REL_ "GenSigTimeoutTime" BU_SG_REL_ AFS SG_ 926 FAR_dKL_KS_Plus 1000;
BA_REL_ "GenSigTimeoutTime" BU_SG_REL_ BCM1 SG_ 926 FAR_dKL_KS_Plus 1000;
BA_REL_ "GenSigTimeoutTime" BU_SG_REL_ FCM SG_ 926 FAR_dKL_KS_Plus 1000;
BA_REL_ "GenSigTimeoutTime" BU_SG_REL_ AFS SG_ 926 FAR_RdKL_KS_Plus 1000;
BA_REL_ "GenSigTimeoutTime" BU_SG_REL_ BCM1 SG_ 926 FAR_RdKL_KS_Plus 1000;
BA_REL_ "GenSigTimeoutTime" BU_SG_REL_ FCM SG_ 926 FAR_RdKL_KS_Plus 1000;
BA_REL_ "GenSigTimeoutTime" BU_SG_REL_ AFS SG_ 926 FAR_dKL_KS_Gnd 1000;
BA_REL_ "GenSigTimeoutTime" BU_SG_REL_ BCM1 SG_ 926 FAR_dKL_KS_Gnd 1000;
BA_REL_ "GenSigTimeoutTime" BU_SG_REL_ FCM SG_ 926 FAR_dKL_KS_Gnd 1000;
BA_REL_ "GenSigTimeoutTime" BU_SG_REL_ AFS SG_ 926 FAR_RdKL_KS_Gnd 1000;
BA_REL_ "GenSigTimeoutTime" BU_SG_REL_ BCM1 SG_ 926 FAR_RdKL_KS_Gnd 1000;
BA_REL_ "GenSigTimeoutTime" BU_SG_REL_ FCM SG_ 926 FAR_RdKL_KS_Gnd 1000;
BA_REL_ "GenSigTimeoutTime" BU_SG_REL_ AFS SG_ 926 FAR_dKL_unplSign 1000;
BA_REL_ "GenSigTimeoutTime" BU_SG_REL_ BCM1 SG_ 926 FAR_dKL_unplSign 1000;
BA_REL_ "GenSigTimeoutTime" BU_SG_REL_ FCM SG_ 926 FAR_dKL_unplSign 1000;
BA_REL_ "GenSigTimeoutTime" BU_SG_REL_ AFS SG_ 926 FAR_RdKL_unplSign 1000;
BA_REL_ "GenSigTimeoutTime" BU_SG_REL_ BCM1 SG_ 926 FAR_RdKL_unplSign 1000;
BA_REL_ "GenSigTimeoutTime" BU_SG_REL_ FCM SG_ 926 FAR_RdKL_unplSign 1000;
BA_REL_ "GenSigTimeoutTime" BU_SG_REL_ AFS SG_ 926 FAR_5VdKL_KS_Gnd 1000;
BA_REL_ "GenSigTimeoutTime" BU_SG_REL_ BCM1 SG_ 926 FAR_5VdKL_KS_Gnd 1000;
BA_REL_ "GenSigTimeoutTime" BU_SG_REL_ FCM SG_ 926 FAR_5VdKL_KS_Gnd 1000;
BA_REL_ "GenSigTimeoutTime" BU_SG_REL_ AFS SG_ 926 FAR_R5VdKL_KS_Gnd 1000;
BA_REL_ "GenSigTimeoutTime" BU_SG_REL_ BCM1 SG_ 926 FAR_R5VdKL_KS_Gnd 1000;
BA_REL_ "GenSigTimeoutTime" BU_SG_REL_ FCM SG_ 926 FAR_R5VdKL_KS_Gnd 1000;
BA_REL_ "GenSigTimeoutTime" BU_SG_REL_ AFS SG_ 926 FAR_5VdKL_KS_UB 1000;
BA_REL_ "GenSigTimeoutTime" BU_SG_REL_ BCM1 SG_ 926 FAR_5VdKL_KS_UB 1000;
BA_REL_ "GenSigTimeoutTime" BU_SG_REL_ FCM SG_ 926 FAR_5VdKL_KS_UB 1000;
BA_REL_ "GenSigTimeoutTime" BU_SG_REL_ AFS SG_ 926 FAR_R5VdKL_KS_UB 1000;
BA_REL_ "GenSigTimeoutTime" BU_SG_REL_ BCM1 SG_ 926 FAR_R5VdKL_KS_UB 1000;
BA_REL_ "GenSigTimeoutTime" BU_SG_REL_ FCM SG_ 926 FAR_R5VdKL_KS_UB 1000;
BA_REL_ "GenSigTimeoutTime" BU_SG_REL_ AFS SG_ 1172 IAL_Mux 1000;
BA_REL_ "GenSigTimeoutTime" BU_SG_REL_ BCM1 SG_ 1172 IAL_Mux 1000;
BA_REL_ "GenSigTimeoutTime" BU_SG_REL_ FCM SG_ 1172 IAL_Mux 1000;
BA_REL_ "GenSigTimeoutTime" BU_SG_REL_ MXB SG_ 1172 IAL_Mux 1000;
BA_REL_ "GenSigTimeoutTime" BU_SG_REL_ AFS SG_ 1172 IAL_SW_Idt_Z01 1000;
BA_REL_ "GenSigTimeoutTime" BU_SG_REL_ BCM1 SG_ 1172 IAL_SW_Idt_Z01 1000;
BA_REL_ "GenSigTimeoutTime" BU_SG_REL_ FCM SG_ 1172 IAL_SW_Idt_Z01 1000;
BA_REL_ "GenSigTimeoutTime" BU_SG_REL_ MXB SG_ 1172 IAL_SW_Idt_Z01 1000;
BA_REL_ "GenSigTimeoutTime" BU_SG_REL_ AFS SG_ 1172 IAL_SW_Idt_Z08 1000;
BA_REL_ "GenSigTimeoutTime" BU_SG_REL_ BCM1 SG_ 1172 IAL_SW_Idt_Z08 1000;
BA_REL_ "GenSigTimeoutTime" BU_SG_REL_ FCM SG_ 1172 IAL_SW_Idt_Z08 1000;
BA_REL_ "GenSigTimeoutTime" BU_SG_REL_ MXB SG_ 1172 IAL_SW_Idt_Z08 1000;
BA_REL_ "GenSigTimeoutTime" BU_SG_REL_ AFS SG_ 1172 IAL_SW_Idx_Z04 1000;
BA_REL_ "GenSigTimeoutTime" BU_SG_REL_ BCM1 SG_ 1172 IAL_SW_Idx_Z04 1000;
BA_REL_ "GenSigTimeoutTime" BU_SG_REL_ FCM SG_ 1172 IAL_SW_Idx_Z04 1000;
BA_REL_ "GenSigTimeoutTime" BU_SG_REL_ MXB SG_ 1172 IAL_SW_Idx_Z04 1000;
BA_REL_ "GenSigTimeoutTime" BU_SG_REL_ AFS SG_ 1172 IAL_HW_Idt_Z07 1000;
BA_REL_ "GenSigTimeoutTime" BU_SG_REL_ BCM1 SG_ 1172 IAL_HW_Idt_Z07 1000;
BA_REL_ "GenSigTimeoutTime" BU_SG_REL_ FCM SG_ 1172 IAL_HW_Idt_Z07 1000;
BA_REL_ "GenSigTimeoutTime" BU_SG_REL_ MXB SG_ 1172 IAL_HW_Idt_Z07 1000;
BA_REL_ "GenSigTimeoutTime" BU_SG_REL_ AFS SG_ 1172 IAL_HW_Idx_Z03 1000;
BA_REL_ "GenSigTimeoutTime" BU_SG_REL_ BCM1 SG_ 1172 IAL_HW_Idx_Z03 1000;
BA_REL_ "GenSigTimeoutTime" BU_SG_REL_ FCM SG_ 1172 IAL_HW_Idx_Z03 1000;
BA_REL_ "GenSigTimeoutTime" BU_SG_REL_ MXB SG_ 1172 IAL_HW_Idx_Z03 1000;
BA_REL_ "GenSigTimeoutTime" BU_SG_REL_ AFS SG_ 1172 IAL_SW_Idt_Z02 1000;
BA_REL_ "GenSigTimeoutTime" BU_SG_REL_ BCM1 SG_ 1172 IAL_SW_Idt_Z02 1000;
BA_REL_ "GenSigTimeoutTime" BU_SG_REL_ FCM SG_ 1172 IAL_SW_Idt_Z02 1000;
BA_REL_ "GenSigTimeoutTime" BU_SG_REL_ MXB SG_ 1172 IAL_SW_Idt_Z02 1000;
BA_REL_ "GenSigTimeoutTime" BU_SG_REL_ AFS SG_ 1172 IAL_SW_Idt_Z09 1000;
BA_REL_ "GenSigTimeoutTime" BU_SG_REL_ BCM1 SG_ 1172 IAL_SW_Idt_Z09 1000;
BA_REL_ "GenSigTimeoutTime" BU_SG_REL_ FCM SG_ 1172 IAL_SW_Idt_Z09 1000;
BA_REL_ "GenSigTimeoutTime" BU_SG_REL_ MXB SG_ 1172 IAL_SW_Idt_Z09 1000;
BA_REL_ "GenSigTimeoutTime" BU_SG_REL_ AFS SG_ 1172 IAL_HW_Idt_Z01 1000;
BA_REL_ "GenSigTimeoutTime" BU_SG_REL_ BCM1 SG_ 1172 IAL_HW_Idt_Z01 1000;
BA_REL_ "GenSigTimeoutTime" BU_SG_REL_ FCM SG_ 1172 IAL_HW_Idt_Z01 1000;
BA_REL_ "GenSigTimeoutTime" BU_SG_REL_ MXB SG_ 1172 IAL_HW_Idt_Z01 1000;
BA_REL_ "GenSigTimeoutTime" BU_SG_REL_ AFS SG_ 1172 IAL_HW_Idt_Z08 1000;
BA_REL_ "GenSigTimeoutTime" BU_SG_REL_ BCM1 SG_ 1172 IAL_HW_Idt_Z08 1000;
BA_REL_ "GenSigTimeoutTime" BU_SG_REL_ FCM SG_ 1172 IAL_HW_Idt_Z08 1000;
BA_REL_ "GenSigTimeoutTime" BU_SG_REL_ MXB SG_ 1172 IAL_HW_Idt_Z08 1000;
BA_REL_ "GenSigTimeoutTime" BU_SG_REL_ AFS SG_ 1172 IAL_SW_Idt_Z03 1000;
BA_REL_ "GenSigTimeoutTime" BU_SG_REL_ BCM1 SG_ 1172 IAL_SW_Idt_Z03 1000;
BA_REL_ "GenSigTimeoutTime" BU_SG_REL_ FCM SG_ 1172 IAL_SW_Idt_Z03 1000;
BA_REL_ "GenSigTimeoutTime" BU_SG_REL_ MXB SG_ 1172 IAL_SW_Idt_Z03 1000;
BA_REL_ "GenSigTimeoutTime" BU_SG_REL_ AFS SG_ 1172 IAL_SW_Idt_Z10 1000;
BA_REL_ "GenSigTimeoutTime" BU_SG_REL_ BCM1 SG_ 1172 IAL_SW_Idt_Z10 1000;
BA_REL_ "GenSigTimeoutTime" BU_SG_REL_ FCM SG_ 1172 IAL_SW_Idt_Z10 1000;
BA_REL_ "GenSigTimeoutTime" BU_SG_REL_ MXB SG_ 1172 IAL_SW_Idt_Z10 1000;
BA_REL_ "GenSigTimeoutTime" BU_SG_REL_ AFS SG_ 1172 IAL_HW_Idt_Z02 1000;
BA_REL_ "GenSigTimeoutTime" BU_SG_REL_ BCM1 SG_ 1172 IAL_HW_Idt_Z02 1000;
BA_REL_ "GenSigTimeoutTime" BU_SG_REL_ FCM SG_ 1172 IAL_HW_Idt_Z02 1000;
BA_REL_ "GenSigTimeoutTime" BU_SG_REL_ MXB SG_ 1172 IAL_HW_Idt_Z02 1000;
BA_REL_ "GenSigTimeoutTime" BU_SG_REL_ AFS SG_ 1172 IAL_HW_Idt_Z09 1000;
BA_REL_ "GenSigTimeoutTime" BU_SG_REL_ BCM1 SG_ 1172 IAL_HW_Idt_Z09 1000;
BA_REL_ "GenSigTimeoutTime" BU_SG_REL_ FCM SG_ 1172 IAL_HW_Idt_Z09 1000;
BA_REL_ "GenSigTimeoutTime" BU_SG_REL_ MXB SG_ 1172 IAL_HW_Idt_Z09 1000;
BA_REL_ "GenSigTimeoutTime" BU_SG_REL_ AFS SG_ 1172 IAL_SW_Idt_Z04 1000;
BA_REL_ "GenSigTimeoutTime" BU_SG_REL_ BCM1 SG_ 1172 IAL_SW_Idt_Z04 1000;
BA_REL_ "GenSigTimeoutTime" BU_SG_REL_ FCM SG_ 1172 IAL_SW_Idt_Z04 1000;
BA_REL_ "GenSigTimeoutTime" BU_SG_REL_ MXB SG_ 1172 IAL_SW_Idt_Z04 1000;
BA_REL_ "GenSigTimeoutTime" BU_SG_REL_ AFS SG_ 1172 IAL_SW_Idt_Z11 1000;
BA_REL_ "GenSigTimeoutTime" BU_SG_REL_ BCM1 SG_ 1172 IAL_SW_Idt_Z11 1000;
BA_REL_ "GenSigTimeoutTime" BU_SG_REL_ FCM SG_ 1172 IAL_SW_Idt_Z11 1000;
BA_REL_ "GenSigTimeoutTime" BU_SG_REL_ MXB SG_ 1172 IAL_SW_Idt_Z11 1000;
BA_REL_ "GenSigTimeoutTime" BU_SG_REL_ AFS SG_ 1172 IAL_HW_Idt_Z03 1000;
BA_REL_ "GenSigTimeoutTime" BU_SG_REL_ BCM1 SG_ 1172 IAL_HW_Idt_Z03 1000;
BA_REL_ "GenSigTimeoutTime" BU_SG_REL_ FCM SG_ 1172 IAL_HW_Idt_Z03 1000;
BA_REL_ "GenSigTimeoutTime" BU_SG_REL_ MXB SG_ 1172 IAL_HW_Idt_Z03 1000;
BA_REL_ "GenSigTimeoutTime" BU_SG_REL_ AFS SG_ 1172 IAL_HW_Idt_Z10 1000;
BA_REL_ "GenSigTimeoutTime" BU_SG_REL_ BCM1 SG_ 1172 IAL_HW_Idt_Z10 1000;
BA_REL_ "GenSigTimeoutTime" BU_SG_REL_ FCM SG_ 1172 IAL_HW_Idt_Z10 1000;
BA_REL_ "GenSigTimeoutTime" BU_SG_REL_ MXB SG_ 1172 IAL_HW_Idt_Z10 1000;
BA_REL_ "GenSigTimeoutTime" BU_SG_REL_ AFS SG_ 1172 IAL_SW_Idt_Z05 1000;
BA_REL_ "GenSigTimeoutTime" BU_SG_REL_ BCM1 SG_ 1172 IAL_SW_Idt_Z05 1000;
BA_REL_ "GenSigTimeoutTime" BU_SG_REL_ FCM SG_ 1172 IAL_SW_Idt_Z05 1000;
BA_REL_ "GenSigTimeoutTime" BU_SG_REL_ MXB SG_ 1172 IAL_SW_Idt_Z05 1000;
BA_REL_ "GenSigTimeoutTime" BU_SG_REL_ AFS SG_ 1172 IAL_SW_Idx_Z01 1000;
BA_REL_ "GenSigTimeoutTime" BU_SG_REL_ BCM1 SG_ 1172 IAL_SW_Idx_Z01 1000;
BA_REL_ "GenSigTimeoutTime" BU_SG_REL_ FCM SG_ 1172 IAL_SW_Idx_Z01 1000;
BA_REL_ "GenSigTimeoutTime" BU_SG_REL_ MXB SG_ 1172 IAL_SW_Idx_Z01 1000;
BA_REL_ "GenSigTimeoutTime" BU_SG_REL_ AFS SG_ 1172 IAL_HW_Idt_Z04 1000;
BA_REL_ "GenSigTimeoutTime" BU_SG_REL_ BCM1 SG_ 1172 IAL_HW_Idt_Z04 1000;
BA_REL_ "GenSigTimeoutTime" BU_SG_REL_ FCM SG_ 1172 IAL_HW_Idt_Z04 1000;
BA_REL_ "GenSigTimeoutTime" BU_SG_REL_ MXB SG_ 1172 IAL_HW_Idt_Z04 1000;
BA_REL_ "GenSigTimeoutTime" BU_SG_REL_ AFS SG_ 1172 IAL_HW_Idt_Z11 1000;
BA_REL_ "GenSigTimeoutTime" BU_SG_REL_ BCM1 SG_ 1172 IAL_HW_Idt_Z11 1000;
BA_REL_ "GenSigTimeoutTime" BU_SG_REL_ FCM SG_ 1172 IAL_HW_Idt_Z11 1000;
BA_REL_ "GenSigTimeoutTime" BU_SG_REL_ MXB SG_ 1172 IAL_HW_Idt_Z11 1000;
BA_REL_ "GenSigTimeoutTime" BU_SG_REL_ AFS SG_ 1172 IAL_SW_Idt_Z06 1000;
BA_REL_ "GenSigTimeoutTime" BU_SG_REL_ BCM1 SG_ 1172 IAL_SW_Idt_Z06 1000;
BA_REL_ "GenSigTimeoutTime" BU_SG_REL_ FCM SG_ 1172 IAL_SW_Idt_Z06 1000;
BA_REL_ "GenSigTimeoutTime" BU_SG_REL_ MXB SG_ 1172 IAL_SW_Idt_Z06 1000;
BA_REL_ "GenSigTimeoutTime" BU_SG_REL_ AFS SG_ 1172 IAL_SW_Idx_Z02 1000;
BA_REL_ "GenSigTimeoutTime" BU_SG_REL_ BCM1 SG_ 1172 IAL_SW_Idx_Z02 1000;
BA_REL_ "GenSigTimeoutTime" BU_SG_REL_ FCM SG_ 1172 IAL_SW_Idx_Z02 1000;
BA_REL_ "GenSigTimeoutTime" BU_SG_REL_ MXB SG_ 1172 IAL_SW_Idx_Z02 1000;
BA_REL_ "GenSigTimeoutTime" BU_SG_REL_ AFS SG_ 1172 IAL_HW_Idt_Z05 1000;
BA_REL_ "GenSigTimeoutTime" BU_SG_REL_ BCM1 SG_ 1172 IAL_HW_Idt_Z05 1000;
BA_REL_ "GenSigTimeoutTime" BU_SG_REL_ FCM SG_ 1172 IAL_HW_Idt_Z05 1000;
BA_REL_ "GenSigTimeoutTime" BU_SG_REL_ MXB SG_ 1172 IAL_HW_Idt_Z05 1000;
BA_REL_ "GenSigTimeoutTime" BU_SG_REL_ AFS SG_ 1172 IAL_HW_Idx_Z01 1000;
BA_REL_ "GenSigTimeoutTime" BU_SG_REL_ BCM1 SG_ 1172 IAL_HW_Idx_Z01 1000;
BA_REL_ "GenSigTimeoutTime" BU_SG_REL_ FCM SG_ 1172 IAL_HW_Idx_Z01 1000;
BA_REL_ "GenSigTimeoutTime" BU_SG_REL_ MXB SG_ 1172 IAL_HW_Idx_Z01 1000;
BA_REL_ "GenSigTimeoutTime" BU_SG_REL_ AFS SG_ 1172 IAL_SW_Idt_Z07 1000;
BA_REL_ "GenSigTimeoutTime" BU_SG_REL_ BCM1 SG_ 1172 IAL_SW_Idt_Z07 1000;
BA_REL_ "GenSigTimeoutTime" BU_SG_REL_ FCM SG_ 1172 IAL_SW_Idt_Z07 1000;
BA_REL_ "GenSigTimeoutTime" BU_SG_REL_ MXB SG_ 1172 IAL_SW_Idt_Z07 1000;
BA_REL_ "GenSigTimeoutTime" BU_SG_REL_ AFS SG_ 1172 IAL_SW_Idx_Z03 1000;
BA_REL_ "GenSigTimeoutTime" BU_SG_REL_ BCM1 SG_ 1172 IAL_SW_Idx_Z03 1000;
BA_REL_ "GenSigTimeoutTime" BU_SG_REL_ FCM SG_ 1172 IAL_SW_Idx_Z03 1000;
BA_REL_ "GenSigTimeoutTime" BU_SG_REL_ MXB SG_ 1172 IAL_SW_Idx_Z03 1000;
BA_REL_ "GenSigTimeoutTime" BU_SG_REL_ AFS SG_ 1172 IAL_HW_Idt_Z06 1000;
BA_REL_ "GenSigTimeoutTime" BU_SG_REL_ BCM1 SG_ 1172 IAL_HW_Idt_Z06 1000;
BA_REL_ "GenSigTimeoutTime" BU_SG_REL_ FCM SG_ 1172 IAL_HW_Idt_Z06 1000;
BA_REL_ "GenSigTimeoutTime" BU_SG_REL_ MXB SG_ 1172 IAL_HW_Idt_Z06 1000;
BA_REL_ "GenSigTimeoutTime" BU_SG_REL_ AFS SG_ 1172 IAL_HW_Idx_Z02 1000;
BA_REL_ "GenSigTimeoutTime" BU_SG_REL_ BCM1 SG_ 1172 IAL_HW_Idx_Z02 1000;
BA_REL_ "GenSigTimeoutTime" BU_SG_REL_ FCM SG_ 1172 IAL_HW_Idx_Z02 1000;
BA_REL_ "GenSigTimeoutTime" BU_SG_REL_ MXB SG_ 1172 IAL_HW_Idx_Z02 1000;
BA_REL_ "GenSigTimeoutTime" BU_SG_REL_ AFS SG_ 1174 IAR_Mux 1000;
BA_REL_ "GenSigTimeoutTime" BU_SG_REL_ BCM1 SG_ 1174 IAR_Mux 1000;
BA_REL_ "GenSigTimeoutTime" BU_SG_REL_ FCM SG_ 1174 IAR_Mux 1000;
BA_REL_ "GenSigTimeoutTime" BU_SG_REL_ MXB SG_ 1174 IAR_Mux 1000;
BA_REL_ "GenSigTimeoutTime" BU_SG_REL_ AFS SG_ 1174 IAR_SW_Idt_Z01 1000;
BA_REL_ "GenSigTimeoutTime" BU_SG_REL_ BCM1 SG_ 1174 IAR_SW_Idt_Z01 1000;
BA_REL_ "GenSigTimeoutTime" BU_SG_REL_ FCM SG_ 1174 IAR_SW_Idt_Z01 1000;
BA_REL_ "GenSigTimeoutTime" BU_SG_REL_ MXB SG_ 1174 IAR_SW_Idt_Z01 1000;
BA_REL_ "GenSigTimeoutTime" BU_SG_REL_ AFS SG_ 1174 IAR_SW_Idt_Z08 1000;
BA_REL_ "GenSigTimeoutTime" BU_SG_REL_ BCM1 SG_ 1174 IAR_SW_Idt_Z08 1000;
BA_REL_ "GenSigTimeoutTime" BU_SG_REL_ FCM SG_ 1174 IAR_SW_Idt_Z08 1000;
BA_REL_ "GenSigTimeoutTime" BU_SG_REL_ MXB SG_ 1174 IAR_SW_Idt_Z08 1000;
BA_REL_ "GenSigTimeoutTime" BU_SG_REL_ AFS SG_ 1174 IAR_SW_Idx_Z04 1000;
BA_REL_ "GenSigTimeoutTime" BU_SG_REL_ BCM1 SG_ 1174 IAR_SW_Idx_Z04 1000;
BA_REL_ "GenSigTimeoutTime" BU_SG_REL_ FCM SG_ 1174 IAR_SW_Idx_Z04 1000;
BA_REL_ "GenSigTimeoutTime" BU_SG_REL_ MXB SG_ 1174 IAR_SW_Idx_Z04 1000;
BA_REL_ "GenSigTimeoutTime" BU_SG_REL_ AFS SG_ 1174 IAR_HW_Idt_Z07 1000;
BA_REL_ "GenSigTimeoutTime" BU_SG_REL_ BCM1 SG_ 1174 IAR_HW_Idt_Z07 1000;
BA_REL_ "GenSigTimeoutTime" BU_SG_REL_ FCM SG_ 1174 IAR_HW_Idt_Z07 1000;
BA_REL_ "GenSigTimeoutTime" BU_SG_REL_ MXB SG_ 1174 IAR_HW_Idt_Z07 1000;
BA_REL_ "GenSigTimeoutTime" BU_SG_REL_ AFS SG_ 1174 IAR_HW_Idx_Z03 1000;
BA_REL_ "GenSigTimeoutTime" BU_SG_REL_ BCM1 SG_ 1174 IAR_HW_Idx_Z03 1000;
BA_REL_ "GenSigTimeoutTime" BU_SG_REL_ FCM SG_ 1174 IAR_HW_Idx_Z03 1000;
BA_REL_ "GenSigTimeoutTime" BU_SG_REL_ MXB SG_ 1174 IAR_HW_Idx_Z03 1000;
BA_REL_ "GenSigTimeoutTime" BU_SG_REL_ AFS SG_ 1174 IAR_SW_Idt_Z02 1000;
BA_REL_ "GenSigTimeoutTime" BU_SG_REL_ BCM1 SG_ 1174 IAR_SW_Idt_Z02 1000;
BA_REL_ "GenSigTimeoutTime" BU_SG_REL_ FCM SG_ 1174 IAR_SW_Idt_Z02 1000;
BA_REL_ "GenSigTimeoutTime" BU_SG_REL_ MXB SG_ 1174 IAR_SW_Idt_Z02 1000;
BA_REL_ "GenSigTimeoutTime" BU_SG_REL_ AFS SG_ 1174 IAR_SW_Idt_Z09 1000;
BA_REL_ "GenSigTimeoutTime" BU_SG_REL_ BCM1 SG_ 1174 IAR_SW_Idt_Z09 1000;
BA_REL_ "GenSigTimeoutTime" BU_SG_REL_ FCM SG_ 1174 IAR_SW_Idt_Z09 1000;
BA_REL_ "GenSigTimeoutTime" BU_SG_REL_ MXB SG_ 1174 IAR_SW_Idt_Z09 1000;
BA_REL_ "GenSigTimeoutTime" BU_SG_REL_ AFS SG_ 1174 IAR_HW_Idt_Z01 1000;
BA_REL_ "GenSigTimeoutTime" BU_SG_REL_ BCM1 SG_ 1174 IAR_HW_Idt_Z01 1000;
BA_REL_ "GenSigTimeoutTime" BU_SG_REL_ FCM SG_ 1174 IAR_HW_Idt_Z01 1000;
BA_REL_ "GenSigTimeoutTime" BU_SG_REL_ MXB SG_ 1174 IAR_HW_Idt_Z01 1000;
BA_REL_ "GenSigTimeoutTime" BU_SG_REL_ AFS SG_ 1174 IAR_HW_Idt_Z08 1000;
BA_REL_ "GenSigTimeoutTime" BU_SG_REL_ BCM1 SG_ 1174 IAR_HW_Idt_Z08 1000;
BA_REL_ "GenSigTimeoutTime" BU_SG_REL_ FCM SG_ 1174 IAR_HW_Idt_Z08 1000;
BA_REL_ "GenSigTimeoutTime" BU_SG_REL_ MXB SG_ 1174 IAR_HW_Idt_Z08 1000;
BA_REL_ "GenSigTimeoutTime" BU_SG_REL_ AFS SG_ 1174 IAR_SW_Idt_Z03 1000;
BA_REL_ "GenSigTimeoutTime" BU_SG_REL_ BCM1 SG_ 1174 IAR_SW_Idt_Z03 1000;
BA_REL_ "GenSigTimeoutTime" BU_SG_REL_ FCM SG_ 1174 IAR_SW_Idt_Z03 1000;
BA_REL_ "GenSigTimeoutTime" BU_SG_REL_ MXB SG_ 1174 IAR_SW_Idt_Z03 1000;
BA_REL_ "GenSigTimeoutTime" BU_SG_REL_ AFS SG_ 1174 IAR_SW_Idt_Z10 1000;
BA_REL_ "GenSigTimeoutTime" BU_SG_REL_ BCM1 SG_ 1174 IAR_SW_Idt_Z10 1000;
BA_REL_ "GenSigTimeoutTime" BU_SG_REL_ FCM SG_ 1174 IAR_SW_Idt_Z10 1000;
BA_REL_ "GenSigTimeoutTime" BU_SG_REL_ MXB SG_ 1174 IAR_SW_Idt_Z10 1000;
BA_REL_ "GenSigTimeoutTime" BU_SG_REL_ AFS SG_ 1174 IAR_HW_Idt_Z02 1000;
BA_REL_ "GenSigTimeoutTime" BU_SG_REL_ BCM1 SG_ 1174 IAR_HW_Idt_Z02 1000;
BA_REL_ "GenSigTimeoutTime" BU_SG_REL_ FCM SG_ 1174 IAR_HW_Idt_Z02 1000;
BA_REL_ "GenSigTimeoutTime" BU_SG_REL_ MXB SG_ 1174 IAR_HW_Idt_Z02 1000;
BA_REL_ "GenSigTimeoutTime" BU_SG_REL_ AFS SG_ 1174 IAR_HW_Idt_Z09 1000;
BA_REL_ "GenSigTimeoutTime" BU_SG_REL_ BCM1 SG_ 1174 IAR_HW_Idt_Z09 1000;
BA_REL_ "GenSigTimeoutTime" BU_SG_REL_ FCM SG_ 1174 IAR_HW_Idt_Z09 1000;
BA_REL_ "GenSigTimeoutTime" BU_SG_REL_ MXB SG_ 1174 IAR_HW_Idt_Z09 1000;
BA_REL_ "GenSigTimeoutTime" BU_SG_REL_ AFS SG_ 1174 IAR_SW_Idt_Z04 1000;
BA_REL_ "GenSigTimeoutTime" BU_SG_REL_ BCM1 SG_ 1174 IAR_SW_Idt_Z04 1000;
BA_REL_ "GenSigTimeoutTime" BU_SG_REL_ FCM SG_ 1174 IAR_SW_Idt_Z04 1000;
BA_REL_ "GenSigTimeoutTime" BU_SG_REL_ MXB SG_ 1174 IAR_SW_Idt_Z04 1000;
BA_REL_ "GenSigTimeoutTime" BU_SG_REL_ AFS SG_ 1174 IAR_SW_Idt_Z11 1000;
BA_REL_ "GenSigTimeoutTime" BU_SG_REL_ BCM1 SG_ 1174 IAR_SW_Idt_Z11 1000;
BA_REL_ "GenSigTimeoutTime" BU_SG_REL_ FCM SG_ 1174 IAR_SW_Idt_Z11 1000;
BA_REL_ "GenSigTimeoutTime" BU_SG_REL_ MXB SG_ 1174 IAR_SW_Idt_Z11 1000;
BA_REL_ "GenSigTimeoutTime" BU_SG_REL_ AFS SG_ 1174 IAR_HW_Idt_Z03 1000;
BA_REL_ "GenSigTimeoutTime" BU_SG_REL_ BCM1 SG_ 1174 IAR_HW_Idt_Z03 1000;
BA_REL_ "GenSigTimeoutTime" BU_SG_REL_ FCM SG_ 1174 IAR_HW_Idt_Z03 1000;
BA_REL_ "GenSigTimeoutTime" BU_SG_REL_ MXB SG_ 1174 IAR_HW_Idt_Z03 1000;
BA_REL_ "GenSigTimeoutTime" BU_SG_REL_ AFS SG_ 1174 IAR_HW_Idt_Z10 1000;
BA_REL_ "GenSigTimeoutTime" BU_SG_REL_ BCM1 SG_ 1174 IAR_HW_Idt_Z10 1000;
BA_REL_ "GenSigTimeoutTime" BU_SG_REL_ FCM SG_ 1174 IAR_HW_Idt_Z10 1000;
BA_REL_ "GenSigTimeoutTime" BU_SG_REL_ MXB SG_ 1174 IAR_HW_Idt_Z10 1000;
BA_REL_ "GenSigTimeoutTime" BU_SG_REL_ AFS SG_ 1174 IAR_SW_Idt_Z05 1000;
BA_REL_ "GenSigTimeoutTime" BU_SG_REL_ BCM1 SG_ 1174 IAR_SW_Idt_Z05 1000;
BA_REL_ "GenSigTimeoutTime" BU_SG_REL_ FCM SG_ 1174 IAR_SW_Idt_Z05 1000;
BA_REL_ "GenSigTimeoutTime" BU_SG_REL_ MXB SG_ 1174 IAR_SW_Idt_Z05 1000;
BA_REL_ "GenSigTimeoutTime" BU_SG_REL_ AFS SG_ 1174 IAR_SW_Idx_Z01 1000;
BA_REL_ "GenSigTimeoutTime" BU_SG_REL_ BCM1 SG_ 1174 IAR_SW_Idx_Z01 1000;
BA_REL_ "GenSigTimeoutTime" BU_SG_REL_ FCM SG_ 1174 IAR_SW_Idx_Z01 1000;
BA_REL_ "GenSigTimeoutTime" BU_SG_REL_ MXB SG_ 1174 IAR_SW_Idx_Z01 1000;
BA_REL_ "GenSigTimeoutTime" BU_SG_REL_ AFS SG_ 1174 IAR_HW_Idt_Z04 1000;
BA_REL_ "GenSigTimeoutTime" BU_SG_REL_ BCM1 SG_ 1174 IAR_HW_Idt_Z04 1000;
BA_REL_ "GenSigTimeoutTime" BU_SG_REL_ FCM SG_ 1174 IAR_HW_Idt_Z04 1000;
BA_REL_ "GenSigTimeoutTime" BU_SG_REL_ MXB SG_ 1174 IAR_HW_Idt_Z04 1000;
BA_REL_ "GenSigTimeoutTime" BU_SG_REL_ AFS SG_ 1174 IAR_HW_Idt_Z11 1000;
BA_REL_ "GenSigTimeoutTime" BU_SG_REL_ BCM1 SG_ 1174 IAR_HW_Idt_Z11 1000;
BA_REL_ "GenSigTimeoutTime" BU_SG_REL_ FCM SG_ 1174 IAR_HW_Idt_Z11 1000;
BA_REL_ "GenSigTimeoutTime" BU_SG_REL_ MXB SG_ 1174 IAR_HW_Idt_Z11 1000;
BA_REL_ "GenSigTimeoutTime" BU_SG_REL_ AFS SG_ 1174 IAR_SW_Idt_Z06 1000;
BA_REL_ "GenSigTimeoutTime" BU_SG_REL_ BCM1 SG_ 1174 IAR_SW_Idt_Z06 1000;
BA_REL_ "GenSigTimeoutTime" BU_SG_REL_ FCM SG_ 1174 IAR_SW_Idt_Z06 1000;
BA_REL_ "GenSigTimeoutTime" BU_SG_REL_ MXB SG_ 1174 IAR_SW_Idt_Z06 1000;
BA_REL_ "GenSigTimeoutTime" BU_SG_REL_ AFS SG_ 1174 IAR_SW_Idx_Z02 1000;
BA_REL_ "GenSigTimeoutTime" BU_SG_REL_ BCM1 SG_ 1174 IAR_SW_Idx_Z02 1000;
BA_REL_ "GenSigTimeoutTime" BU_SG_REL_ FCM SG_ 1174 IAR_SW_Idx_Z02 1000;
BA_REL_ "GenSigTimeoutTime" BU_SG_REL_ MXB SG_ 1174 IAR_SW_Idx_Z02 1000;
BA_REL_ "GenSigTimeoutTime" BU_SG_REL_ AFS SG_ 1174 IAR_HW_Idt_Z05 1000;
BA_REL_ "GenSigTimeoutTime" BU_SG_REL_ BCM1 SG_ 1174 IAR_HW_Idt_Z05 1000;
BA_REL_ "GenSigTimeoutTime" BU_SG_REL_ FCM SG_ 1174 IAR_HW_Idt_Z05 1000;
BA_REL_ "GenSigTimeoutTime" BU_SG_REL_ MXB SG_ 1174 IAR_HW_Idt_Z05 1000;
BA_REL_ "GenSigTimeoutTime" BU_SG_REL_ AFS SG_ 1174 IAR_HW_Idx_Z01 1000;
BA_REL_ "GenSigTimeoutTime" BU_SG_REL_ BCM1 SG_ 1174 IAR_HW_Idx_Z01 1000;
BA_REL_ "GenSigTimeoutTime" BU_SG_REL_ FCM SG_ 1174 IAR_HW_Idx_Z01 1000;
BA_REL_ "GenSigTimeoutTime" BU_SG_REL_ MXB SG_ 1174 IAR_HW_Idx_Z01 1000;
BA_REL_ "GenSigTimeoutTime" BU_SG_REL_ AFS SG_ 1174 IAR_SW_Idt_Z07 1000;
BA_REL_ "GenSigTimeoutTime" BU_SG_REL_ BCM1 SG_ 1174 IAR_SW_Idt_Z07 1000;
BA_REL_ "GenSigTimeoutTime" BU_SG_REL_ FCM SG_ 1174 IAR_SW_Idt_Z07 1000;
BA_REL_ "GenSigTimeoutTime" BU_SG_REL_ MXB SG_ 1174 IAR_SW_Idt_Z07 1000;
BA_REL_ "GenSigTimeoutTime" BU_SG_REL_ AFS SG_ 1174 IAR_SW_Idx_Z03 1000;
BA_REL_ "GenSigTimeoutTime" BU_SG_REL_ BCM1 SG_ 1174 IAR_SW_Idx_Z03 1000;
BA_REL_ "GenSigTimeoutTime" BU_SG_REL_ FCM SG_ 1174 IAR_SW_Idx_Z03 1000;
BA_REL_ "GenSigTimeoutTime" BU_SG_REL_ MXB SG_ 1174 IAR_SW_Idx_Z03 1000;
BA_REL_ "GenSigTimeoutTime" BU_SG_REL_ AFS SG_ 1174 IAR_HW_Idt_Z06 1000;
BA_REL_ "GenSigTimeoutTime" BU_SG_REL_ BCM1 SG_ 1174 IAR_HW_Idt_Z06 1000;
BA_REL_ "GenSigTimeoutTime" BU_SG_REL_ FCM SG_ 1174 IAR_HW_Idt_Z06 1000;
BA_REL_ "GenSigTimeoutTime" BU_SG_REL_ MXB SG_ 1174 IAR_HW_Idt_Z06 1000;
BA_REL_ "GenSigTimeoutTime" BU_SG_REL_ AFS SG_ 1174 IAR_HW_Idx_Z02 1000;
BA_REL_ "GenSigTimeoutTime" BU_SG_REL_ BCM1 SG_ 1174 IAR_HW_Idx_Z02 1000;
BA_REL_ "GenSigTimeoutTime" BU_SG_REL_ FCM SG_ 1174 IAR_HW_Idx_Z02 1000;
BA_REL_ "GenSigTimeoutTime" BU_SG_REL_ MXB SG_ 1174 IAR_HW_Idx_Z02 1000;
BA_REL_ "GenSigTimeoutTime" BU_SG_REL_ AFS SG_ 1176 KAL_BG_LWR_O 1000;
BA_REL_ "GenSigTimeoutTime" BU_SG_REL_ BCM1 SG_ 1176 KAL_BG_LWR_O 1000;
BA_REL_ "GenSigTimeoutTime" BU_SG_REL_ FCM SG_ 1176 KAL_BG_LWR_O 1000;
BA_REL_ "GenSigTimeoutTime" BU_SG_REL_ MXB SG_ 1176 KAL_BG_LWR_O 1000;
BA_REL_ "GenSigTimeoutTime" BU_SG_REL_ AFS SG_ 1176 KAL_BG_LWR_U 1000;
BA_REL_ "GenSigTimeoutTime" BU_SG_REL_ BCM1 SG_ 1176 KAL_BG_LWR_U 1000;
BA_REL_ "GenSigTimeoutTime" BU_SG_REL_ FCM SG_ 1176 KAL_BG_LWR_U 1000;
BA_REL_ "GenSigTimeoutTime" BU_SG_REL_ MXB SG_ 1176 KAL_BG_LWR_U 1000;
BA_REL_ "GenSigTimeoutTime" BU_SG_REL_ AFS SG_ 1176 KAL_BG_dKL_L 1000;
BA_REL_ "GenSigTimeoutTime" BU_SG_REL_ BCM1 SG_ 1176 KAL_BG_dKL_L 1000;
BA_REL_ "GenSigTimeoutTime" BU_SG_REL_ FCM SG_ 1176 KAL_BG_dKL_L 1000;
BA_REL_ "GenSigTimeoutTime" BU_SG_REL_ AFS SG_ 1176 KAL_BG_dKL_R 1000;
BA_REL_ "GenSigTimeoutTime" BU_SG_REL_ BCM1 SG_ 1176 KAL_BG_dKL_R 1000;
BA_REL_ "GenSigTimeoutTime" BU_SG_REL_ FCM SG_ 1176 KAL_BG_dKL_R 1000;
BA_REL_ "GenSigTimeoutTime" BU_SG_REL_ AFS SG_ 1176 KAL_Scheinw_Var 1000;
BA_REL_ "GenSigTimeoutTime" BU_SG_REL_ BCM1 SG_ 1176 KAL_Scheinw_Var 1000;
BA_REL_ "GenSigTimeoutTime" BU_SG_REL_ FCM SG_ 1176 KAL_Scheinw_Var 1000;
BA_REL_ "GenSigTimeoutTime" BU_SG_REL_ AFS SG_ 1176 KAL_BG_gLW_O 1000;
BA_REL_ "GenSigTimeoutTime" BU_SG_REL_ BCM1 SG_ 1176 KAL_BG_gLW_O 1000;
BA_REL_ "GenSigTimeoutTime" BU_SG_REL_ FCM SG_ 1176 KAL_BG_gLW_O 1000;
BA_REL_ "GenSigTimeoutTime" BU_SG_REL_ AFS SG_ 1184 AFS_L_Scheinw_Var_1 1000;
BA_REL_ "GenSigTimeoutTime" BU_SG_REL_ BCM1 SG_ 1184 AFS_L_Scheinw_Var_1 1000;
BA_REL_ "GenSigTimeoutTime" BU_SG_REL_ FCM SG_ 1184 AFS_L_Scheinw_Var_1 1000;
BA_REL_ "GenSigTimeoutTime" BU_SG_REL_ AFS SG_ 1184 AFS_L_Scheinw_Var_2 1000;
BA_REL_ "GenSigTimeoutTime" BU_SG_REL_ BCM1 SG_ 1184 AFS_L_Scheinw_Var_2 1000;
BA_REL_ "GenSigTimeoutTime" BU_SG_REL_ FCM SG_ 1184 AFS_L_Scheinw_Var_2 1000;
BA_REL_ "GenSigTimeoutTime" BU_SG_REL_ AFS SG_ 1178 KAR_BG_LWR_O 1000;
BA_REL_ "GenSigTimeoutTime" BU_SG_REL_ BCM1 SG_ 1178 KAR_BG_LWR_O 1000;
BA_REL_ "GenSigTimeoutTime" BU_SG_REL_ FCM SG_ 1178 KAR_BG_LWR_O 1000;
BA_REL_ "GenSigTimeoutTime" BU_SG_REL_ MXB SG_ 1178 KAR_BG_LWR_O 1000;
BA_REL_ "GenSigTimeoutTime" BU_SG_REL_ AFS SG_ 1178 KAR_BG_LWR_U 1000;
BA_REL_ "GenSigTimeoutTime" BU_SG_REL_ BCM1 SG_ 1178 KAR_BG_LWR_U 1000;
BA_REL_ "GenSigTimeoutTime" BU_SG_REL_ FCM SG_ 1178 KAR_BG_LWR_U 1000;
BA_REL_ "GenSigTimeoutTime" BU_SG_REL_ MXB SG_ 1178 KAR_BG_LWR_U 1000;
BA_REL_ "GenSigTimeoutTime" BU_SG_REL_ AFS SG_ 1178 KAR_BG_dKL_L 1000;
BA_REL_ "GenSigTimeoutTime" BU_SG_REL_ BCM1 SG_ 1178 KAR_BG_dKL_L 1000;
BA_REL_ "GenSigTimeoutTime" BU_SG_REL_ FCM SG_ 1178 KAR_BG_dKL_L 1000;
BA_REL_ "GenSigTimeoutTime" BU_SG_REL_ AFS SG_ 1178 KAR_BG_dKL_R 1000;
BA_REL_ "GenSigTimeoutTime" BU_SG_REL_ BCM1 SG_ 1178 KAR_BG_dKL_R 1000;
BA_REL_ "GenSigTimeoutTime" BU_SG_REL_ FCM SG_ 1178 KAR_BG_dKL_R 1000;
BA_REL_ "GenSigTimeoutTime" BU_SG_REL_ AFS SG_ 1178 KAR_Scheinw_Var 1000;
BA_REL_ "GenSigTimeoutTime" BU_SG_REL_ BCM1 SG_ 1178 KAR_Scheinw_Var 1000;
BA_REL_ "GenSigTimeoutTime" BU_SG_REL_ FCM SG_ 1178 KAR_Scheinw_Var 1000;
BA_REL_ "GenSigTimeoutTime" BU_SG_REL_ AFS SG_ 1178 KAR_BG_gLW_O 1000;
BA_REL_ "GenSigTimeoutTime" BU_SG_REL_ BCM1 SG_ 1178 KAR_BG_gLW_O 1000;
BA_REL_ "GenSigTimeoutTime" BU_SG_REL_ FCM SG_ 1178 KAR_BG_gLW_O 1000;
BA_REL_ "GenSigTimeoutTime" BU_SG_REL_ AFS SG_ 1185 AFS_R_Scheinw_Var_1 1000;
BA_REL_ "GenSigTimeoutTime" BU_SG_REL_ BCM1 SG_ 1185 AFS_R_Scheinw_Var_1 1000;
BA_REL_ "GenSigTimeoutTime" BU_SG_REL_ FCM SG_ 1185 AFS_R_Scheinw_Var_1 1000;
BA_REL_ "GenSigTimeoutTime" BU_SG_REL_ AFS SG_ 1185 AFS_R_Scheinw_Var_2 1000;
BA_REL_ "GenSigTimeoutTime" BU_SG_REL_ BCM1 SG_ 1185 AFS_R_Scheinw_Var_2 1000;
BA_REL_ "GenSigTimeoutTime" BU_SG_REL_ FCM SG_ 1185 AFS_R_Scheinw_Var_2 1000;
BA_REL_ "GenSigTimeoutTime" BU_SG_REL_ AFS_LMod_L SG_ 402 SOA_SollPos_L 500;
BA_REL_ "GenSigTimeoutTime" BU_SG_REL_ GLW_LMod_L SG_ 402 SOA_SollPos_L 500;
BA_REL_ "GenSigTimeoutTime" BU_SG_REL_ LCM_L SG_ 402 SOA_SollPos_L 500;
BA_REL_ "GenSigTimeoutTime" BU_SG_REL_ LLP_L SG_ 402 SOA_SollPos_L 500;
BA_REL_ "GenSigTimeoutTime" BU_SG_REL_ AFS_LMod_L SG_ 402 SOA_FehlPos_L 500;
BA_REL_ "GenSigTimeoutTime" BU_SG_REL_ GLW_LMod_L SG_ 402 SOA_FehlPos_L 500;
BA_REL_ "GenSigTimeoutTime" BU_SG_REL_ LCM_L SG_ 402 SOA_FehlPos_L 500;
BA_REL_ "GenSigTimeoutTime" BU_SG_REL_ LLP_L SG_ 402 SOA_FehlPos_L 500;
BA_REL_ "GenSigTimeoutTime" BU_SG_REL_ AFS_LMod_L SG_ 402 SOA_RefLauf_L 500;
BA_REL_ "GenSigTimeoutTime" BU_SG_REL_ GLW_LMod_L SG_ 402 SOA_RefLauf_L 500;
BA_REL_ "GenSigTimeoutTime" BU_SG_REL_ LCM_L SG_ 402 SOA_RefLauf_L 500;
BA_REL_ "GenSigTimeoutTime" BU_SG_REL_ LLP_L SG_ 402 SOA_RefLauf_L 500;
BA_REL_ "GenSigTimeoutTime" BU_SG_REL_ AFS_LMod_L SG_ 402 SOA_StGlTest_L 500;
BA_REL_ "GenSigTimeoutTime" BU_SG_REL_ GLW_LMod_L SG_ 402 SOA_StGlTest_L 500;
BA_REL_ "GenSigTimeoutTime" BU_SG_REL_ LCM_L SG_ 402 SOA_StGlTest_L 500;
BA_REL_ "GenSigTimeoutTime" BU_SG_REL_ LLP_L SG_ 402 SOA_StGlTest_L 500;
BA_REL_ "GenSigTimeoutTime" BU_SG_REL_ AFS_LMod_L SG_ 402 SOA_StGlDim_L 500;
BA_REL_ "GenSigTimeoutTime" BU_SG_REL_ GLW_LMod_L SG_ 402 SOA_StGlDim_L 500;
BA_REL_ "GenSigTimeoutTime" BU_SG_REL_ LCM_L SG_ 402 SOA_StGlDim_L 500;
BA_REL_ "GenSigTimeoutTime" BU_SG_REL_ LLP_L SG_ 402 SOA_StGlDim_L 500;
BA_REL_ "GenSigTimeoutTime" BU_SG_REL_ AFS_LMod_L SG_ 402 SOA_DimAbLicht_L 500;
BA_REL_ "GenSigTimeoutTime" BU_SG_REL_ GLW_LMod_L SG_ 402 SOA_DimAbLicht_L 500;
BA_REL_ "GenSigTimeoutTime" BU_SG_REL_ LCM_L SG_ 402 SOA_DimAbLicht_L 500;
BA_REL_ "GenSigTimeoutTime" BU_SG_REL_ LLP_L SG_ 402 SOA_DimAbLicht_L 500;
BA_REL_ "GenSigTimeoutTime" BU_SG_REL_ AFS_LMod_R SG_ 402 SOA_SollPos_R 500;
BA_REL_ "GenSigTimeoutTime" BU_SG_REL_ GLW_LMod_R SG_ 402 SOA_SollPos_R 500;
BA_REL_ "GenSigTimeoutTime" BU_SG_REL_ LCM_R SG_ 402 SOA_SollPos_R 500;
BA_REL_ "GenSigTimeoutTime" BU_SG_REL_ LLP_R SG_ 402 SOA_SollPos_R 500;
BA_REL_ "GenSigTimeoutTime" BU_SG_REL_ AFS_LMod_R SG_ 402 SOA_FehlPos_R 500;
BA_REL_ "GenSigTimeoutTime" BU_SG_REL_ GLW_LMod_R SG_ 402 SOA_FehlPos_R 500;
BA_REL_ "GenSigTimeoutTime" BU_SG_REL_ LCM_R SG_ 402 SOA_FehlPos_R 500;
BA_REL_ "GenSigTimeoutTime" BU_SG_REL_ LLP_R SG_ 402 SOA_FehlPos_R 500;
BA_REL_ "GenSigTimeoutTime" BU_SG_REL_ AFS_LMod_R SG_ 402 SOA_RefLauf_R 500;
BA_REL_ "GenSigTimeoutTime" BU_SG_REL_ GLW_LMod_R SG_ 402 SOA_RefLauf_R 500;
BA_REL_ "GenSigTimeoutTime" BU_SG_REL_ LCM_R SG_ 402 SOA_RefLauf_R 500;
BA_REL_ "GenSigTimeoutTime" BU_SG_REL_ LLP_R SG_ 402 SOA_RefLauf_R 500;
BA_REL_ "GenSigTimeoutTime" BU_SG_REL_ AFS_LMod_R SG_ 402 SOA_StGlTest_R 500;
BA_REL_ "GenSigTimeoutTime" BU_SG_REL_ GLW_LMod_R SG_ 402 SOA_StGlTest_R 500;
BA_REL_ "GenSigTimeoutTime" BU_SG_REL_ LCM_R SG_ 402 SOA_StGlTest_R 500;
BA_REL_ "GenSigTimeoutTime" BU_SG_REL_ LLP_R SG_ 402 SOA_StGlTest_R 500;
BA_REL_ "GenSigTimeoutTime" BU_SG_REL_ AFS_LMod_R SG_ 402 SOA_StGlDim_R 500;
BA_REL_ "GenSigTimeoutTime" BU_SG_REL_ GLW_LMod_R SG_ 402 SOA_StGlDim_R 500;
BA_REL_ "GenSigTimeoutTime" BU_SG_REL_ LCM_R SG_ 402 SOA_StGlDim_R 500;
BA_REL_ "GenSigTimeoutTime" BU_SG_REL_ LLP_R SG_ 402 SOA_StGlDim_R 500;
BA_REL_ "GenSigTimeoutTime" BU_SG_REL_ AFS_LMod_R SG_ 402 SOA_DimAbLicht_R 500;
BA_REL_ "GenSigTimeoutTime" BU_SG_REL_ GLW_LMod_R SG_ 402 SOA_DimAbLicht_R 500;
BA_REL_ "GenSigTimeoutTime" BU_SG_REL_ LCM_R SG_ 402 SOA_DimAbLicht_R 500;
BA_REL_ "GenSigTimeoutTime" BU_SG_REL_ LLP_R SG_ 402 SOA_DimAbLicht_R 500;
BA_REL_ "GenSigTimeoutTime" BU_SG_REL_ AFS_LMod_L SG_ 402 SOA_Variante 500;
BA_REL_ "GenSigTimeoutTime" BU_SG_REL_ AFS_LMod_R SG_ 402 SOA_Variante 500;
BA_REL_ "GenSigTimeoutTime" BU_SG_REL_ GLW_LMod_L SG_ 402 SOA_Variante 500;
BA_REL_ "GenSigTimeoutTime" BU_SG_REL_ GLW_LMod_R SG_ 402 SOA_Variante 500;
BA_REL_ "GenSigTimeoutTime" BU_SG_REL_ LCM_L SG_ 402 SOA_Variante 500;
BA_REL_ "GenSigTimeoutTime" BU_SG_REL_ LCM_R SG_ 402 SOA_Variante 500;
BA_REL_ "GenSigTimeoutTime" BU_SG_REL_ LED_DK3_LM_L SG_ 402 SOA_Variante 500;
BA_REL_ "GenSigTimeoutTime" BU_SG_REL_ LED_DK3_LM_R SG_ 402 SOA_Variante 500;
BA_REL_ "GenSigTimeoutTime" BU_SG_REL_ LED_LM_L SG_ 402 SOA_Variante 500;
BA_REL_ "GenSigTimeoutTime" BU_SG_REL_ LED_LM_R SG_ 402 SOA_Variante 500;
BA_REL_ "GenSigTimeoutTime" BU_SG_REL_ LLP_L SG_ 402 SOA_Variante 500;
BA_REL_ "GenSigTimeoutTime" BU_SG_REL_ LLP_R SG_ 402 SOA_Variante 500;
BA_REL_ "GenSigTimeoutTime" BU_SG_REL_ LWR_MXB_L SG_ 402 SOA_Variante 500;
BA_REL_ "GenSigTimeoutTime" BU_SG_REL_ LWR_MXB_R SG_ 402 SOA_Variante 500;
BA_REL_ "GenSigTimeoutTime" BU_SG_REL_ MXB_LM_L SG_ 402 SOA_Variante 500;
BA_REL_ "GenSigTimeoutTime" BU_SG_REL_ MXB_LM_R SG_ 402 SOA_Variante 500;
BA_REL_ "GenSigTimeoutTime" BU_SG_REL_ AFS_LMod_L SG_ 402 SOA_Variante_2 500;
BA_REL_ "GenSigTimeoutTime" BU_SG_REL_ AFS_LMod_R SG_ 402 SOA_Variante_2 500;
BA_REL_ "GenSigTimeoutTime" BU_SG_REL_ GLW_LMod_L SG_ 402 SOA_Variante_2 500;
BA_REL_ "GenSigTimeoutTime" BU_SG_REL_ GLW_LMod_R SG_ 402 SOA_Variante_2 500;
BA_REL_ "GenSigTimeoutTime" BU_SG_REL_ LCM_L SG_ 402 SOA_Variante_2 500;
BA_REL_ "GenSigTimeoutTime" BU_SG_REL_ LCM_R SG_ 402 SOA_Variante_2 500;
BA_REL_ "GenSigTimeoutTime" BU_SG_REL_ LED_DK3_LM_L SG_ 402 SOA_Variante_2 500;
BA_REL_ "GenSigTimeoutTime" BU_SG_REL_ LED_DK3_LM_R SG_ 402 SOA_Variante_2 500;
BA_REL_ "GenSigTimeoutTime" BU_SG_REL_ LED_LM_L SG_ 402 SOA_Variante_2 500;
BA_REL_ "GenSigTimeoutTime" BU_SG_REL_ LED_LM_R SG_ 402 SOA_Variante_2 500;
BA_REL_ "GenSigTimeoutTime" BU_SG_REL_ LLP_L SG_ 402 SOA_Variante_2 500;
BA_REL_ "GenSigTimeoutTime" BU_SG_REL_ LLP_R SG_ 402 SOA_Variante_2 500;
BA_REL_ "GenSigTimeoutTime" BU_SG_REL_ LWR_MXB_L SG_ 402 SOA_Variante_2 500;
BA_REL_ "GenSigTimeoutTime" BU_SG_REL_ LWR_MXB_R SG_ 402 SOA_Variante_2 500;
BA_REL_ "GenSigTimeoutTime" BU_SG_REL_ MXB_LM_L SG_ 402 SOA_Variante_2 500;
BA_REL_ "GenSigTimeoutTime" BU_SG_REL_ MXB_LM_R SG_ 402 SOA_Variante_2 500;
BA_REL_ "GenSigTimeoutTime" BU_SG_REL_ AFS SG_ 410 SAL_IstPos 500;
BA_REL_ "GenSigTimeoutTime" BU_SG_REL_ BCM1 SG_ 410 SAL_IstPos 500;
BA_REL_ "GenSigTimeoutTime" BU_SG_REL_ FCM SG_ 410 SAL_IstPos 500;
BA_REL_ "GenSigTimeoutTime" BU_SG_REL_ AFS SG_ 410 SAL_SchwenkRi 500;
BA_REL_ "GenSigTimeoutTime" BU_SG_REL_ BCM1 SG_ 410 SAL_SchwenkRi 500;
BA_REL_ "GenSigTimeoutTime" BU_SG_REL_ FCM SG_ 410 SAL_SchwenkRi 500;
BA_REL_ "GenSigTimeoutTime" BU_SG_REL_ AFS SG_ 410 SAL_IstPosMot 500;
BA_REL_ "GenSigTimeoutTime" BU_SG_REL_ BCM1 SG_ 410 SAL_IstPosMot 500;
BA_REL_ "GenSigTimeoutTime" BU_SG_REL_ FCM SG_ 410 SAL_IstPosMot 500;
BA_REL_ "GenSigTimeoutTime" BU_SG_REL_ AFS SG_ 410 SAL_StaVerst 500;
BA_REL_ "GenSigTimeoutTime" BU_SG_REL_ BCM1 SG_ 410 SAL_StaVerst 500;
BA_REL_ "GenSigTimeoutTime" BU_SG_REL_ FCM SG_ 410 SAL_StaVerst 500;
BA_REL_ "GenSigTimeoutTime" BU_SG_REL_ AFS SG_ 410 SAL_StaFehPos 500;
BA_REL_ "GenSigTimeoutTime" BU_SG_REL_ BCM1 SG_ 410 SAL_StaFehPos 500;
BA_REL_ "GenSigTimeoutTime" BU_SG_REL_ FCM SG_ 410 SAL_StaFehPos 500;
BA_REL_ "GenSigTimeoutTime" BU_SG_REL_ AFS SG_ 410 SAL_StaReflauf 500;
BA_REL_ "GenSigTimeoutTime" BU_SG_REL_ BCM1 SG_ 410 SAL_StaReflauf 500;
BA_REL_ "GenSigTimeoutTime" BU_SG_REL_ FCM SG_ 410 SAL_StaReflauf 500;
BA_REL_ "GenSigTimeoutTime" BU_SG_REL_ AFS SG_ 410 SAL_StaStGlTst 500;
BA_REL_ "GenSigTimeoutTime" BU_SG_REL_ BCM1 SG_ 410 SAL_StaStGlTst 500;
BA_REL_ "GenSigTimeoutTime" BU_SG_REL_ FCM SG_ 410 SAL_StaStGlTst 500;
BA_REL_ "GenSigTimeoutTime" BU_SG_REL_ AFS SG_ 410 SAL_StaAbLicht 500;
BA_REL_ "GenSigTimeoutTime" BU_SG_REL_ BCM1 SG_ 410 SAL_StaAbLicht 500;
BA_REL_ "GenSigTimeoutTime" BU_SG_REL_ FCM SG_ 410 SAL_StaAbLicht 500;
BA_REL_ "GenSigTimeoutTime" BU_SG_REL_ AFS SG_ 410 SAL_IstDimAbLi 500;
BA_REL_ "GenSigTimeoutTime" BU_SG_REL_ BCM1 SG_ 410 SAL_IstDimAbLi 500;
BA_REL_ "GenSigTimeoutTime" BU_SG_REL_ FCM SG_ 410 SAL_IstDimAbLi 500;
BA_REL_ "GenSigTimeoutTime" BU_SG_REL_ AFS SG_ 410 SAL_VSpg_AFS 500;
BA_REL_ "GenSigTimeoutTime" BU_SG_REL_ BCM1 SG_ 410 SAL_VSpg_AFS 500;
BA_REL_ "GenSigTimeoutTime" BU_SG_REL_ FCM SG_ 410 SAL_VSpg_AFS 500;
BA_REL_ "GenSigTimeoutTime" BU_SG_REL_ AFS SG_ 412 SAR_IstPos 500;
BA_REL_ "GenSigTimeoutTime" BU_SG_REL_ BCM1 SG_ 412 SAR_IstPos 500;
BA_REL_ "GenSigTimeoutTime" BU_SG_REL_ FCM SG_ 412 SAR_IstPos 500;
BA_REL_ "GenSigTimeoutTime" BU_SG_REL_ AFS SG_ 412 SAR_SchwenkRi 500;
BA_REL_ "GenSigTimeoutTime" BU_SG_REL_ BCM1 SG_ 412 SAR_SchwenkRi 500;
BA_REL_ "GenSigTimeoutTime" BU_SG_REL_ FCM SG_ 412 SAR_SchwenkRi 500;
BA_REL_ "GenSigTimeoutTime" BU_SG_REL_ AFS SG_ 412 SAR_IstPosMot 500;
BA_REL_ "GenSigTimeoutTime" BU_SG_REL_ BCM1 SG_ 412 SAR_IstPosMot 500;
BA_REL_ "GenSigTimeoutTime" BU_SG_REL_ FCM SG_ 412 SAR_IstPosMot 500;
BA_REL_ "GenSigTimeoutTime" BU_SG_REL_ AFS SG_ 412 SAR_StaVerst 500;
BA_REL_ "GenSigTimeoutTime" BU_SG_REL_ BCM1 SG_ 412 SAR_StaVerst 500;
BA_REL_ "GenSigTimeoutTime" BU_SG_REL_ FCM SG_ 412 SAR_StaVerst 500;
BA_REL_ "GenSigTimeoutTime" BU_SG_REL_ AFS SG_ 412 SAR_StaFehPos 500;
BA_REL_ "GenSigTimeoutTime" BU_SG_REL_ BCM1 SG_ 412 SAR_StaFehPos 500;
BA_REL_ "GenSigTimeoutTime" BU_SG_REL_ FCM SG_ 412 SAR_StaFehPos 500;
BA_REL_ "GenSigTimeoutTime" BU_SG_REL_ AFS SG_ 412 SAR_StaReflauf 500;
BA_REL_ "GenSigTimeoutTime" BU_SG_REL_ BCM1 SG_ 412 SAR_StaReflauf 500;
BA_REL_ "GenSigTimeoutTime" BU_SG_REL_ FCM SG_ 412 SAR_StaReflauf 500;
BA_REL_ "GenSigTimeoutTime" BU_SG_REL_ AFS SG_ 412 SAR_StaStGlTst 500;
BA_REL_ "GenSigTimeoutTime" BU_SG_REL_ BCM1 SG_ 412 SAR_StaStGlTst 500;
BA_REL_ "GenSigTimeoutTime" BU_SG_REL_ FCM SG_ 412 SAR_StaStGlTst 500;
BA_REL_ "GenSigTimeoutTime" BU_SG_REL_ AFS SG_ 412 SAR_StaAbLicht 500;
BA_REL_ "GenSigTimeoutTime" BU_SG_REL_ BCM1 SG_ 412 SAR_StaAbLicht 500;
BA_REL_ "GenSigTimeoutTime" BU_SG_REL_ FCM SG_ 412 SAR_StaAbLicht 500;
BA_REL_ "GenSigTimeoutTime" BU_SG_REL_ AFS SG_ 412 SAR_IstDimAbRe 500;
BA_REL_ "GenSigTimeoutTime" BU_SG_REL_ BCM1 SG_ 412 SAR_IstDimAbRe 500;
BA_REL_ "GenSigTimeoutTime" BU_SG_REL_ FCM SG_ 412 SAR_IstDimAbRe 500;
BA_REL_ "GenSigTimeoutTime" BU_SG_REL_ AFS SG_ 412 SAR_VSpg_AFS 500;
BA_REL_ "GenSigTimeoutTime" BU_SG_REL_ BCM1 SG_ 412 SAR_VSpg_AFS 500;
BA_REL_ "GenSigTimeoutTime" BU_SG_REL_ FCM SG_ 412 SAR_VSpg_AFS 500;
BA_REL_ "GenSigTimeoutTime" BU_SG_REL_ LED_DK3_LM_L SG_ 64 Airbag_01_CRC 500;
BA_REL_ "GenSigTimeoutTime" BU_SG_REL_ LED_DK3_LM_R SG_ 64 Airbag_01_CRC 500;
BA_REL_ "GenSigTimeoutTime" BU_SG_REL_ LLP_L SG_ 64 Airbag_01_CRC 500;
BA_REL_ "GenSigTimeoutTime" BU_SG_REL_ LLP_R SG_ 64 Airbag_01_CRC 500;
BA_REL_ "GenSigTimeoutTime" BU_SG_REL_ LED_DK3_LM_L SG_ 64 Airbag_01_BZ 500;
BA_REL_ "GenSigTimeoutTime" BU_SG_REL_ LED_DK3_LM_R SG_ 64 Airbag_01_BZ 500;
BA_REL_ "GenSigTimeoutTime" BU_SG_REL_ LLP_L SG_ 64 Airbag_01_BZ 500;
BA_REL_ "GenSigTimeoutTime" BU_SG_REL_ LLP_R SG_ 64 Airbag_01_BZ 500;
BA_REL_ "GenSigTimeoutTime" BU_SG_REL_ LED_DK3_LM_L SG_ 64 AB_Front_Crash 500;
BA_REL_ "GenSigTimeoutTime" BU_SG_REL_ LED_DK3_LM_R SG_ 64 AB_Front_Crash 500;
BA_REL_ "GenSigTimeoutTime" BU_SG_REL_ LLP_L SG_ 64 AB_Front_Crash 500;
BA_REL_ "GenSigTimeoutTime" BU_SG_REL_ LLP_R SG_ 64 AB_Front_Crash 500;
BA_REL_ "GenSigTimeoutTime" BU_SG_REL_ LED_DK3_LM_L SG_ 64 AB_Crash_Int 500;
BA_REL_ "GenSigTimeoutTime" BU_SG_REL_ LED_DK3_LM_R SG_ 64 AB_Crash_Int 500;
BA_REL_ "GenSigTimeoutTime" BU_SG_REL_ LLP_L SG_ 64 AB_Crash_Int 500;
BA_REL_ "GenSigTimeoutTime" BU_SG_REL_ LLP_R SG_ 64 AB_Crash_Int 500;
BA_REL_ "GenSigTimeoutTime" BU_SG_REL_ LED_DK3_LM_L SG_ 64 AB_Diagnose 500;
BA_REL_ "GenSigTimeoutTime" BU_SG_REL_ LED_DK3_LM_R SG_ 64 AB_Diagnose 500;
BA_REL_ "GenSigTimeoutTime" BU_SG_REL_ LLP_L SG_ 64 AB_Diagnose 500;
BA_REL_ "GenSigTimeoutTime" BU_SG_REL_ LLP_R SG_ 64 AB_Diagnose 500;
BA_REL_ "GenSigTimeoutTime" BU_SG_REL_ LED_DK3_LM_L SG_ 64 AB_Stellgliedtest 500;
BA_REL_ "GenSigTimeoutTime" BU_SG_REL_ LED_DK3_LM_R SG_ 64 AB_Stellgliedtest 500;
BA_REL_ "GenSigTimeoutTime" BU_SG_REL_ LLP_L SG_ 64 AB_Stellgliedtest 500;
BA_REL_ "GenSigTimeoutTime" BU_SG_REL_ LLP_R SG_ 64 AB_Stellgliedtest 500;
BA_REL_ "GenSigTimeoutTime" BU_SG_REL_ LED_DK3_LM_L SG_ 64 AB_Erh_Auf_VB 500;
BA_REL_ "GenSigTimeoutTime" BU_SG_REL_ LED_DK3_LM_R SG_ 64 AB_Erh_Auf_VB 500;
BA_REL_ "GenSigTimeoutTime" BU_SG_REL_ LLP_L SG_ 64 AB_Erh_Auf_VB 500;
BA_REL_ "GenSigTimeoutTime" BU_SG_REL_ LLP_R SG_ 64 AB_Erh_Auf_VB 500;
BA_REL_ "GenSigTimeoutTime" BU_SG_REL_ BCM1 SG_ 821 SOA_Offset_L 500;
BA_REL_ "GenSigTimeoutTime" BU_SG_REL_ BCM1 SG_ 821 SOA_Offset_R 500;
BA_REL_ "GenSigTimeoutTime" BU_SG_REL_ BCM1 SG_ 821 SOL_Offset_L 500;
BA_REL_ "GenSigTimeoutTime" BU_SG_REL_ BCM1 SG_ 821 SOL_Offset_R 500;
BA_REL_ "GenSigTimeoutTime" BU_SG_REL_ LCM_L SG_ 1714 DGN_Verlernzaehler 5000;
BA_REL_ "GenSigTimeoutTime" BU_SG_REL_ LCM_R SG_ 1714 DGN_Verlernzaehler 5000;
BA_REL_ "GenSigTimeoutTime" BU_SG_REL_ LED_DK3_LM_L SG_ 1714 DGN_Verlernzaehler 5000;
BA_REL_ "GenSigTimeoutTime" BU_SG_REL_ LED_DK3_LM_R SG_ 1714 DGN_Verlernzaehler 5000;
BA_REL_ "GenSigTimeoutTime" BU_SG_REL_ LLP_L SG_ 1714 DGN_Verlernzaehler 5000;
BA_REL_ "GenSigTimeoutTime" BU_SG_REL_ LLP_R SG_ 1714 DGN_Verlernzaehler 5000;
BA_REL_ "GenSigTimeoutTime" BU_SG_REL_ LCM_L SG_ 1714 KBI_Kilometerstand 5000;
BA_REL_ "GenSigTimeoutTime" BU_SG_REL_ LCM_R SG_ 1714 KBI_Kilometerstand 5000;
BA_REL_ "GenSigTimeoutTime" BU_SG_REL_ LED_DK3_LM_L SG_ 1714 KBI_Kilometerstand 5000;
BA_REL_ "GenSigTimeoutTime" BU_SG_REL_ LED_DK3_LM_R SG_ 1714 KBI_Kilometerstand 5000;
BA_REL_ "GenSigTimeoutTime" BU_SG_REL_ LLP_L SG_ 1714 KBI_Kilometerstand 5000;
BA_REL_ "GenSigTimeoutTime" BU_SG_REL_ LLP_R SG_ 1714 KBI_Kilometerstand 5000;
BA_REL_ "GenSigTimeoutTime" BU_SG_REL_ LCM_L SG_ 1714 UH_Jahr 5000;
BA_REL_ "GenSigTimeoutTime" BU_SG_REL_ LCM_R SG_ 1714 UH_Jahr 5000;
BA_REL_ "GenSigTimeoutTime" BU_SG_REL_ LED_DK3_LM_L SG_ 1714 UH_Jahr 5000;
BA_REL_ "GenSigTimeoutTime" BU_SG_REL_ LED_DK3_LM_R SG_ 1714 UH_Jahr 5000;
BA_REL_ "GenSigTimeoutTime" BU_SG_REL_ LLP_L SG_ 1714 UH_Jahr 5000;
BA_REL_ "GenSigTimeoutTime" BU_SG_REL_ LLP_R SG_ 1714 UH_Jahr 5000;
BA_REL_ "GenSigTimeoutTime" BU_SG_REL_ LCM_L SG_ 1714 UH_Monat 5000;
BA_REL_ "GenSigTimeoutTime" BU_SG_REL_ LCM_R SG_ 1714 UH_Monat 5000;
BA_REL_ "GenSigTimeoutTime" BU_SG_REL_ LED_DK3_LM_L SG_ 1714 UH_Monat 5000;
BA_REL_ "GenSigTimeoutTime" BU_SG_REL_ LED_DK3_LM_R SG_ 1714 UH_Monat 5000;
BA_REL_ "GenSigTimeoutTime" BU_SG_REL_ LLP_L SG_ 1714 UH_Monat 5000;
BA_REL_ "GenSigTimeoutTime" BU_SG_REL_ LLP_R SG_ 1714 UH_Monat 5000;
BA_REL_ "GenSigTimeoutTime" BU_SG_REL_ LCM_L SG_ 1714 UH_Tag 5000;
BA_REL_ "GenSigTimeoutTime" BU_SG_REL_ LCM_R SG_ 1714 UH_Tag 5000;
BA_REL_ "GenSigTimeoutTime" BU_SG_REL_ LED_DK3_LM_L SG_ 1714 UH_Tag 5000;
BA_REL_ "GenSigTimeoutTime" BU_SG_REL_ LED_DK3_LM_R SG_ 1714 UH_Tag 5000;
BA_REL_ "GenSigTimeoutTime" BU_SG_REL_ LLP_L SG_ 1714 UH_Tag 5000;
BA_REL_ "GenSigTimeoutTime" BU_SG_REL_ LLP_R SG_ 1714 UH_Tag 5000;
BA_REL_ "GenSigTimeoutTime" BU_SG_REL_ LCM_L SG_ 1714 UH_Stunde 5000;
BA_REL_ "GenSigTimeoutTime" BU_SG_REL_ LCM_R SG_ 1714 UH_Stunde 5000;
BA_REL_ "GenSigTimeoutTime" BU_SG_REL_ LED_DK3_LM_L SG_ 1714 UH_Stunde 5000;
BA_REL_ "GenSigTimeoutTime" BU_SG_REL_ LED_DK3_LM_R SG_ 1714 UH_Stunde 5000;
BA_REL_ "GenSigTimeoutTime" BU_SG_REL_ LLP_L SG_ 1714 UH_Stunde 5000;
BA_REL_ "GenSigTimeoutTime" BU_SG_REL_ LLP_R SG_ 1714 UH_Stunde 5000;
BA_REL_ "GenSigTimeoutTime" BU_SG_REL_ LCM_L SG_ 1714 UH_Minute 5000;
BA_REL_ "GenSigTimeoutTime" BU_SG_REL_ LCM_R SG_ 1714 UH_Minute 5000;
BA_REL_ "GenSigTimeoutTime" BU_SG_REL_ LED_DK3_LM_L SG_ 1714 UH_Minute 5000;
BA_REL_ "GenSigTimeoutTime" BU_SG_REL_ LED_DK3_LM_R SG_ 1714 UH_Minute 5000;
BA_REL_ "GenSigTimeoutTime" BU_SG_REL_ LLP_L SG_ 1714 UH_Minute 5000;
BA_REL_ "GenSigTimeoutTime" BU_SG_REL_ LLP_R SG_ 1714 UH_Minute 5000;
BA_REL_ "GenSigTimeoutTime" BU_SG_REL_ LCM_L SG_ 1714 UH_Sekunde 5000;
BA_REL_ "GenSigTimeoutTime" BU_SG_REL_ LCM_R SG_ 1714 UH_Sekunde 5000;
BA_REL_ "GenSigTimeoutTime" BU_SG_REL_ LED_DK3_LM_L SG_ 1714 UH_Sekunde 5000;
BA_REL_ "GenSigTimeoutTime" BU_SG_REL_ LED_DK3_LM_R SG_ 1714 UH_Sekunde 5000;
BA_REL_ "GenSigTimeoutTime" BU_SG_REL_ LLP_L SG_ 1714 UH_Sekunde 5000;
BA_REL_ "GenSigTimeoutTime" BU_SG_REL_ LLP_R SG_ 1714 UH_Sekunde 5000;
BA_REL_ "GenSigTimeoutTime" BU_SG_REL_ LED_DK3_LM_L SG_ 253 ESP_21_CRC 500;
BA_REL_ "GenSigTimeoutTime" BU_SG_REL_ LED_DK3_LM_R SG_ 253 ESP_21_CRC 500;
BA_REL_ "GenSigTimeoutTime" BU_SG_REL_ LLP_L SG_ 253 ESP_21_CRC 500;
BA_REL_ "GenSigTimeoutTime" BU_SG_REL_ LLP_R SG_ 253 ESP_21_CRC 500;
BA_REL_ "GenSigTimeoutTime" BU_SG_REL_ LED_DK3_LM_L SG_ 253 ESP_21_BZ 500;
BA_REL_ "GenSigTimeoutTime" BU_SG_REL_ LED_DK3_LM_R SG_ 253 ESP_21_BZ 500;
BA_REL_ "GenSigTimeoutTime" BU_SG_REL_ LLP_L SG_ 253 ESP_21_BZ 500;
BA_REL_ "GenSigTimeoutTime" BU_SG_REL_ LLP_R SG_ 253 ESP_21_BZ 500;
BA_REL_ "GenSigTimeoutTime" BU_SG_REL_ LED_DK3_LM_L SG_ 253 ESC_v_Signal_Qualifier_High_Low 500;
BA_REL_ "GenSigTimeoutTime" BU_SG_REL_ LED_DK3_LM_R SG_ 253 ESC_v_Signal_Qualifier_High_Low 500;
BA_REL_ "GenSigTimeoutTime" BU_SG_REL_ LLP_L SG_ 253 ESC_v_Signal_Qualifier_High_Low 500;
BA_REL_ "GenSigTimeoutTime" BU_SG_REL_ LLP_R SG_ 253 ESC_v_Signal_Qualifier_High_Low 500;
BA_REL_ "GenSigTimeoutTime" BU_SG_REL_ LCM_L SG_ 253 ESP_v_Signal 500;
BA_REL_ "GenSigTimeoutTime" BU_SG_REL_ LCM_R SG_ 253 ESP_v_Signal 500;
BA_REL_ "GenSigTimeoutTime" BU_SG_REL_ LED_DK3_LM_L SG_ 253 ESP_v_Signal 500;
BA_REL_ "GenSigTimeoutTime" BU_SG_REL_ LED_DK3_LM_R SG_ 253 ESP_v_Signal 500;
BA_REL_ "GenSigTimeoutTime" BU_SG_REL_ LLP_L SG_ 253 ESP_v_Signal 500;
BA_REL_ "GenSigTimeoutTime" BU_SG_REL_ LLP_R SG_ 253 ESP_v_Signal 500;
BA_REL_ "GenSigTimeoutTime" BU_SG_REL_ AFS SG_ 918 FGL_Akt_KS_Plus 1000;
BA_REL_ "GenSigTimeoutTime" BU_SG_REL_ BCM1 SG_ 918 FGL_Akt_KS_Plus 1000;
BA_REL_ "GenSigTimeoutTime" BU_SG_REL_ FCM SG_ 918 FGL_Akt_KS_Plus 1000;
BA_REL_ "GenSigTimeoutTime" BU_SG_REL_ AFS SG_ 918 FGL_RAkt_KS_Plus 1000;
BA_REL_ "GenSigTimeoutTime" BU_SG_REL_ BCM1 SG_ 918 FGL_RAkt_KS_Plus 1000;
BA_REL_ "GenSigTimeoutTime" BU_SG_REL_ FCM SG_ 918 FGL_RAkt_KS_Plus 1000;
BA_REL_ "GenSigTimeoutTime" BU_SG_REL_ AFS SG_ 918 FGL_Akt_KS_Gnd 1000;
BA_REL_ "GenSigTimeoutTime" BU_SG_REL_ BCM1 SG_ 918 FGL_Akt_KS_Gnd 1000;
BA_REL_ "GenSigTimeoutTime" BU_SG_REL_ FCM SG_ 918 FGL_Akt_KS_Gnd 1000;
BA_REL_ "GenSigTimeoutTime" BU_SG_REL_ AFS SG_ 918 FGL_RAkt_KS_Gnd 1000;
BA_REL_ "GenSigTimeoutTime" BU_SG_REL_ BCM1 SG_ 918 FGL_RAkt_KS_Gnd 1000;
BA_REL_ "GenSigTimeoutTime" BU_SG_REL_ FCM SG_ 918 FGL_RAkt_KS_Gnd 1000;
BA_REL_ "GenSigTimeoutTime" BU_SG_REL_ AFS SG_ 918 FGL_Akt_OL 1000;
BA_REL_ "GenSigTimeoutTime" BU_SG_REL_ BCM1 SG_ 918 FGL_Akt_OL 1000;
BA_REL_ "GenSigTimeoutTime" BU_SG_REL_ FCM SG_ 918 FGL_Akt_OL 1000;
BA_REL_ "GenSigTimeoutTime" BU_SG_REL_ AFS SG_ 918 FGL_RAkt_OL 1000;
BA_REL_ "GenSigTimeoutTime" BU_SG_REL_ BCM1 SG_ 918 FGL_RAkt_OL 1000;
BA_REL_ "GenSigTimeoutTime" BU_SG_REL_ FCM SG_ 918 FGL_RAkt_OL 1000;
BA_REL_ "GenSigTimeoutTime" BU_SG_REL_ AFS SG_ 918 FGL_Akt_UeSpg 1000;
BA_REL_ "GenSigTimeoutTime" BU_SG_REL_ BCM1 SG_ 918 FGL_Akt_UeSpg 1000;
BA_REL_ "GenSigTimeoutTime" BU_SG_REL_ FCM SG_ 918 FGL_Akt_UeSpg 1000;
BA_REL_ "GenSigTimeoutTime" BU_SG_REL_ AFS SG_ 918 FGL_RAkt_UeSpg 1000;
BA_REL_ "GenSigTimeoutTime" BU_SG_REL_ BCM1 SG_ 918 FGL_RAkt_UeSpg 1000;
BA_REL_ "GenSigTimeoutTime" BU_SG_REL_ FCM SG_ 918 FGL_RAkt_UeSpg 1000;
BA_REL_ "GenSigTimeoutTime" BU_SG_REL_ AFS SG_ 918 FGL_Akt_USpg 1000;
BA_REL_ "GenSigTimeoutTime" BU_SG_REL_ BCM1 SG_ 918 FGL_Akt_USpg 1000;
BA_REL_ "GenSigTimeoutTime" BU_SG_REL_ FCM SG_ 918 FGL_Akt_USpg 1000;
BA_REL_ "GenSigTimeoutTime" BU_SG_REL_ AFS SG_ 918 FGL_RAkt_USpg 1000;
BA_REL_ "GenSigTimeoutTime" BU_SG_REL_ BCM1 SG_ 918 FGL_RAkt_USpg 1000;
BA_REL_ "GenSigTimeoutTime" BU_SG_REL_ FCM SG_ 918 FGL_RAkt_USpg 1000;
BA_REL_ "GenSigTimeoutTime" BU_SG_REL_ AFS SG_ 918 FGL_Akt_UeTemp 1000;
BA_REL_ "GenSigTimeoutTime" BU_SG_REL_ BCM1 SG_ 918 FGL_Akt_UeTemp 1000;
BA_REL_ "GenSigTimeoutTime" BU_SG_REL_ FCM SG_ 918 FGL_Akt_UeTemp 1000;
BA_REL_ "GenSigTimeoutTime" BU_SG_REL_ AFS SG_ 918 FGL_RAkt_UeTemp 1000;
BA_REL_ "GenSigTimeoutTime" BU_SG_REL_ BCM1 SG_ 918 FGL_RAkt_UeTemp 1000;
BA_REL_ "GenSigTimeoutTime" BU_SG_REL_ FCM SG_ 918 FGL_RAkt_UeTemp 1000;
BA_REL_ "GenSigTimeoutTime" BU_SG_REL_ AFS SG_ 918 FGL_Akt_TempPre 1000;
BA_REL_ "GenSigTimeoutTime" BU_SG_REL_ BCM1 SG_ 918 FGL_Akt_TempPre 1000;
BA_REL_ "GenSigTimeoutTime" BU_SG_REL_ FCM SG_ 918 FGL_Akt_TempPre 1000;
BA_REL_ "GenSigTimeoutTime" BU_SG_REL_ AFS SG_ 918 FGL_RAkt_TempPre 1000;
BA_REL_ "GenSigTimeoutTime" BU_SG_REL_ BCM1 SG_ 918 FGL_RAkt_TempPre 1000;
BA_REL_ "GenSigTimeoutTime" BU_SG_REL_ FCM SG_ 918 FGL_RAkt_TempPre 1000;
BA_REL_ "GenSigTimeoutTime" BU_SG_REL_ AFS SG_ 918 FGL_HS_KS_Plus 1000;
BA_REL_ "GenSigTimeoutTime" BU_SG_REL_ BCM1 SG_ 918 FGL_HS_KS_Plus 1000;
BA_REL_ "GenSigTimeoutTime" BU_SG_REL_ FCM SG_ 918 FGL_HS_KS_Plus 1000;
BA_REL_ "GenSigTimeoutTime" BU_SG_REL_ AFS SG_ 918 FGL_RHS_KS_Plus 1000;
BA_REL_ "GenSigTimeoutTime" BU_SG_REL_ BCM1 SG_ 918 FGL_RHS_KS_Plus 1000;
BA_REL_ "GenSigTimeoutTime" BU_SG_REL_ FCM SG_ 918 FGL_RHS_KS_Plus 1000;
BA_REL_ "GenSigTimeoutTime" BU_SG_REL_ AFS SG_ 918 FGL_HS_KS_Gnd 1000;
BA_REL_ "GenSigTimeoutTime" BU_SG_REL_ BCM1 SG_ 918 FGL_HS_KS_Gnd 1000;
BA_REL_ "GenSigTimeoutTime" BU_SG_REL_ FCM SG_ 918 FGL_HS_KS_Gnd 1000;
BA_REL_ "GenSigTimeoutTime" BU_SG_REL_ AFS SG_ 918 FGL_RHS_KS_Gnd 1000;
BA_REL_ "GenSigTimeoutTime" BU_SG_REL_ BCM1 SG_ 918 FGL_RHS_KS_Gnd 1000;
BA_REL_ "GenSigTimeoutTime" BU_SG_REL_ FCM SG_ 918 FGL_RHS_KS_Gnd 1000;
BA_REL_ "GenSigTimeoutTime" BU_SG_REL_ AFS SG_ 918 FGL_HS_unplSign 1000;
BA_REL_ "GenSigTimeoutTime" BU_SG_REL_ BCM1 SG_ 918 FGL_HS_unplSign 1000;
BA_REL_ "GenSigTimeoutTime" BU_SG_REL_ FCM SG_ 918 FGL_HS_unplSign 1000;
BA_REL_ "GenSigTimeoutTime" BU_SG_REL_ AFS SG_ 918 FGL_RHS_unplSign 1000;
BA_REL_ "GenSigTimeoutTime" BU_SG_REL_ BCM1 SG_ 918 FGL_RHS_unplSign 1000;
BA_REL_ "GenSigTimeoutTime" BU_SG_REL_ FCM SG_ 918 FGL_RHS_unplSign 1000;
BA_REL_ "GenSigTimeoutTime" BU_SG_REL_ AFS SG_ 918 FGL_LIN_Def 1000;
BA_REL_ "GenSigTimeoutTime" BU_SG_REL_ BCM1 SG_ 918 FGL_LIN_Def 1000;
BA_REL_ "GenSigTimeoutTime" BU_SG_REL_ FCM SG_ 918 FGL_LIN_Def 1000;
BA_REL_ "GenSigTimeoutTime" BU_SG_REL_ AFS SG_ 918 FGL_LIN_Timeout 1000;
BA_REL_ "GenSigTimeoutTime" BU_SG_REL_ BCM1 SG_ 918 FGL_LIN_Timeout 1000;
BA_REL_ "GenSigTimeoutTime" BU_SG_REL_ FCM SG_ 918 FGL_LIN_Timeout 1000;
BA_REL_ "GenSigTimeoutTime" BU_SG_REL_ AFS SG_ 918 FGL_RLIN_Def 1000;
BA_REL_ "GenSigTimeoutTime" BU_SG_REL_ BCM1 SG_ 918 FGL_RLIN_Def 1000;
BA_REL_ "GenSigTimeoutTime" BU_SG_REL_ FCM SG_ 918 FGL_RLIN_Def 1000;
BA_REL_ "GenSigTimeoutTime" BU_SG_REL_ AFS SG_ 918 FGL_RLIN_Timeout 1000;
BA_REL_ "GenSigTimeoutTime" BU_SG_REL_ BCM1 SG_ 918 FGL_RLIN_Timeout 1000;
BA_REL_ "GenSigTimeoutTime" BU_SG_REL_ FCM SG_ 918 FGL_RLIN_Timeout 1000;
VAL_ 2600468649 NM_FCM_Car_Wakeup 0 "keine_ABS_Regelung" 1 "ABS_Regelung_aktiv" ;
VAL_ 924 FAL_SchMot 0 "kein_Fehler" 1 "Fehler" ;
VAL_ 924 FAL_RSchMot 0 "Fehlermoeglichkeit_geprueft" 1 "Fehlermoeglichkeit_nicht_geprueft" ;
VAL_ 924 FAL_SM_KS_Gnd 0 "kein_Fehler" 1 "Fehler" ;
VAL_ 924 FAL_RSM_KS_Gnd 0 "Fehlermoeglichkeit_geprueft" 1 "Fehlermoeglichkeit_nicht_geprueft" ;
VAL_ 924 FAL_SM_UeSpg 0 "kein_Fehler" 1 "Fehler" ;
VAL_ 924 FAL_RSM_UeSpg 0 "Fehlermoeglichkeit_geprueft" 1 "Fehlermoeglichkeit_nicht_geprueft" ;
VAL_ 924 FAL_SM_USpg 0 "kein_Fehler" 1 "Fehler" ;
VAL_ 924 FAL_RSM_USpg 0 "Fehlermoeglichkeit_geprueft" 1 "Fehlermoeglichkeit_nicht_geprueft" ;
VAL_ 924 FAL_SM_UeTemp 0 "kein_Fehler" 1 "Fehler" ;
VAL_ 924 FAL_RSM_UeTemp 0 "Fehlermoeglichkeit_geprueft" 1 "Fehlermoeglichkeit_nicht_geprueft" ;
VAL_ 924 FAL_SM_TempPre 0 "kein_Fehler" 1 "Temp_Pre_Alarm" ;
VAL_ 924 FAL_RSM_TempPre 0 "Fehlermoeglichkeit_geprueft" 1 "Fehlermoeglichkeit_nicht_geprueft" ;
VAL_ 924 FAL_EM_UeSpg 0 "kein_Fehler" 1 "Fehler" ;
VAL_ 924 FAL_REM_UeSpg 0 "Fehlermoeglichkeit_geprueft" 1 "Fehlermoeglichkeit_nicht_geprueft" ;
VAL_ 924 FAL_EM_USpg 0 "kein_Fehler" 1 "Fehler" ;
VAL_ 924 FAL_REM_USpg 0 "Fehlermoeglichkeit_geprueft" 1 "Fehlermoeglichkeit_nicht_geprueft" ;
VAL_ 924 FAL_EM_defekt 0 "kein_Fehler" 1 "Fehler" ;
VAL_ 924 FAL_REM_defekt 0 "Fehlermoeglichkeit_geprueft" 1 "Fehlermoeglichkeit_nicht_geprueft" ;
VAL_ 924 FAL_sKL_Lampe 0 "kein_Fehler" 1 "Fehler" ;
VAL_ 924 FAL_RsKL_Lampe 0 "Fehlermoeglichkeit_geprueft" 1 "Fehlermoeglichkeit_nicht_geprueft" ;
VAL_ 924 FAL_sKL_KS_Gnd 0 "kein_Fehler" 1 "Fehler" ;
VAL_ 924 FAL_RsKL_KS_Gnd 0 "Fehlermoeglichkeit_geprueft" 1 "Fehlermoeglichkeit_nicht_geprueft" ;
VAL_ 924 FAL_GDL_Modul 0 "kein_Fehler" 1 "Fehler" ;
VAL_ 924 FAL_RGDL_Modul 0 "Fehlermoeglichkeit_geprueft" 1 "Fehlermoeglichkeit_nicht_geprueft" ;
VAL_ 924 FAL_dKL_KS_Plus 0 "kein_Fehler" 1 "Fehler" ;
VAL_ 924 FAL_RdKL_KS_Plus 0 "Fehlermoeglichkeit_geprueft" 1 "Fehlermoeglichkeit_nicht_geprueft" ;
VAL_ 924 FAL_dKL_KS_Gnd 0 "kein_Fehler" 1 "Fehler" ;
VAL_ 924 FAL_RdKL_KS_Gnd 0 "Fehlermoeglichkeit_geprueft" 1 "Fehlermoeglichkeit_nicht_geprueft" ;
VAL_ 924 FAL_dKL_unplSign 0 "kein_Fehler" 1 "Fehler" ;
VAL_ 924 FAL_RdKL_unplSign 0 "Fehlermoeglichkeit_geprueft" 1 "Fehlermoeglichkeit_nicht_geprueft" ;
VAL_ 924 FAL_5VdKL_KS_Gnd 0 "kein_Fehler" 1 "Fehler" ;
VAL_ 924 FAL_R5VdKL_KS_Gnd 0 "Fehlermoeglichkeit_geprueft" 1 "Fehlermoeglichkeit_nicht_geprueft" ;
VAL_ 924 FAL_5VdKL_KS_UB 0 "kein_Fehler" 1 "Fehler" ;
VAL_ 924 FAL_R5VdKL_KS_UB 0 "Fehlermoeglichkeit_geprueft" 1 "Fehlermoeglichkeit_nicht_geprueft" ;
VAL_ 926 FAR_SchMot 0 "kein_Fehler" 1 "Fehler" ;
VAL_ 926 FAR_RSchMot 0 "Fehlermoeglichkeit_geprueft" 1 "Fehlermoeglichkeit_nicht_geprueft" ;
VAL_ 926 FAR_SM_KS_Gnd 0 "kein_Fehler" 1 "Fehler" ;
VAL_ 926 FAR_RSM_KS_Gnd 0 "Fehlermoeglichkeit_geprueft" 1 "Fehlermoeglichkeit_nicht_geprueft" ;
VAL_ 926 FAR_SM_UeSpg 0 "kein_Fehler" 1 "Fehler" ;
VAL_ 926 FAR_RSM_UeSpg 0 "Fehlermoeglichkeit_geprueft" 1 "Fehlermoeglichkeit_nicht_geprueft" ;
VAL_ 926 FAR_SM_USpg 0 "kein_Fehler" 1 "Fehler" ;
VAL_ 926 FAR_RSM_USpg 0 "Fehlermoeglichkeit_geprueft" 1 "Fehlermoeglichkeit_nicht_geprueft" ;
VAL_ 926 FAR_SM_UeTemp 0 "kein_Fehler" 1 "Fehler" ;
VAL_ 926 FAR_RSM_UeTemp 0 "Fehlermoeglichkeit_geprueft" 1 "Fehlermoeglichkeit_nicht_geprueft" ;
VAL_ 926 FAR_SM_TempPre 0 "kein_Fehler" 1 "Temp_Pre_Alarm" ;
VAL_ 926 FAR_RSM_TempPre 0 "Fehlermoeglichkeit_geprueft" 1 "Fehlermoeglichkeit_nicht_geprueft" ;
VAL_ 926 FAR_EM_UeSpg 0 "kein_Fehler" 1 "Fehler" ;
VAL_ 926 FAR_REM_UeSpg 0 "Fehlermoeglichkeit_geprueft" 1 "Fehlermoeglichkeit_nicht_geprueft" ;
VAL_ 926 FAR_EM_USpg 0 "kein_Fehler" 1 "Fehler" ;
VAL_ 926 FAR_REM_USpg 0 "Fehlermoeglichkeit_geprueft" 1 "Fehlermoeglichkeit_nicht_geprueft" ;
VAL_ 926 FAR_EM_defekt 0 "kein_Fehler" 1 "Fehler" ;
VAL_ 926 FAR_REM_defekt 0 "Fehlermoeglichkeit_geprueft" 1 "Fehlermoeglichkeit_nicht_geprueft" ;
VAL_ 926 FAR_sKL_Lampe 0 "kein_Fehler" 1 "Fehler" ;
VAL_ 926 FAR_RsKL_Lampe 0 "Fehlermoeglichkeit_geprueft" 1 "Fehlermoeglichkeit_nicht_geprueft" ;
VAL_ 926 FAR_sKL_KS_Gnd 0 "kein_Fehler" 1 "Fehler" ;
VAL_ 926 FAR_RsKL_KS_Gnd 0 "Fehlermoeglichkeit_geprueft" 1 "Fehlermoeglichkeit_nicht_geprueft" ;
VAL_ 926 FAR_GDL_Modul 0 "kein_Fehler" 1 "Fehler" ;
VAL_ 926 FAR_RGDL_Modul 0 "Fehlermoeglichkeit_geprueft" 1 "Fehlermoeglichkeit_nicht_geprueft" ;
VAL_ 926 FAR_dKL_KS_Plus 0 "kein_Fehler" 1 "Fehler" ;
VAL_ 926 FAR_RdKL_KS_Plus 0 "Fehlermoeglichkeit_geprueft" 1 "Fehlermoeglichkeit_nicht_geprueft" ;
VAL_ 926 FAR_dKL_KS_Gnd 0 "kein_Fehler" 1 "Fehler" ;
VAL_ 926 FAR_RdKL_KS_Gnd 0 "Fehlermoeglichkeit_geprueft" 1 "Fehlermoeglichkeit_nicht_geprueft" ;
VAL_ 926 FAR_dKL_unplSign 0 "kein_Fehler" 1 "Fehler" ;
VAL_ 926 FAR_RdKL_unplSign 0 "Fehlermoeglichkeit_geprueft" 1 "Fehlermoeglichkeit_nicht_geprueft" ;
VAL_ 926 FAR_5VdKL_KS_Gnd 0 "kein_Fehler" 1 "Fehler" ;
VAL_ 926 FAR_R5VdKL_KS_Gnd 0 "Fehlermoeglichkeit_geprueft" 1 "Fehlermoeglichkeit_nicht_geprueft" ;
VAL_ 926 FAR_5VdKL_KS_UB 0 "kein_Fehler" 1 "Fehler" ;
VAL_ 926 FAR_R5VdKL_KS_UB 0 "Fehlermoeglichkeit_geprueft" 1 "Fehlermoeglichkeit_nicht_geprueft" ;
VAL_ 1176 KAL_BG_LWR_O 4092 "reserviert" 4093 "reserviert" 4094 "Init" 4095 "Fehler" ;
VAL_ 1176 KAL_BG_LWR_U 4092 "reserviert" 4093 "reserviert" 4094 "Init" 4095 "Fehler" ;
VAL_ 1176 KAL_BG_dKL_L 4092 "reserviert" 4093 "reserviert" 4094 "Init" 4095 "Fehler" ;
VAL_ 1176 KAL_BG_dKL_R 4092 "reserviert" 4093 "reserviert" 4094 "Init" 4095 "Fehler" ;
VAL_ 1176 KAL_BG_gLW_O 251 "reserviert" 252 "Blockgrenze_nicht_bedient" 253 "Blockgrenze_oben" 254 "Init" 255 "Fehler" ;
VAL_ 1178 KAR_BG_LWR_O 4092 "reserviert" 4093 "reserviert" 4094 "Init" 4095 "Fehler" ;
VAL_ 1178 KAR_BG_LWR_U 4092 "reserviert" 4093 "reserviert" 4094 "Init" 4095 "Fehler" ;
VAL_ 1178 KAR_BG_dKL_L 4092 "reserviert" 4093 "reserviert" 4094 "Init" 4095 "Fehler" ;
VAL_ 1178 KAR_BG_dKL_R 4092 "reserviert" 4093 "reserviert" 4094 "Init" 4095 "Fehler" ;
VAL_ 1178 KAR_BG_gLW_O 251 "reserviert" 252 "Blockgrenze_nicht_bedient" 253 "Blockgrenze_oben" 254 "Init" 255 "Fehler" ;
VAL_ 402 SOA_SollPos_L 4092 "Blockgrenze_rechts" 4093 "Blockgrenze_links" 4094 "Init" 4095 "Fehler" ;
VAL_ 402 SOA_FehlPos_L 0 "Fehlerfallpos_aus" 1 "Fehlerfallpos_ein" ;
VAL_ 402 SOA_RefLauf_L 0 "Referenzlauf_nicht_angefordert" 1 "Referenzlauf_angefordert" ;
VAL_ 402 SOA_StGlTest_L 0 "Stellgliedtest_nicht_angefordert" 1 "Stellgliedtest_angefordert" ;
VAL_ 402 SOA_StGlDim_L 0 "Stellgliedtest_nicht_angefordert" 1 "Stellgliedtest_angefordert" ;
VAL_ 402 SOA_DimAbLicht_L 255 "Fehler" ;
VAL_ 402 SOA_SollPos_R 4092 "Blockgrenze_rechts" 4093 "Blockgrenze_links" 4094 "Init" 4095 "Fehler" ;
VAL_ 402 SOA_FehlPos_R 0 "Fehlerfallpos_aus" 1 "Fehlerfallpos_ein" ;
VAL_ 402 SOA_RefLauf_R 0 "Referenzlauf_nicht_angefordert" 1 "Referenzlauf_angefordert" ;
VAL_ 402 SOA_StGlTest_R 0 "Stellgliedtest_nicht_angefordert" 1 "Stellgliedtest_angefordert" ;
VAL_ 402 SOA_StGlDim_R 0 "Stellgliedtest_nicht_angefordert" 1 "Stellgliedtest_angefordert" ;
VAL_ 402 SOA_DimAbLicht_R 255 "Fehler" ;
VAL_ 410 SAL_IstPos 4092 "Blockgrenze_rechts" 4093 "Blockgrenze_links" 4094 "Init" 4095 "Fehler" ;
VAL_ 410 SAL_SchwenkRi 0 "Modul_nach_links_geschwenkt" 1 "Modul_nach_rechts_geschwenkt" ;
VAL_ 410 SAL_IstPosMot 254 "Wert_unbekannt" 255 "Fehler" ;
VAL_ 410 SAL_StaVerst 0 "Schrittmotor_steht_still" 1 "Schrittmotor_verstellt" ;
VAL_ 410 SAL_StaFehPos 0 "Fehlerfallpos_nicht_angefahren" 1 "Fehlerfallpos_angefahren" ;
VAL_ 410 SAL_StaReflauf 0 "Reflauf_noch_nicht_erfolgt" 1 "Reflauf_erfolgt" ;
VAL_ 410 SAL_StaStGlTst 0 "Stellgliedtest_nicht_angefordert" 1 "Stellgliedtest_laeuft" ;
VAL_ 410 SAL_StaAbLicht 0 "Stellgliedtest_nicht_angefordert" 1 "Stellgliedtest_laeuft" ;
VAL_ 410 SAL_IstDimAbLi 254 "Wert_unbekannt" 255 "Fehler" ;
VAL_ 410 SAL_VSpg_AFS 254 "Wert_unbekannt" 255 "Fehler" ;
VAL_ 412 SAR_IstPos 4092 "Blockgrenze_rechts" 4093 "Blockgrenze_links" 4094 "Init" 4095 "Fehler" ;
VAL_ 412 SAR_SchwenkRi 0 "Modul_nach_links_geschwenkt" 1 "Modul_nach_rechts_geschwenkt" ;
VAL_ 412 SAR_IstPosMot 254 "Wert_unbekannt" 255 "Fehler" ;
VAL_ 412 SAR_StaVerst 0 "Schrittmotor_steht_still" 1 "Schrittmotor_verstellt" ;
VAL_ 412 SAR_StaFehPos 0 "Fehlerfallpos_nicht_angefahren" 1 "Fehlerfallpos_angefahren" ;
VAL_ 412 SAR_StaReflauf 0 "Reflauf_noch_nicht_erfolgt" 1 "Reflauf_erfolgt" ;
VAL_ 412 SAR_StaStGlTst 0 "Stellgliedtest_nicht_angefordert" 1 "Stellgliedtest_laeuft" ;
VAL_ 412 SAR_StaAbLicht 0 "Stellgliedtest_nicht_angefordert" 1 "Stellgliedtest_laeuft" ;
VAL_ 412 SAR_IstDimAbRe 254 "Wert_unbekannt" 255 "Fehler" ;
VAL_ 412 SAR_VSpg_AFS 254 "Wert_unbekannt" 255 "Fehler" ;
VAL_ 64 AB_RGS_Anst 4 "aktiv_Niveau_1" 5 "aktiv_Niveau_2" 6 "aktiv_Niveau_3" 7 "aktiv_Niveau_4" 8 "deaktiviert" ;
VAL_ 64 AB_Front_Crash 0 "kein_Front_Crash" 1 "Front_Crash" ;
VAL_ 64 AB_Heck_Crash 0 "kein_Heck_Crash" 1 "Heck_Crash" ;
VAL_ 64 AB_SF_Crash 0 "kein_Seiten_Crash_Fahrer" 1 "Seiten_Crash_Fahrer" ;
VAL_ 64 AB_SB_Crash 0 "kein_Seiten_Crash_Beifahrer" 1 "Seiten_Crash_Beifahrer" ;
VAL_ 64 AB_Rollover_Crash 0 "kein_Rollover" 1 "Rollover" ;
VAL_ 64 AB_Crash_Int 0 "kein_Crash" 1 "Crash_Intensitaet_1" 2 "Crash_Intensitaet_2_(nur_Stellgliedtest_MLB_B8)" 3 "Crash_Intensitaet_2_(nur_D4_C7_Colorado_NF_PAG__Crash_im_MLB_B8)" 4 "Crash_Intensitaet_3_(alt_VW/AUDI__Stellgliedtest_MLB_B8)" 5 "Crash_Intensitaet_3_(alt_PAG)" 7 "Crash_Intensitaet_3" ;
VAL_ 64 AB_Lampe 0 "Aus" 1 "Ein" ;
VAL_ 64 AB_Deaktiviert 0 "aktiv" 1 "deaktiviert" ;
VAL_ 64 AB_VB_deaktiviert 0 "Beifahrerairbag_aktiv" 1 "Beifahrerairbag_deaktiviert" ;
VAL_ 64 AB_Systemfehler 0 "kein_Fehler" 1 "Airbag_Systemfehler" ;
VAL_ 64 AB_Diagnose 0 "nicht_in_Diagnose" 1 "in_Diagnose" ;
VAL_ 64 AB_Stellgliedtest 0 "nicht_im_Stellgliedtest" 1 "Airbag_im_Stellgliedtest" ;
VAL_ 64 AB_Erh_Auf_VB 0 "keine_Anzeige" 1 "Beifahrerairbag_deaktiviert" 2 "Beifahrerairbag_aktiviert" 3 "nicht_definiert" ;
VAL_ 64 AB_Gurtwarn_VF 0 "keine_Warnung" 1 "Gurtwarnung_ausloesen" ;
VAL_ 64 AB_Gurtwarn_VB 0 "keine_Warnung" 1 "Gurtwarnung_ausloesen" ;
VAL_ 64 AB_Anzeige_Fussg 0 "keine_FSG_Aktion_ausgeloest" 1 "Motorhaube_offen" 2 "Systemfehler" ;
VAL_ 64 AB_Texte_AKS 0 "keine_AKS_Ausloesung" 1 "AKS_ausgeloest" 2 "AKS_Systemfehler" ;
VAL_ 64 AB_MKB_gueltig 0 "Multikollisionsbremsung_nicht_freigeschaltet" 1 "Multikollisionsbremsung_freigeschaltet" ;
VAL_ 64 AB_MKB_Anforderung 0 "Multikollisionsbremsung_nicht_angefordert" 1 "Multikollisionsbremsung_angefordert" ;
VAL_ 64 AB_Versorgungsspannung 0 "plausibel" 1 "unplausibel" ;
VAL_ 64 AB_Deaktivierung_HV 0 "keine_Deaktivierung" 1 "Deaktivierung_1" 2 "Deaktivierung_2" 3 "Deaktivierung_3" 4 "Deaktivierung_4" 5 "Deaktivierung_5" 6 "Deaktivierung_6" 7 "Fehler" ;
VAL_ 64 AB_EDR_Trigger 0 "No_Event" 1 "Start_Event" 2 "NonDeployment_Event" 3 "Deployment_Event" ;
VAL_ 64 SC_LowSpeedCrashErkannt 0 "kein_Crash_erkannt" 1 "Crash_Frontbereich_erkannt" 2 "Crash_Heckbereich_erkannt" 3 "Crash_Front_und_Heckbereich_erkannt" ;
VAL_ 64 SC_Masterzeit 127 "Init" ;
VAL_ 2463978618 BCM1_Laser_Freigabe 0 "nicht_angefordert" 1 "angefordert" ;
VAL_ 2463978618 AFS_Gelaendelicht_Anf 0 "nicht_angefordert" 1 "angefordert" ;
VAL_ 2463978618 AFS_PAHS_L_Status 0 "nicht_angefordert_oder_nicht_bereit" 1 "Pos_erreicht" ;
VAL_ 2463978618 AFS_PAHS_R_Status 0 "nicht_angefordert_oder_nicht_bereit" 1 "Pos_erreicht" ;
VAL_ 2463978618 BCM1_Gleitende_Leuchtw_Anf 0 "Aus" 1 "Ein" ;
VAL_ 2463978618 BCM1_GLW_Fernlicht_Anf 0 "Aus" 1 "Ein" ;
VAL_ 821 SOA_Offset_L 4092 "Blockgrenze_rechts" 4093 "Blockgrenze_links" 4094 "Init" 4095 "Fehler" ;
VAL_ 821 SOA_Offset_R 4092 "Blockgrenze_rechts" 4093 "Blockgrenze_links" 4094 "Init" 4095 "Fehler" ;
VAL_ 821 SOL_Offset_L 4092 "reserviert" 4093 "Blockgrenze_unten" 4094 "Init" 4095 "Fehler" ;
VAL_ 821 SOL_Offset_R 4092 "reserviert" 4093 "Blockgrenze_unten" 4094 "Init" 4095 "Fehler" ;
VAL_ 1714 DGN_Verlernzaehler 255 "ungültiger Zählerstand oder kein gültiger Fahrzyklus" ;
VAL_ 1714 KBI_Kilometerstand 1048574 "Init" 1048575 "Fehler" ;
VAL_ 1714 UH_Monat 0 "Init" 14 "reserviert" 15 "Fehler" ;
VAL_ 1714 UH_Tag 0 "Init" ;
VAL_ 253 BR_Eingriffsmoment 1022 "Init" 1023 "Fehler" ;
VAL_ 253 ESP_PLA_Bremseingriff 0 "inaktiv" 1 "aktiv" ;
VAL_ 253 ESP_Diagnose 0 "ESP_nicht_in_Diagnose" 1 "ESP_in_Diagnose" ;
VAL_ 253 ESC_v_Signal_Qualifier_High_Low 0 "Gueteschwelle_kleiner_1kmh" 1 "Gueteschwelle_kleiner_3kmh" 2 "Gueteschwelle_kleiner_5kmh" 3 "Gueteschwelle_kleiner_10kmh" 4 "Gueteschwelle_kleiner_20kmh" 5 "Gueteschwelle_groessergleich_20kmh" 6 "Init" 7 "Fehler" ;
VAL_ 253 ESP_Vorsteuerung 0 "keine_Vorsteuerung_aktiv" 1 "Vorsteuerung_aktiv" ;
VAL_ 253 OBD_Schlechtweg 0 "kein_Schlechtweg_erkannt" 1 "Schlechtweg_erkannt" ;
VAL_ 253 OBD_QBit_Schlechtweg 0 "gueltiger_Wert" 1 "Ersatz_Init_oder_Fehlerwert" ;
VAL_ 253 ESP_v_Signal 65533 "Unterspannung" 65534 "Init" 65535 "Fehler" ;
VAL_ 253 ASR_Tastung_passiv 0 "ASR_aktiviert" 1 "ASR_passiv_getastet_oder_Schwellen_geaendert" ;
VAL_ 253 ESP_Tastung_passiv 0 "ESP_aktiviert" 1 "ESP_passiv_getastet_oder_Schwellen_geaendert" ;
VAL_ 253 ESP_Systemstatus 0 "iO" 1 "Fehler" ;
VAL_ 253 ASR_Schalteingriff 0 "keine_Anforderung" 1 "ASR_Schaltkennfeld" 2 "Rueckschaltung" 3 "Schaltverbot" ;
VAL_ 253 ESP_Haltebestaetigung 0 "kein_sicheres_Halten" 1 "sicheres_Halten" ;
VAL_ 253 ESP_MKB_Abbruch_Geschw 0 "MKB_nicht_beendet_wg_v_Schwelle" 1 "MKB_beendet_wg_v_Schwelle" ;
VAL_ 253 ESP_QBit_v_Signal 0 "gueltiger_Wert" 1 "Ersatz_Init_oder_Fehlerwert" ;
VAL_ 253 ABS_Bremsung 0 "keine_ABS_Regelung" 1 "ABS_Regelung_aktiv" ;
VAL_ 253 ASR_Anf 0 "keine_Anforderung" 1 "ASR_Anforderung" ;
VAL_ 253 MSR_Anf 0 "keine Anfoderung" 1 "MSR-Anforderung" ;
VAL_ 253 EBV_Eingriff 0 "kein_EBV_Eingriff" 1 "EBV_Eingriff" ;
VAL_ 253 EDS_Eingriff 0 "kein_EDS_Eingriff" 1 "EDS_Eingriff" ;
VAL_ 253 ESP_Eingriff 0 "kein_ESP_Eingriff" 1 "ESP_Eingriff_aktiv" ;
VAL_ 253 ESP_ASP 0 "inaktiv" 1 "aktiv" ;
VAL_ 918 FGL_Akt_KS_Plus 0 "kein_Fehler" 1 "Fehler" ;
VAL_ 918 FGL_RAkt_KS_Plus 0 "Fehlermoeglichkeit_geprueft" 1 "Fehlermoeglichkeit_nicht_geprueft" ;
VAL_ 918 FGL_Akt_KS_Gnd 0 "kein_Fehler" 1 "Fehler" ;
VAL_ 918 FGL_RAkt_KS_Gnd 0 "Fehlermoeglichkeit_geprueft" 1 "Fehlermoeglichkeit_nicht_geprueft" ;
VAL_ 918 FGL_Akt_OL 0 "kein_Fehler" 1 "Fehler" ;
VAL_ 918 FGL_RAkt_OL 0 "Fehlermoeglichkeit_geprueft" 1 "Fehlermoeglichkeit_nicht_geprueft" ;
VAL_ 918 FGL_Akt_UeSpg 0 "kein_Fehler" 1 "Fehler" ;
VAL_ 918 FGL_RAkt_UeSpg 0 "Fehlermoeglichkeit_geprueft" 1 "Fehlermoeglichkeit_nicht_geprueft" ;
VAL_ 918 FGL_Akt_USpg 0 "kein_Fehler" 1 "Fehler" ;
VAL_ 918 FGL_RAkt_USpg 0 "Fehlermoeglichkeit_geprueft" 1 "Fehlermoeglichkeit_nicht_geprueft" ;
VAL_ 918 FGL_Akt_UeTemp 0 "kein_Fehler" 1 "Fehler" ;
VAL_ 918 FGL_RAkt_UeTemp 0 "Fehlermoeglichkeit_geprueft" 1 "Fehlermoeglichkeit_nicht_geprueft" ;
VAL_ 918 FGL_Akt_TempPre 0 "kein_Fehler" 1 "Temp_Pre_Alarm" ;
VAL_ 918 FGL_RAkt_TempPre 0 "Fehlermoeglichkeit_geprueft" 1 "Fehlermoeglichkeit_nicht_geprueft" ;
VAL_ 918 FGL_HS_KS_Plus 0 "kein_Fehler" 1 "Fehler" ;
VAL_ 918 FGL_RHS_KS_Plus 0 "Fehlermoeglichkeit_geprueft" 1 "Fehlermoeglichkeit_nicht_geprueft" ;
VAL_ 918 FGL_HS_KS_Gnd 0 "kein_Fehler" 1 "Fehler" ;
VAL_ 918 FGL_RHS_KS_Gnd 0 "Fehlermoeglichkeit_geprueft" 1 "Fehlermoeglichkeit_nicht_geprueft" ;
VAL_ 918 FGL_HS_unplSign 0 "kein_Fehler" 1 "Fehler" ;
VAL_ 918 FGL_RHS_unplSign 0 "Fehlermoeglichkeit_geprueft" 1 "Fehlermoeglichkeit_nicht_geprueft" ;
VAL_ 918 FGL_LIN_Def 0 "kein_Fehler" 1 "Fehler" ;
VAL_ 918 FGL_LIN_Timeout 0 "kein_Fehler" 1 "Fehler" ;
VAL_ 918 FGL_RLIN_Def 0 "Fehlermoeglichkeit_geprueft" 1 "Fehlermoeglichkeit_nicht_geprueft" ;
VAL_ 918 FGL_RLIN_Timeout 0 "Fehlermoeglichkeit_geprueft" 1 "Fehlermoeglichkeit_nicht_geprueft" ;
